VERSION ""

NS_ :

BS_:

BU_: MVS RCR_R RCR_L SNR ADAS ADAS_GW ENM THM CHR BAT BEV BEV_GW MET C_ECU C_ECU_GW

BO_ 2564481196 MVS18DAE0AC: 64 MVS
 SG_ MVS18DAE0AC_DIAG_DATA_EXT7 : 455|64@0+ (1,0) [0|1.844674407371E+19] ""  C_ECU_GW
 SG_ MVS18DAE0AC_DIAG_DATA_EXT6 : 391|64@0+ (1,0) [0|1.844674407371E+19] ""  C_ECU_GW
 SG_ MVS18DAE0AC_DIAG_DATA_EXT5 : 327|64@0+ (1,0) [0|1.844674407371E+19] ""  C_ECU_GW
 SG_ MVS18DAE0AC_DIAG_DATA_EXT4 : 263|64@0+ (1,0) [0|1.844674407371E+19] ""  C_ECU_GW
 SG_ MVS18DAE0AC_DIAG_DATA_EXT3 : 199|64@0+ (1,0) [0|1.844674407371E+19] ""  C_ECU_GW
 SG_ MVS18DAE0AC_DIAG_DATA_EXT2 : 135|64@0+ (1,0) [0|1.844674407371E+19] ""  C_ECU_GW
 SG_ MVS18DAE0AC_DIAG_DATA_EXT1 : 71|64@0+ (1,0) [0|1.844674407371E+19] ""  C_ECU_GW
 SG_ MVS18DAE0AC_DIAG_DATA : 7|64@0+ (1,0) [0|1.844674407371E+19] ""  C_ECU_GW

BO_ 2564467936 DNT18DAACE0: 64 C_ECU_GW
 SG_ DNT18DAACE0_DIAG_DATA_EXT7 : 455|64@0+ (1,0) [0|1.844674407371E+19] ""  MVS
 SG_ DNT18DAACE0_DIAG_DATA_EXT6 : 391|64@0+ (1,0) [0|1.844674407371E+19] ""  MVS
 SG_ DNT18DAACE0_DIAG_DATA_EXT5 : 327|64@0+ (1,0) [0|1.844674407371E+19] ""  MVS
 SG_ DNT18DAACE0_DIAG_DATA_EXT4 : 263|64@0+ (1,0) [0|1.844674407371E+19] ""  MVS
 SG_ DNT18DAACE0_DIAG_DATA_EXT3 : 199|64@0+ (1,0) [0|1.844674407371E+19] ""  MVS
 SG_ DNT18DAACE0_DIAG_DATA_EXT2 : 135|64@0+ (1,0) [0|1.844674407371E+19] ""  MVS
 SG_ DNT18DAACE0_DIAG_DATA_EXT1 : 71|64@0+ (1,0) [0|1.844674407371E+19] ""  MVS
 SG_ DNT18DAACE0_DIAG_DATA : 7|64@0+ (1,0) [0|1.844674407371E+19] ""  MVS

BO_ 2564481213 RCR18DAE0BD: 8 RCR_R
 SG_ RCR18DAE0BD_DIAG_DATA : 7|64@0+ (1,0) [0|1.844674407371E+19] ""  C_ECU_GW

BO_ 2564472288 DNT18DABDE0: 8 C_ECU_GW
 SG_ DNT18DABDE0_DIAG_DATA : 7|64@0+ (1,0) [0|1.844674407371E+19] ""  RCR_R

BO_ 2564481212 RCR18DAE0BC: 8 RCR_L
 SG_ RCR18DAE0BC_DIAG_DATA : 7|64@0+ (1,0) [0|1.844674407371E+19] ""  C_ECU_GW

BO_ 2564472032 DNT18DABCE0: 8 C_ECU_GW
 SG_ DNT18DABCE0_DIAG_DATA : 7|64@0+ (1,0) [0|1.844674407371E+19] ""  RCR_L

BO_ 2564481195 SNR18DAE0AB: 64 SNR
 SG_ SNR18DAE0AB_DIAG_DATA_EXT7 : 455|64@0+ (1,0) [0|1.844674407371E+19] ""  C_ECU_GW
 SG_ SNR18DAE0AB_DIAG_DATA_EXT6 : 391|64@0+ (1,0) [0|1.844674407371E+19] ""  C_ECU_GW
 SG_ SNR18DAE0AB_DIAG_DATA_EXT5 : 327|64@0+ (1,0) [0|1.844674407371E+19] ""  C_ECU_GW
 SG_ SNR18DAE0AB_DIAG_DATA_EXT4 : 263|64@0+ (1,0) [0|1.844674407371E+19] ""  C_ECU_GW
 SG_ SNR18DAE0AB_DIAG_DATA_EXT3 : 199|64@0+ (1,0) [0|1.844674407371E+19] ""  C_ECU_GW
 SG_ SNR18DAE0AB_DIAG_DATA_EXT2 : 135|64@0+ (1,0) [0|1.844674407371E+19] ""  C_ECU_GW
 SG_ SNR18DAE0AB_DIAG_DATA_EXT1 : 71|64@0+ (1,0) [0|1.844674407371E+19] ""  C_ECU_GW
 SG_ SNR18DAE0AB_DIAG_DATA : 7|64@0+ (1,0) [0|1.844674407371E+19] ""  C_ECU_GW

BO_ 2564467680 DNT18DAABE0: 64 C_ECU_GW
 SG_ DNT18DAABE0_DIAG_DATA_EXT7 : 455|64@0+ (1,0) [0|1.844674407371E+19] ""  SNR
 SG_ DNT18DAABE0_DIAG_DATA_EXT6 : 391|64@0+ (1,0) [0|1.844674407371E+19] ""  SNR
 SG_ DNT18DAABE0_DIAG_DATA_EXT5 : 327|64@0+ (1,0) [0|1.844674407371E+19] ""  SNR
 SG_ DNT18DAABE0_DIAG_DATA_EXT4 : 263|64@0+ (1,0) [0|1.844674407371E+19] ""  SNR
 SG_ DNT18DAABE0_DIAG_DATA_EXT3 : 199|64@0+ (1,0) [0|1.844674407371E+19] ""  SNR
 SG_ DNT18DAABE0_DIAG_DATA_EXT2 : 135|64@0+ (1,0) [0|1.844674407371E+19] ""  SNR
 SG_ DNT18DAABE0_DIAG_DATA_EXT1 : 71|64@0+ (1,0) [0|1.844674407371E+19] ""  SNR
 SG_ DNT18DAABE0_DIAG_DATA : 7|64@0+ (1,0) [0|1.844674407371E+19] ""  SNR

BO_ 2564481047 MET18DAE017: 64 MET
 SG_ MET18DAE017_DIAG_DATA_EXT7 : 455|64@0+ (1,0) [0|1.844674407371E+19] ""  C_ECU_GW
 SG_ MET18DAE017_DIAG_DATA_EXT6 : 391|64@0+ (1,0) [0|1.844674407371E+19] ""  C_ECU_GW
 SG_ MET18DAE017_DIAG_DATA_EXT5 : 327|64@0+ (1,0) [0|1.844674407371E+19] ""  C_ECU_GW
 SG_ MET18DAE017_DIAG_DATA_EXT4 : 263|64@0+ (1,0) [0|1.844674407371E+19] ""  C_ECU_GW
 SG_ MET18DAE017_DIAG_DATA_EXT3 : 199|64@0+ (1,0) [0|1.844674407371E+19] ""  C_ECU_GW
 SG_ MET18DAE017_DIAG_DATA_EXT2 : 135|64@0+ (1,0) [0|1.844674407371E+19] ""  C_ECU_GW
 SG_ MET18DAE017_DIAG_DATA_EXT1 : 71|64@0+ (1,0) [0|1.844674407371E+19] ""  C_ECU_GW
 SG_ MET18DAE017_DIAG_DATA : 7|64@0+ (1,0) [0|1.844674407371E+19] ""  C_ECU_GW

BO_ 2564429792 DNT18DA17E0: 64 C_ECU_GW
 SG_ DNT18DA17E0_DIAG_DATA_EXT7 : 455|64@0+ (1,0) [0|1.844674407371E+19] ""  MET
 SG_ DNT18DA17E0_DIAG_DATA_EXT6 : 391|64@0+ (1,0) [0|1.844674407371E+19] ""  MET
 SG_ DNT18DA17E0_DIAG_DATA_EXT5 : 327|64@0+ (1,0) [0|1.844674407371E+19] ""  MET
 SG_ DNT18DA17E0_DIAG_DATA_EXT4 : 263|64@0+ (1,0) [0|1.844674407371E+19] ""  MET
 SG_ DNT18DA17E0_DIAG_DATA_EXT3 : 199|64@0+ (1,0) [0|1.844674407371E+19] ""  MET
 SG_ DNT18DA17E0_DIAG_DATA_EXT2 : 135|64@0+ (1,0) [0|1.844674407371E+19] ""  MET
 SG_ DNT18DA17E0_DIAG_DATA_EXT1 : 71|64@0+ (1,0) [0|1.844674407371E+19] ""  MET
 SG_ DNT18DA17E0_DIAG_DATA : 7|64@0+ (1,0) [0|1.844674407371E+19] ""  MET

BO_ 2564550625 CECU18DBEFE1: 8 C_ECU
 SG_ CECU18DBEFE1_DIAG_DATA : 7|64@0+ (1,0) [0|1.844674407371E+19] ""  MVS,RCR_R,RCR_L,SNR,ADAS,MET

BO_ 2564550624 DNT18DBEFE0: 8 C_ECU_GW
 SG_ DNT18DBEFE0_DIAG_DATA : 7|64@0+ (1,0) [0|1.844674407371E+19] ""  MVS,RCR_R,RCR_L,SNR,MET

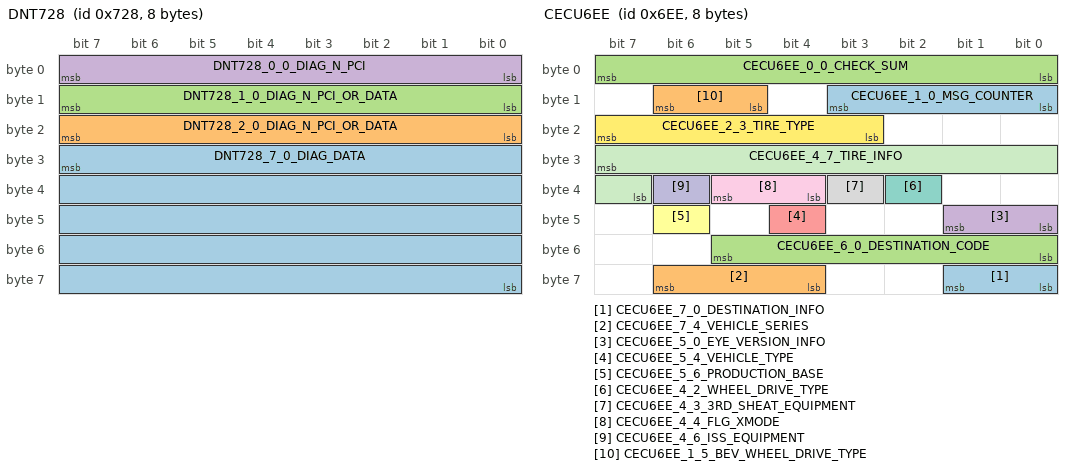
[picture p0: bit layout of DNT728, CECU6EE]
BO_ 1832 DNT728: 8 C_ECU_GW
 SG_ DNT728_7_0_DIAG_DATA : 31|40@0+ (1,0) [0|1099511627775] "" Vector__XXX
 SG_ DNT728_2_0_DIAG_N_PCI_OR_DATA : 23|8@0+ (1,0) [0|255] "" Vector__XXX
 SG_ DNT728_1_0_DIAG_N_PCI_OR_DATA : 15|8@0+ (1,0) [0|255] "" Vector__XXX
 SG_ DNT728_0_0_DIAG_N_PCI : 7|8@0+ (1,0) [0|255] "" Vector__XXX

BO_ 2564481303 MET18DAE117: 64 MET
 SG_ MET18DAE117_DIAG_DATA_EXT7 : 455|64@0+ (1,0) [0|1.844674407371E+19] ""  C_ECU
 SG_ MET18DAE117_DIAG_DATA_EXT6 : 391|64@0+ (1,0) [0|1.844674407371E+19] ""  C_ECU
 SG_ MET18DAE117_DIAG_DATA_EXT5 : 327|64@0+ (1,0) [0|1.844674407371E+19] ""  C_ECU
 SG_ MET18DAE117_DIAG_DATA_EXT4 : 263|64@0+ (1,0) [0|1.844674407371E+19] ""  C_ECU
 SG_ MET18DAE117_DIAG_DATA_EXT3 : 199|64@0+ (1,0) [0|1.844674407371E+19] ""  C_ECU
 SG_ MET18DAE117_DIAG_DATA_EXT2 : 135|64@0+ (1,0) [0|1.844674407371E+19] ""  C_ECU
 SG_ MET18DAE117_DIAG_DATA_EXT1 : 71|64@0+ (1,0) [0|1.844674407371E+19] ""  C_ECU
 SG_ MET18DAE117_DIAG_DATA : 7|64@0+ (1,0) [0|1.844674407371E+19] ""  C_ECU

BO_ 2564429793 CECU18DA17E1: 64 C_ECU
 SG_ CECU18DA17E1_DIAG_DATA_EXT7 : 455|64@0+ (1,0) [0|1.844674407371E+19] ""  MET
 SG_ CECU18DA17E1_DIAG_DATA_EXT6 : 391|64@0+ (1,0) [0|1.844674407371E+19] ""  MET
 SG_ CECU18DA17E1_DIAG_DATA_EXT5 : 327|64@0+ (1,0) [0|1.844674407371E+19] ""  MET
 SG_ CECU18DA17E1_DIAG_DATA_EXT4 : 263|64@0+ (1,0) [0|1.844674407371E+19] ""  MET
 SG_ CECU18DA17E1_DIAG_DATA_EXT3 : 199|64@0+ (1,0) [0|1.844674407371E+19] ""  MET
 SG_ CECU18DA17E1_DIAG_DATA_EXT2 : 135|64@0+ (1,0) [0|1.844674407371E+19] ""  MET
 SG_ CECU18DA17E1_DIAG_DATA_EXT1 : 71|64@0+ (1,0) [0|1.844674407371E+19] ""  MET
 SG_ CECU18DA17E1_DIAG_DATA : 7|64@0+ (1,0) [0|1.844674407371E+19] ""  MET

BO_ 2564481452 MVS18DAE1AC: 64 MVS
 SG_ MVS18DAE1AC_DIAG_DATA_EXT7 : 455|64@0+ (1,0) [0|1.844674407371E+19] ""  C_ECU
 SG_ MVS18DAE1AC_DIAG_DATA_EXT6 : 391|64@0+ (1,0) [0|1.844674407371E+19] ""  C_ECU
 SG_ MVS18DAE1AC_DIAG_DATA_EXT5 : 327|64@0+ (1,0) [0|1.844674407371E+19] ""  C_ECU
 SG_ MVS18DAE1AC_DIAG_DATA_EXT4 : 263|64@0+ (1,0) [0|1.844674407371E+19] ""  C_ECU
 SG_ MVS18DAE1AC_DIAG_DATA_EXT3 : 199|64@0+ (1,0) [0|1.844674407371E+19] ""  C_ECU
 SG_ MVS18DAE1AC_DIAG_DATA_EXT2 : 135|64@0+ (1,0) [0|1.844674407371E+19] ""  C_ECU
 SG_ MVS18DAE1AC_DIAG_DATA_EXT1 : 71|64@0+ (1,0) [0|1.844674407371E+19] ""  C_ECU
 SG_ MVS18DAE1AC_DIAG_DATA : 7|64@0+ (1,0) [0|1.844674407371E+19] ""  C_ECU

BO_ 2564467937 CECU18DAACE1: 64 C_ECU
 SG_ CECU18DAACE1_DIAG_DATA_EXT7 : 455|64@0+ (1,0) [0|1.844674407371E+19] ""  MVS
 SG_ CECU18DAACE1_DIAG_DATA_EXT6 : 391|64@0+ (1,0) [0|1.844674407371E+19] ""  MVS
 SG_ CECU18DAACE1_DIAG_DATA_EXT5 : 327|64@0+ (1,0) [0|1.844674407371E+19] ""  MVS
 SG_ CECU18DAACE1_DIAG_DATA_EXT4 : 263|64@0+ (1,0) [0|1.844674407371E+19] ""  MVS
 SG_ CECU18DAACE1_DIAG_DATA_EXT3 : 199|64@0+ (1,0) [0|1.844674407371E+19] ""  MVS
 SG_ CECU18DAACE1_DIAG_DATA_EXT2 : 135|64@0+ (1,0) [0|1.844674407371E+19] ""  MVS
 SG_ CECU18DAACE1_DIAG_DATA_EXT1 : 71|64@0+ (1,0) [0|1.844674407371E+19] ""  MVS
 SG_ CECU18DAACE1_DIAG_DATA : 7|64@0+ (1,0) [0|1.844674407371E+19] ""  MVS

BO_ 2564481451 SNR18DAE1AB: 64 SNR
 SG_ SNR18DAE1AB_DIAG_DATA_EXT7 : 455|64@0+ (1,0) [0|1.844674407371E+19] ""  C_ECU
 SG_ SNR18DAE1AB_DIAG_DATA_EXT6 : 391|64@0+ (1,0) [0|1.844674407371E+19] ""  C_ECU
 SG_ SNR18DAE1AB_DIAG_DATA_EXT5 : 327|64@0+ (1,0) [0|1.844674407371E+19] ""  C_ECU
 SG_ SNR18DAE1AB_DIAG_DATA_EXT4 : 263|64@0+ (1,0) [0|1.844674407371E+19] ""  C_ECU
 SG_ SNR18DAE1AB_DIAG_DATA_EXT3 : 199|64@0+ (1,0) [0|1.844674407371E+19] ""  C_ECU
 SG_ SNR18DAE1AB_DIAG_DATA_EXT2 : 135|64@0+ (1,0) [0|1.844674407371E+19] ""  C_ECU
 SG_ SNR18DAE1AB_DIAG_DATA_EXT1 : 71|64@0+ (1,0) [0|1.844674407371E+19] ""  C_ECU
 SG_ SNR18DAE1AB_DIAG_DATA : 7|64@0+ (1,0) [0|1.844674407371E+19] ""  C_ECU

BO_ 2564467681 CECU18DAABE1: 64 C_ECU
 SG_ CECU18DAABE1_DIAG_DATA_EXT7 : 455|64@0+ (1,0) [0|1.844674407371E+19] ""  SNR
 SG_ CECU18DAABE1_DIAG_DATA_EXT6 : 391|64@0+ (1,0) [0|1.844674407371E+19] ""  SNR
 SG_ CECU18DAABE1_DIAG_DATA_EXT5 : 327|64@0+ (1,0) [0|1.844674407371E+19] ""  SNR
 SG_ CECU18DAABE1_DIAG_DATA_EXT4 : 263|64@0+ (1,0) [0|1.844674407371E+19] ""  SNR
 SG_ CECU18DAABE1_DIAG_DATA_EXT3 : 199|64@0+ (1,0) [0|1.844674407371E+19] ""  SNR
 SG_ CECU18DAABE1_DIAG_DATA_EXT2 : 135|64@0+ (1,0) [0|1.844674407371E+19] ""  SNR
 SG_ CECU18DAABE1_DIAG_DATA_EXT1 : 71|64@0+ (1,0) [0|1.844674407371E+19] ""  SNR
 SG_ CECU18DAABE1_DIAG_DATA : 7|64@0+ (1,0) [0|1.844674407371E+19] ""  SNR

BO_ 2564481469 RCR18DAE1BD: 8 RCR_R
 SG_ RCR18DAE1BD_DIAG_DATA : 7|64@0+ (1,0) [0|1.844674407371E+19] ""  C_ECU

BO_ 2564472289 CECU18DABDE1: 8 C_ECU
 SG_ CECU18DABDE1_DIAG_DATA : 7|64@0+ (1,0) [0|1.844674407371E+19] ""  RCR_R

BO_ 2564481468 RCR18DAE1BC: 8 RCR_L
 SG_ RCR18DAE1BC_DIAG_DATA : 7|64@0+ (1,0) [0|1.844674407371E+19] ""  C_ECU

BO_ 2564472033 CECU18DABCE1: 8 C_ECU
 SG_ CECU18DABCE1_DIAG_DATA : 7|64@0+ (1,0) [0|1.844674407371E+19] ""  RCR_L

BO_ 1774 CECU6EE: 8 C_ECU
 SG_ CECU6EE_7_0_DESTINATION_INFO : 57|2@0+ (1,0) [0|3] ""  SNR
 SG_ CECU6EE_7_4_VEHICLE_SERIES : 62|3@0+ (1,0) [0|7] ""  RCR_R,RCR_L,SNR,ADAS
 SG_ CECU6EE_6_0_DESTINATION_CODE : 53|6@0+ (1,0) [0|37] ""  RCR_R,RCR_L,SNR,ADAS,CHR
 SG_ CECU6EE_5_0_EYE_VERSION_INFO : 41|2@0+ (1,0) [0|3] "" Vector__XXX
 SG_ CECU6EE_5_4_VEHICLE_TYPE : 44|1@0+ (1,0) [0|1] ""  RCR_R,RCR_L,SNR
 SG_ CECU6EE_5_6_PRODUCTION_BASE : 46|1@0+ (1,0) [0|1] "" Vector__XXX
 SG_ CECU6EE_4_2_WHEEL_DRIVE_TYPE : 34|1@0+ (1,0) [0|1] ""  SNR
 SG_ CECU6EE_4_3_3RD_SHEAT_EQUIPMENT : 35|1@0+ (1,0) [0|1] "" Vector__XXX
 SG_ CECU6EE_4_4_FLG_XMODE : 37|2@0+ (1,0) [0|3] "" Vector__XXX
 SG_ CECU6EE_4_6_ISS_EQUIPMENT : 38|1@0+ (1,0) [0|1] ""  SNR,ADAS
 SG_ CECU6EE_4_7_TIRE_INFO : 31|9@0+ (1,0) [0|381] ""  SNR
 SG_ CECU6EE_2_3_TIRE_TYPE : 23|5@0+ (1,0) [0|511] "" Vector__XXX
 SG_ CECU6EE_1_0_MSG_COUNTER : 11|4@0+ (1,0) [0|15] ""  RCR_R,RCR_L,SNR,ADAS,CHR
 SG_ CECU6EE_1_5_BEV_WHEEL_DRIVE_TYPE : 14|2@0+ (1,0) [0|3] ""  ADAS
 SG_ CECU6EE_0_0_CHECK_SUM : 7|8@0+ (1,0) [0|255] ""  RCR_R,RCR_L,SNR,ADAS,CHR

BO_ 1773 CECU6ED: 8 C_ECU
 SG_ CECU6ED_7_0_VEHICLE_TYPE_DETAIL : 59|4@0+ (1,0) [0|15] ""  MVS,RCR_R,RCR_L,SNR,ADAS
 SG_ CECU6ED_7_7_STEERHEAT_EQUIPMENT : 63|1@0+ (1,0) [0|1] "" Vector__XXX
 SG_ CECU6ED_6_0_SRH_EQUIPMENT : 48|1@0+ (1,0) [0|1] "" Vector__XXX
 SG_ CECU6ED_6_1_EMBENAVI_EQUIPMENT : 49|1@0+ (1,0) [0|1] "" Vector__XXX
 SG_ CECU6ED_6_2_RAB_EQUIPMENT_INFO : 50|1@0+ (1,0) [0|1] "" Vector__XXX
 SG_ CECU6ED_6_3_RRHEACON_EQUIPMENT : 51|1@0+ (1,0) [0|1] "" Vector__XXX
 SG_ CECU6ED_6_4_AUTOMIRROR_EQUIPMENT : 52|1@0+ (1,0) [0|1] "" Vector__XXX
 SG_ CECU6ED_6_5_SXMANTENNA_EQUIPMENT : 53|1@0+ (1,0) [0|1] "" Vector__XXX
 SG_ CECU6ED_6_7_SPORTSCONT_EQUIPMENT : 55|1@0+ (1,0) [0|1] "" Vector__XXX
 SG_ CECU6ED_5_0_TRANSMISSION_TYPE : 40|1@0+ (1,0) [0|1] ""  MVS,SNR
 SG_ CECU6ED_5_2_KICKSENSOR_EQUIPMENT : 42|1@0+ (1,0) [0|1] "" Vector__XXX
 SG_ CECU6ED_5_3_RRSEAT_OCCUPANT : 43|1@0+ (1,0) [0|1] "" Vector__XXX
 SG_ CECU6ED_5_4_HANDLE : 44|1@0+ (1,0) [0|1] ""  MVS,ADAS
 SG_ CECU6ED_5_5_RRWIPER_EQUIPMENT : 45|1@0+ (1,0) [0|1] "" Vector__XXX
 SG_ CECU6ED_5_7_SRM_EQUIPMENT : 47|1@0+ (1,0) [0|1] "" Vector__XXX
 SG_ CECU6ED_4_0_VEHICLE_HEIGHT : 34|3@0+ (1,0) [0|7] ""  MVS,RCR_R,RCR_L,SNR,ADAS
 SG_ CECU6ED_4_4_SEATHEATER_EQUIPMENT : 37|2@0+ (1,0) [0|3] "" Vector__XXX
 SG_ CECU6ED_3_0_YEAR_CHANGE : 27|4@0+ (1,0) [0|15] ""  RCR_R,RCR_L
 SG_ CECU6ED_3_4_HEV_INFO : 30|3@0+ (1,0) [0|7] ""  MVS,RCR_R,RCR_L,SNR,ADAS
 SG_ CECU6ED_2_0_RRDIFF_TEMPLAMP_INFO : 17|2@0+ (1,0) [0|3] "" Vector__XXX
 SG_ CECU6ED_2_2_AHL_EQUIPMENT : 19|2@0+ (1,0) [0|3] "" Vector__XXX
 SG_ CECU6ED_2_4_LSD_TYPE : 23|4@0+ (1,0) [0|15] "" Vector__XXX
 SG_ CECU6ED_1_0_MSG_COUNTER : 11|4@0+ (1,0) [0|15] ""  MVS,RCR_R,RCR_L,SNR,ADAS
 SG_ CECU6ED_1_5_WARNINGBOX_EQUIPMENT : 13|1@0+ (1,0) [0|1] "" Vector__XXX
 SG_ CECU6ED_0_0_CHECK_SUM : 7|8@0+ (1,0) [0|255] ""  MVS,RCR_R,RCR_L,SNR,ADAS

BO_ 1772 CECU6EC: 8 C_ECU
 SG_ CECU6EC_7_0_ACC_B_EQUIPMENT : 63|8@0+ (1,0) [0|255] "" Vector__XXX
 SG_ CECU6EC_6_0_SMT_EQUIPMENT : 48|1@0+ (1,0) [0|1] "" Vector__XXX
 SG_ CECU6EC_6_1_DCCD_EQUIPMENT : 49|1@0+ (1,0) [0|1] "" Vector__XXX
 SG_ CECU6EC_6_2_PRG_EQUIPMENT : 50|1@0+ (1,0) [0|1] "" Vector__XXX
 SG_ CECU6EC_6_3_DKY_EQUIPMENT : 51|1@0+ (1,0) [0|1] "" Vector__XXX
 SG_ CECU6EC_6_4_PSC_EQUIPMENT : 52|1@0+ (1,0) [0|1] "" Vector__XXX
 SG_ CECU6EC_6_5_ILLUM_EQUIPMENT : 53|1@0+ (1,0) [0|1] "" Vector__XXX
 SG_ CECU6EC_6_6_CAB_EQUIPMENT : 54|1@0+ (1,0) [0|1] "" Vector__XXX
 SG_ CECU6EC_6_7_ACC_A_EQUIPMENT : 55|1@0+ (1,0) [0|1] "" Vector__XXX
 SG_ CECU6EC_5_0_CCU_EQUIPMENT : 40|1@0+ (1,0) [0|1] ""  SNR
 SG_ CECU6EC_5_1_EAM_EQUIPMENT : 41|1@0+ (1,0) [0|1] "" Vector__XXX
 SG_ CECU6EC_5_2_RCR_L_EQUIPMENT : 42|1@0+ (1,0) [0|1] ""  MVS
 SG_ CECU6EC_5_3_RCR_R_EQUIPMENT : 43|1@0+ (1,0) [0|1] "" Vector__XXX
 SG_ CECU6EC_5_4_FCR_L_EQUIPMENT : 44|1@0+ (1,0) [0|1] ""  ADAS
 SG_ CECU6EC_5_5_FCR_R_EQUIPMENT : 45|1@0+ (1,0) [0|1] ""  ADAS
 SG_ CECU6EC_5_6_VSS_EQUIPMENT : 46|1@0+ (1,0) [0|1] "" Vector__XXX
 SG_ CECU6EC_5_7_RES_EQUIPMENT : 47|1@0+ (1,0) [0|1] "" Vector__XXX
 SG_ CECU6EC_4_0_LCT_EQUIPMENT : 32|1@0+ (1,0) [0|1] "" Vector__XXX
 SG_ CECU6EC_4_1_DAM_EQUIPMENT : 33|1@0+ (1,0) [0|1] "" Vector__XXX
 SG_ CECU6EC_4_2_MVS_EQUIPMENT : 34|1@0+ (1,0) [0|1] "" Vector__XXX
 SG_ CECU6EC_4_3_TCU_EQUIPMENT : 35|1@0+ (1,0) [0|1] ""  SNR
 SG_ CECU6EC_4_4_TPM_EQUIPMENT : 36|1@0+ (1,0) [0|1] "" Vector__XXX
 SG_ CECU6EC_4_5_DCM_EQUIPMENT : 37|1@0+ (1,0) [0|1] "" Vector__XXX
 SG_ CECU6EC_4_6_MED_EQUIPMENT : 38|1@0+ (1,0) [0|1] "" Vector__XXX
 SG_ CECU6EC_4_7_MEP_EQUIPMENT : 39|1@0+ (1,0) [0|1] "" Vector__XXX
 SG_ CECU6EC_3_0_DATA_STATE : 24|1@0+ (1,0) [0|1] ""  MVS,RCR_R,RCR_L,SNR,ADAS
 SG_ CECU6EC_3_1_EYE_EQUIPMENT : 25|1@0+ (1,0) [0|1] ""  MVS,RCR_R,RCR_L
 SG_ CECU6EC_3_2_HEV_EQUIPMENT : 26|1@0+ (1,0) [0|1] ""  SNR
 SG_ CECU6EC_3_3_SNR_EQUIPMENT : 27|1@0+ (1,0) [0|1] ""  ADAS
 SG_ CECU6EC_3_4_EPB_EQUIPMENT : 28|1@0+ (1,0) [0|1] ""  MVS,SNR,ADAS
 SG_ CECU6EC_3_5_DMS_EQUIPMENT : 29|1@0+ (1,0) [0|1] ""  ADAS
 SG_ CECU6EC_3_6_BST_EQUIPMENT : 30|1@0+ (1,0) [0|1] ""  ADAS
 SG_ CECU6EC_3_7_MCA_EQUIPMENT : 31|1@0+ (1,0) [0|1] ""  ADAS
 SG_ CECU6EC_1_0_MSG_COUNTER : 11|4@0+ (1,0) [0|15] ""  MVS,RCR_R,RCR_L,SNR,ADAS
 SG_ CECU6EC_0_0_CHECK_SUM : 7|8@0+ (1,0) [0|255] ""  MVS,RCR_R,RCR_L,SNR,ADAS

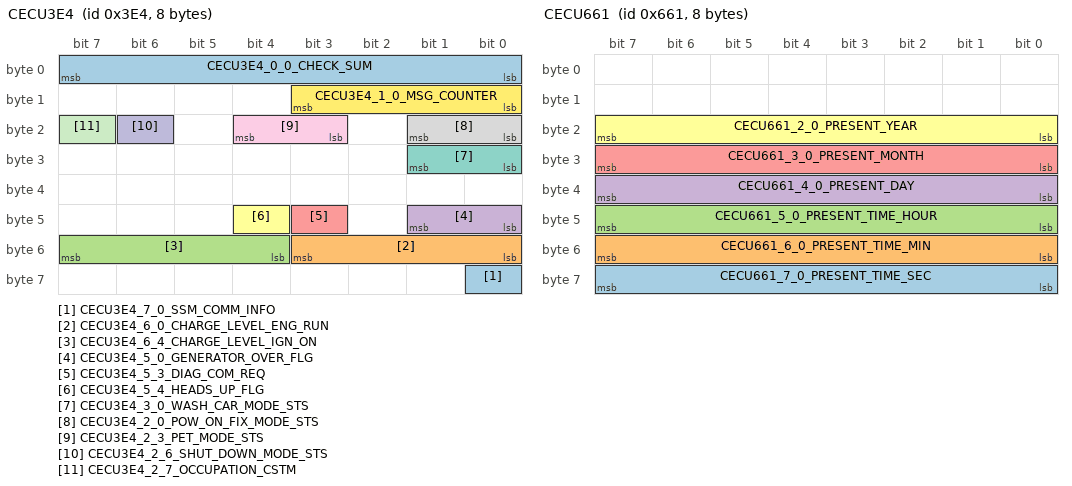
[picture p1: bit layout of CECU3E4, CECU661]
BO_ 996 CECU3E4: 8 Vector__XXX
 SG_ CECU3E4_7_0_SSM_COMM_INFO : 56|1@0+ (1,0) [0|1] "" Vector__XXX
 SG_ CECU3E4_6_0_CHARGE_LEVEL_ENG_RUN : 51|4@0+ (1,0) [0|9] "" Vector__XXX
 SG_ CECU3E4_6_4_CHARGE_LEVEL_IGN_ON : 55|4@0+ (1,0) [0|9] ""  MET
 SG_ CECU3E4_5_0_GENERATOR_OVER_FLG : 41|2@0+ (1,0) [0|3] "" Vector__XXX
 SG_ CECU3E4_5_3_DIAG_COM_REQ : 43|1@0+ (1,0) [0|1] "" Vector__XXX
 SG_ CECU3E4_5_4_HEADS_UP_FLG : 44|1@0+ (1,0) [0|1] ""  MET
 SG_ CECU3E4_3_0_WASH_CAR_MODE_STS : 25|2@0+ (1,0) [0|3] "" Vector__XXX
 SG_ CECU3E4_2_0_POW_ON_FIX_MODE_STS : 17|2@0+ (1,0) [0|3] "" Vector__XXX
 SG_ CECU3E4_2_3_PET_MODE_STS : 20|2@0+ (1,0) [0|3] "" Vector__XXX
 SG_ CECU3E4_2_6_SHUT_DOWN_MODE_STS : 22|1@0+ (1,0) [0|1] "" Vector__XXX
 SG_ CECU3E4_2_7_OCCUPATION_CSTM : 23|1@0+ (1,0) [0|1] "" Vector__XXX
 SG_ CECU3E4_1_0_MSG_COUNTER : 11|4@0+ (1,0) [0|15] ""  MET
 SG_ CECU3E4_0_0_CHECK_SUM : 7|8@0+ (1,0) [0|255] ""  MET

BO_ 1280 CGW500: 8 C_ECU
 SG_ CGW500_1_4_ActiveWakeUpBit : 12|1@1+ (1,0) [0|1] ""  MET
 SG_ CGW500_0_0_SourceNodeID : 0|8@1+ (1,0) [0|255] ""  MET

BO_ 1633 CECU661: 8 C_ECU
 SG_ CECU661_7_0_PRESENT_TIME_SEC : 63|8@0+ (1,0) [0|89] "s"  MVS,RCR_R,RCR_L,SNR,BAT,MET
 SG_ CECU661_6_0_PRESENT_TIME_MIN : 55|8@0+ (1,0) [0|89] "m"  MVS,RCR_R,RCR_L,SNR,BAT,MET
 SG_ CECU661_5_0_PRESENT_TIME_HOUR : 47|8@0+ (1,0) [0|35] "h"  MVS,RCR_R,RCR_L,SNR,BAT,MET
 SG_ CECU661_4_0_PRESENT_DAY : 39|8@0+ (1,0) [1|49] "Day"  MVS,RCR_R,RCR_L,SNR,BAT,MET
 SG_ CECU661_3_0_PRESENT_MONTH : 31|8@0+ (1,0) [1|18] "Month"  MVS,RCR_R,RCR_L,SNR,BAT,MET
 SG_ CECU661_2_0_PRESENT_YEAR : 23|8@0+ (1,0) [0|153] "Year"  MVS,RCR_R,RCR_L,SNR,BAT,MET

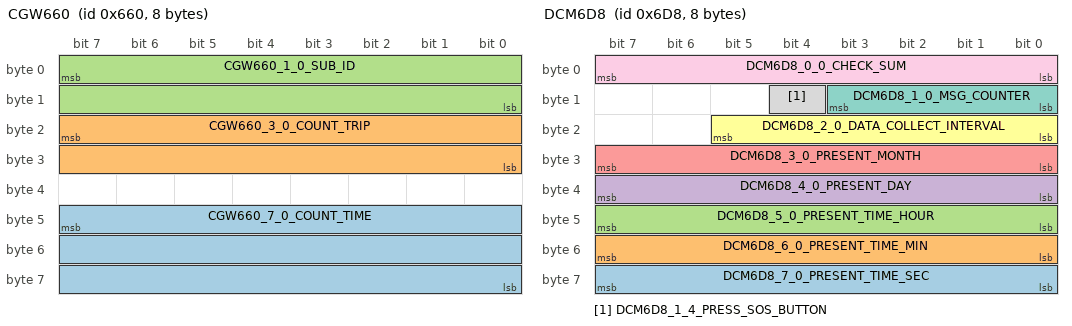
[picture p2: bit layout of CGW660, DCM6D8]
BO_ 1632 CGW660: 8 C_ECU
 SG_ CGW660_7_0_COUNT_TIME : 47|24@0+ (100,0) [0|1677721400] "ms"  MVS,RCR_R,RCR_L,SNR,MET
 SG_ CGW660_3_0_COUNT_TRIP : 23|16@0+ (1,0) [0|65534] "trip"  MVS,RCR_R,RCR_L,SNR,MET
 SG_ CGW660_1_0_SUB_ID : 7|16@0+ (1,0) [0|65535] "" Vector__XXX

BO_ 1752 DCM6D8: 8 C_ECU_GW
 SG_ DCM6D8_7_0_PRESENT_TIME_SEC : 56|8@1+ (1,0) [0|255] "s" Vector__XXX
 SG_ DCM6D8_6_0_PRESENT_TIME_MIN : 48|8@1+ (1,0) [0|255] "m" Vector__XXX
 SG_ DCM6D8_5_0_PRESENT_TIME_HOUR : 40|8@1+ (1,0) [0|255] "h" Vector__XXX
 SG_ DCM6D8_4_0_PRESENT_DAY : 32|8@1+ (1,0) [0|255] "Day" Vector__XXX
 SG_ DCM6D8_3_0_PRESENT_MONTH : 24|8@1+ (1,0) [0|255] "Month" Vector__XXX
 SG_ DCM6D8_2_0_DATA_COLLECT_INTERVAL : 16|6@1+ (1,0) [0|63] "min"  BEV
 SG_ DCM6D8_1_0_MSG_COUNTER : 8|4@1+ (1,0) [0|15] "" Vector__XXX
 SG_ DCM6D8_1_4_PRESS_SOS_BUTTON : 12|1@1+ (1,0) [0|1] "" Vector__XXX
 SG_ DCM6D8_0_0_CHECK_SUM : 0|8@1+ (1,0) [0|255] "" Vector__XXX

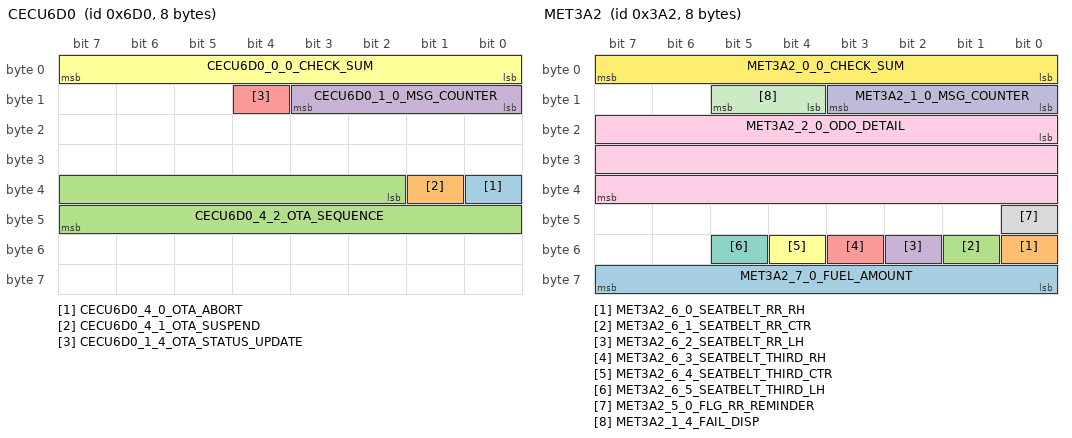
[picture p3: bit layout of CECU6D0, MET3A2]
BO_ 1744 CECU6D0: 8 C_ECU
 SG_ CECU6D0_4_0_OTA_ABORT : 32|1@1+ (1,0) [0|1] "" Vector__XXX
 SG_ CECU6D0_4_1_OTA_SUSPEND : 33|1@1+ (1,0) [0|1] "" Vector__XXX
 SG_ CECU6D0_4_2_OTA_SEQUENCE : 34|14@1+ (1,0) [0|33170] "" Vector__XXX
 SG_ CECU6D0_1_0_MSG_COUNTER : 8|4@1+ (1,0) [0|15] "" Vector__XXX
 SG_ CECU6D0_1_4_OTA_STATUS_UPDATE : 12|1@1+ (1,0) [0|0] "" Vector__XXX
 SG_ CECU6D0_0_0_CHECK_SUM : 0|8@1+ (1,0) [0|255] "" Vector__XXX

BO_ 1749 CECU6D5: 8 C_ECU
 SG_ CECU6D5_6_0_CSTM_FMHD : 48|3@1+ (1,0) [0|7] "" Vector__XXX
 SG_ CECU6D5_5_0_CSTM_WRH : 40|1@1+ (1,0) [0|1] "" Vector__XXX
 SG_ CECU6D5_5_1_CSTM_LMHD : 41|2@1+ (1,0) [0|3] "" Vector__XXX
 SG_ CECU6D5_5_3 : 43|2@1+ (1,0) [0|3] "" Vector__XXX
 SG_ CECU6D5_5_5_CSTM_HBA : 45|2@1+ (1,0) [0|3] ""  ADAS
 SG_ CECU6D5_5_7_ADB_ACTIVE : 47|1@1+ (1,0) [0|1] ""  ADAS,MET
 SG_ CECU6D5_4_0_JUDGE_ILL : 32|1@1+ (1,0) [0|1] "" Vector__XXX
 SG_ CECU6D5_4_1_HEADLAMP_AUTO_SW : 33|1@1+ (1,0) [0|1] ""  ADAS
 SG_ CECU6D5_4_2_IND_ACTIVE_HBA : 34|2@1+ (1,0) [0|3] ""  MET
 SG_ CECU6D5_4_4_FGT_LGTOFF_WARNING : 36|1@1+ (1,0) [0|1] "" Vector__XXX
 SG_ CECU6D5_3_0_CRN_R_REQ : 24|2@1+ (1,0) [0|3] "" Vector__XXX
 SG_ CECU6D5_3_2_CRN_L_REQ : 26|2@1+ (1,0) [0|3] "" Vector__XXX
 SG_ CECU6D5_3_4_FMH : 28|1@1+ (1,0) [0|1] "" Vector__XXX
 SG_ CECU6D5_3_5_LMH : 29|1@1+ (1,0) [0|1] "" Vector__XXX
 SG_ CECU6D5_2_0_LGT_1 : 16|1@1+ (1,0) [0|1] "" Vector__XXX
 SG_ CECU6D5_2_1_LGT_LO : 17|1@1+ (1,0) [0|1] "" Vector__XXX
 SG_ CECU6D5_2_2_LGT_HI : 18|2@1+ (1,0) [0|1] "" Vector__XXX
 SG_ CECU6D5_2_4_FFOG_RELAY_REQ : 20|1@1+ (1,0) [0|1] "" Vector__XXX
 SG_ CECU6D5_2_5_RFOG_RELAY_REQ : 21|1@1+ (1,0) [0|1] "" Vector__XXX
 SG_ CECU6D5_2_6_LGT_DRL : 22|1@1+ (1,0) [0|1] "" Vector__XXX
 SG_ CECU6D5_1_0_MSG_COUNTER : 8|4@1+ (1,0) [0|15] ""  ADAS
 SG_ CECU6D5_0_0_CHECK_SUM : 0|8@1+ (1,0) [0|255] ""  ADAS

BO_ 1699 CECU6A3: 8 C_ECU
 SG_ CECU6A3_7_4_ACC4ONOFF : 60|1@1+ (1,0) [0|0] "" Vector__XXX
 SG_ CECU6A3_7_5_ACC3ONOFF : 61|1@1+ (1,0) [0|0] "" Vector__XXX
 SG_ CECU6A3_7_6_ACC2ONOFF : 62|1@1+ (1,0) [0|0] "" Vector__XXX
 SG_ CECU6A3_7_7_ACC1ONOFF : 63|1@1+ (1,0) [0|0] "" Vector__XXX
 SG_ CECU6A3_6_0_CAB_SYSC_EQUIPMENT : 48|1@1+ (1,0) [0|0] "" Vector__XXX
 SG_ CECU6A3_6_1_CAB_SYSB_EQUIPMENT : 49|1@1+ (1,0) [0|0] "" Vector__XXX
 SG_ CECU6A3_6_2_CAB_SYSA_EQUIPMENT : 50|1@1+ (1,0) [0|0] "" Vector__XXX
 SG_ CECU6A3_6_3_CAB_EQUIPMENT : 51|1@1+ (1,0) [0|0] "" Vector__XXX
 SG_ CECU6A3_6_4_ACC_B_ONOFF : 52|1@1+ (1,0) [0|0] "" Vector__XXX
 SG_ CECU6A3_6_5_ACC_B_EQUIPMENT : 53|1@1+ (1,0) [0|0] "" Vector__XXX
 SG_ CECU6A3_6_6_ACC_A_ONOFF : 54|1@1+ (1,0) [0|0] "" Vector__XXX
 SG_ CECU6A3_6_7_ACC_A_EQUIPMENT : 55|1@1+ (1,0) [0|0] "" Vector__XXX
 SG_ CECU6A3_5_0_AMBI_ILLUM_SPEC : 40|1@1+ (1,0) [0|0] "" Vector__XXX
 SG_ CECU6A3_4_6_SI_DRIVE_S : 38|1@1+ (1,0) [0|0] "" Vector__XXX
 SG_ CECU6A3_4_5_SI_DRIVE_I : 37|1@1+ (1,0) [0|0] "" Vector__XXX
 SG_ CECU6A3_4_4_SI_DRIVE_ECO : 36|1@1+ (1,0) [0|0] "" Vector__XXX
 SG_ CECU6A3_4_3_TOWING_OPT : 35|1@1+ (1,0) [0|0] ""  MVS,SNR
 SG_ CECU6A3_3_4_MOTOR_GENERAT_OUTPUT : 28|1@1+ (1,0) [0|0] ""  ADAS
 SG_ CECU6A3_3_0_HIGH_VOLT_CAPACITY : 24|1@1+ (1,0) [0|0] "" Vector__XXX
 SG_ CECU6A3_2_4_REAR_WHEEL_STEER : 20|1@1+ (1,0) [0|0] "" Vector__XXX
 SG_ CECU6A3_2_0_POWER_CHARGE : 16|1@1+ (1,0) [0|0] "" Vector__XXX
 SG_ CECU6A3_1_5_ACOUTLET_EQUIPMENT : 13|1@1+ (1,0) [0|0] "" Vector__XXX
 SG_ CECU6A3_1_0_MSG_COUNTER : 8|1@1+ (1,0) [0|0] ""  MVS,SNR,ADAS
 SG_ CECU6A3_0_0_CHECK_SUM : 0|1@1+ (1,0) [0|0] ""  MVS,SNR,ADAS

BO_ 1107 DCM453: 32 C_ECU_GW
 SG_ DCM453_31_0_BYTE29 : 248|8@1+ (1,0) [0|255] ""  CHR
 SG_ DCM453_30_0_BYTE28 : 240|8@1+ (1,0) [0|255] ""  CHR
 SG_ DCM453_29_0_BYTE27 : 232|8@1+ (1,0) [0|255] ""  CHR
 SG_ DCM453_28_0_BYTE26 : 224|8@1+ (1,0) [0|255] ""  CHR
 SG_ DCM453_27_0_BYTE25 : 216|8@1+ (1,0) [0|255] ""  CHR
 SG_ DCM453_26_0_BYTE24 : 208|8@1+ (1,0) [0|255] ""  CHR
 SG_ DCM453_25_0_BYTE23 : 200|8@1+ (1,0) [0|255] ""  CHR
 SG_ DCM453_24_0_BYTE22 : 192|8@1+ (1,0) [0|255] ""  CHR
 SG_ DCM453_23_0_BYTE21 : 184|8@1+ (1,0) [0|255] ""  CHR
 SG_ DCM453_22_0_BYTE20 : 176|8@1+ (1,0) [0|255] ""  CHR
 SG_ DCM453_21_0_BYTE19 : 168|8@1+ (1,0) [0|255] ""  CHR
 SG_ DCM453_20_0_BYTE18 : 160|8@1+ (1,0) [0|255] ""  CHR
 SG_ DCM453_19_0_BYTE17 : 152|8@1+ (1,0) [0|255] ""  CHR
 SG_ DCM453_18_0_BYTE16 : 144|8@1+ (1,0) [0|255] ""  CHR
 SG_ DCM453_17_0_BYTE15 : 136|8@1+ (1,0) [0|255] ""  CHR
 SG_ DCM453_16_0_BYTE14 : 128|8@1+ (1,0) [0|255] ""  CHR
 SG_ DCM453_15_0_BYTE13 : 120|8@1+ (1,0) [0|255] ""  CHR
 SG_ DCM453_14_0_BYTE12 : 112|8@1+ (1,0) [0|255] ""  CHR
 SG_ DCM453_13_0_BYTE11 : 104|8@1+ (1,0) [0|255] ""  CHR
 SG_ DCM453_12_0_BYTE10 : 96|8@1+ (1,0) [0|255] ""  CHR
 SG_ DCM453_11_0_BYTE9 : 88|8@1+ (1,0) [0|255] ""  CHR
 SG_ DCM453_10_0_BYTE8 : 80|8@1+ (1,0) [0|255] ""  CHR
 SG_ DCM453_9_0_BYTE7 : 72|8@1+ (1,0) [0|255] ""  CHR
 SG_ DCM453_8_0_BYTE6 : 64|8@1+ (1,0) [0|255] ""  CHR
 SG_ DCM453_7_0_BYTE5 : 56|8@1+ (1,0) [0|255] ""  CHR
 SG_ DCM453_6_0_BYTE4 : 48|8@1+ (1,0) [0|255] ""  CHR
 SG_ DCM453_5_0_BYTE3 : 40|8@1+ (1,0) [0|255] ""  CHR
 SG_ DCM453_4_0_BYTE2 : 32|8@1+ (1,0) [0|255] ""  CHR
 SG_ DCM453_3_0_BYTE1 : 24|8@1+ (1,0) [0|255] ""  CHR
 SG_ DCM453_2_0_E2E_COUNTER : 16|8@1+ (1,0) [0|255] ""  CHR
 SG_ DCM453_0_0_E2E_CRC : 0|16@1+ (1,0) [0|65535] ""  CHR

BO_ 1705 MVS6A9: 8 MVS
 SG_ MVS6A9_6_0_CSTM_HITCHLINE_DSPREQ : 48|2@1+ (1,0) [0|3] ""  C_ECU_GW
 SG_ MVS6A9_6_2_CSTM_HITCHLINE : 50|1@1+ (1,0) [0|1] ""  C_ECU_GW
 SG_ MVS6A9_5_0_RR_WIDE_VIEW_SW_STATE : 40|2@1+ (1,0) [0|3] ""  C_ECU_GW
 SG_ MVS6A9_5_2_RR_NRW_VIEW_SW_STATE : 42|2@1+ (1,0) [0|3] ""  C_ECU_GW
 SG_ MVS6A9_5_4_HITCH_VIEW_SW_STATE : 44|2@1+ (1,0) [0|3] ""  C_ECU_GW
 SG_ MVS6A9_4_0_FT_NRW_VIEW_SW_STATE : 32|2@1+ (1,0) [0|3] ""  C_ECU_GW
 SG_ MVS6A9_4_2_FT_WIDE_VIEW_SW_STATE : 34|2@1+ (1,0) [0|3] ""  C_ECU_GW
 SG_ MVS6A9_4_4_SIDE_VIEW_SW_STATE : 36|2@1+ (1,0) [0|3] ""  C_ECU_GW
 SG_ MVS6A9_4_6_3D_VIEW_SW_STATE : 38|2@1+ (1,0) [0|3] ""  C_ECU_GW
 SG_ MVS6A9_3_0_CSTM_AUTO_DISPLAY_SET : 24|1@1+ (1,0) [0|1] ""  ADAS,C_ECU_GW
 SG_ MVS6A9_3_1_CSTM_AUTO_DISPLAY : 25|1@1+ (1,0) [0|1] ""  ADAS,C_ECU_GW
 SG_ MVS6A9_3_2_VIEW_MODE : 26|3@1+ (1,0) [0|3] ""  C_ECU_GW
 SG_ MVS6A9_3_5_STOP_SWITCH : 29|1@1+ (1,0) [0|1] ""  C_ECU_GW
 SG_ MVS6A9_3_6_CSTM_HITCH_VIEW : 30|1@1+ (1,0) [0|1] ""  C_ECU_GW
 SG_ MVS6A9_2_0_CURRENT_VIEW : 16|5@1+ (1,0) [0|31] ""  ADAS,C_ECU_GW
 SG_ MVS6A9_2_5_HOLD_TIME : 21|1@1+ (1,0) [0|1] ""  C_ECU_GW
 SG_ MVS6A9_1_0_MSG_COUNTER : 8|4@1+ (1,0) [0|15] ""  ADAS,C_ECU_GW
 SG_ MVS6A9_1_4_FAIL_MVS : 12|1@1+ (1,0) [0|1] ""  C_ECU_GW
 SG_ MVS6A9_1_5_FAIL_MVS_CAUSE : 13|3@1+ (1,0) [0|7] ""  ADAS,C_ECU_GW
 SG_ MVS6A9_0_0_CHECK_SUM : 0|8@1+ (1,0) [0|255] ""  ADAS,C_ECU_GW

BO_ 1364 MVS554: 8 MVS
 SG_ MVS554_7_0_NETWORK_STATUS : 7|64@0+ (1,0) [0|0] "" Vector__XXX

BO_ 930 MET3A2: 8 MET
 SG_ MET3A2_7_0_FUEL_AMOUNT : 56|8@1+ (1,0) [0|100] "%"  BEV_GW,C_ECU_GW
 SG_ MET3A2_6_0_SEATBELT_RR_RH : 48|1@1+ (1,0) [0|1] ""  BEV_GW,C_ECU_GW
 SG_ MET3A2_6_1_SEATBELT_RR_CTR : 49|1@1+ (1,0) [0|1] ""  BEV_GW,C_ECU_GW
 SG_ MET3A2_6_2_SEATBELT_RR_LH : 50|1@1+ (1,0) [0|1] ""  BEV_GW,C_ECU_GW
 SG_ MET3A2_6_3_SEATBELT_THIRD_RH : 51|1@1+ (1,0) [0|1] ""  BEV_GW,C_ECU_GW
 SG_ MET3A2_6_4_SEATBELT_THIRD_CTR : 52|1@1+ (1,0) [0|1] ""  BEV_GW,C_ECU_GW
 SG_ MET3A2_6_5_SEATBELT_THIRD_LH : 53|1@1+ (1,0) [0|1] ""  BEV_GW,C_ECU_GW
 SG_ MET3A2_5_0_FLG_RR_REMINDER : 40|1@1+ (1,0) [0|1] ""  BEV_GW,C_ECU_GW
 SG_ MET3A2_2_0_ODO_DETAIL : 16|24@1+ (0.1,0) [0|1609103.5] "km"  BAT,BEV,BEV_GW,C_ECU_GW
 SG_ MET3A2_1_0_MSG_COUNTER : 8|4@1+ (1,0) [0|15] ""  BEV_GW,C_ECU_GW
 SG_ MET3A2_1_4_FAIL_DISP : 12|2@1+ (1,0) [0|3] ""  BEV_GW,C_ECU_GW
 SG_ MET3A2_0_0_CHECK_SUM : 0|8@1+ (1,0) [0|255] ""  BEV_GW,C_ECU_GW

BO_ 1677 MET68D: 8 MET
 SG_ MET68D_7_0_STATUS_WASHER_LAMP : 56|1@1+ (1,0) [0|1] ""  C_ECU_GW
 SG_ MET68D_7_1_OILPRESSURE_SW : 57|1@1+ (1,0) [0|1] ""  C_ECU_GW
 SG_ MET68D_7_2_FLG_EAM : 58|1@1+ (1,0) [0|1] ""  C_ECU_GW
 SG_ MET68D_7_3_CSTM_IND_RED : 59|1@1+ (1,0) [0|1] ""  C_ECU_GW
 SG_ MET68D_7_4_CSTM_IND_YELLOW : 60|1@1+ (1,0) [0|1] ""  C_ECU_GW
 SG_ MET68D_7_5_CSTM_IND_GREEN : 61|1@1+ (1,0) [0|1] ""  C_ECU_GW
 SG_ MET68D_7_6_REQ_CSTM_SRH : 62|1@1+ (1,0) [0|1] ""  C_ECU_GW
 SG_ MET68D_7_7_CSTM_SRH : 63|1@1+ (1,0) [0|1] ""  C_ECU_GW
 SG_ MET68D_6_5_REQ_CHG_CSTM_RAB : 53|1@1+ (1,0) [0|1] ""  C_ECU_GW
 SG_ MET68D_6_6_CSTM_RAB : 54|1@1+ (1,0) [0|1] ""  C_ECU_GW
 SG_ MET68D_6_7_CSTM_SONNER : 55|1@1+ (1,0) [0|1] ""  C_ECU_GW
 SG_ MET68D_5_0_TEMP_FOR_PPA : 40|13@1- (0.1,-400) [-400|419.1] "℃"  C_ECU_GW
 SG_ MET68D_2_0_ODO : 16|24@1+ (0.1,0) [0|999999.9] "km"  ENM,C_ECU,C_ECU_GW
 SG_ MET68D_1_0_MSG_COUNTER : 8|4@1+ (1,0) [0|15] ""  ENM,C_ECU_GW
 SG_ MET68D_1_4_RESET_CSTM_TPMS_RAEB : 12|1@1+ (1,0) [0|1] ""  C_ECU_GW
 SG_ MET68D_1_5_REQ_CHG_CSTM_TPMS : 13|1@1+ (1,0) [0|1] ""  C_ECU_GW
 SG_ MET68D_1_6_CSTM_TIRE_UNIT : 14|2@1+ (1,0) [0|3] ""  C_ECU_GW
 SG_ MET68D_0_0_CHECK_SUM : 0|8@1+ (1,0) [0|255] ""  ENM,C_ECU_GW

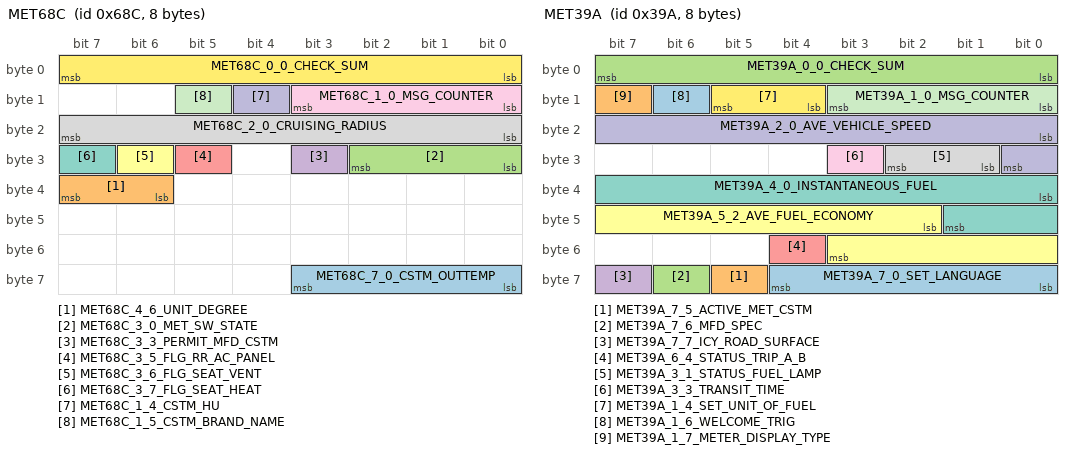
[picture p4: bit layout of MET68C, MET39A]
BO_ 1676 MET68C: 8 MET
 SG_ MET68C_7_0_CSTM_OUTTEMP : 56|4@1+ (1,0) [0|15] "℃"  C_ECU_GW
 SG_ MET68C_4_6_UNIT_DEGREE : 38|2@1+ (1,0) [0|3] ""  C_ECU_GW
 SG_ MET68C_3_0_MET_SW_STATE : 24|3@1+ (1,0) [0|3] ""  C_ECU_GW
 SG_ MET68C_3_3_PERMIT_MFD_CSTM : 27|1@1+ (1,0) [0|1] ""  C_ECU_GW
 SG_ MET68C_3_5_FLG_RR_AC_PANEL : 29|1@1+ (1,0) [0|1] ""  C_ECU_GW
 SG_ MET68C_3_6_FLG_SEAT_VENT : 30|1@1+ (1,0) [0|1] ""  C_ECU_GW
 SG_ MET68C_3_7_FLG_SEAT_HEAT : 31|1@1+ (1,0) [0|1] ""  C_ECU_GW
 SG_ MET68C_2_0_CRUISING_RADIUS : 16|8@1+ (10,0) [10|2540] "km(mile)"  C_ECU_GW
 SG_ MET68C_1_0_MSG_COUNTER : 8|4@1+ (1,0) [0|15] ""  C_ECU_GW
 SG_ MET68C_1_4_CSTM_HU : 12|1@1+ (1,0) [0|1] ""  C_ECU_GW
 SG_ MET68C_1_5_CSTM_BRAND_NAME : 13|1@1+ (1,0) [0|1] ""  C_ECU_GW
 SG_ MET68C_0_0_CHECK_SUM : 0|8@1+ (1,0) [0|255] ""  C_ECU_GW

BO_ 922 MET39A: 8 MET
 SG_ MET39A_7_0_SET_LANGUAGE : 56|5@1+ (1,0) [0|21] ""  C_ECU_GW
 SG_ MET39A_7_5_ACTIVE_MET_CSTM : 61|1@1+ (1,0) [0|1] ""  C_ECU_GW
 SG_ MET39A_7_6_MFD_SPEC : 62|1@1+ (1,0) [0|1] ""  C_ECU_GW
 SG_ MET39A_7_7_ICY_ROAD_SURFACE : 63|1@1+ (1,0) [0|2] ""  C_ECU_GW
 SG_ MET39A_6_4_STATUS_TRIP_A_B : 52|1@1+ (1,0) [0|1] ""  ENM,C_ECU_GW
 SG_ MET39A_5_2_AVE_FUEL_ECONOMY : 42|10@1+ (0.1,0) [0|99.9] "km/l,l/100km,MPG"  C_ECU_GW
 SG_ MET39A_4_0_INSTANTANEOUS_FUEL : 32|10@1+ (0.1,0) [0|99.9] "km/l,l/100km,MPG"  C_ECU_GW
 SG_ MET39A_3_1_STATUS_FUEL_LAMP : 25|2@1+ (1,0) [0|3] ""  C_ECU_GW
 SG_ MET39A_3_3_TRANSIT_TIME : 27|1@1+ (1,0) [0|1] ""  C_ECU_GW
 SG_ MET39A_2_0_AVE_VEHICLE_SPEED : 16|9@1+ (1,0) [0|300] "km/h(MPH)"  C_ECU_GW
 SG_ MET39A_1_0_MSG_COUNTER : 8|4@1+ (1,0) [0|15] ""  ENM,C_ECU_GW
 SG_ MET39A_1_4_SET_UNIT_OF_FUEL : 12|2@1+ (1,0) [0|3] ""  C_ECU_GW
 SG_ MET39A_1_6_WELCOME_TRIG : 14|1@1+ (1,0) [0|2] ""  C_ECU_GW
 SG_ MET39A_1_7_METER_DISPLAY_TYPE : 15|1@1+ (1,0) [0|2] ""  C_ECU_GW
 SG_ MET39A_0_0_CHECK_SUM : 0|8@1+ (1,0) [0|255] ""  ENM,C_ECU_GW

BO_ 915 MET393: 8 MET
 SG_ MET393_7_0_REQ_CHG_CSTM_EYE : 56|1@1+ (1,0) [0|1] ""  C_ECU_GW
 SG_ MET393_7_1_REQ_RESET_CSTM_EYE : 57|1@1+ (1,0) [0|1] ""  C_ECU_GW
 SG_ MET393_7_2_CSTM_ALK : 58|1@1+ (1,0) [0|1] ""  C_ECU_GW
 SG_ MET393_7_3_CSTM_HBA : 59|1@1+ (1,0) [0|1] ""  C_ECU_GW
 SG_ MET393_7_4_CSTM_MIS_AT_BACK : 60|2@1+ (1,0) [0|3] ""  C_ECU_GW
 SG_ MET393_7_6_CSTM_ACC_CONT : 62|2@1+ (1,0) [0|3] ""  C_ECU_GW
 SG_ MET393_6_0_R_DIFF_TEMP : 48|8@1+ (1,-50) [-50|200] "℃"  C_ECU_GW
 SG_ MET393_5_2_WARN_R_DIFF_TEMP : 42|2@1+ (1,0) [0|3] ""  C_ECU_GW
 SG_ MET393_5_4_ADAPTIVECC_NOALIVE : 44|1@1+ (1,0) [0|1] ""  C_ECU_GW
 SG_ MET393_5_5_DUAL_RANGE_LO : 45|1@1+ (1,0) [0|1] ""  C_ECU_GW
 SG_ MET393_5_6_CSTM_SPD_LIMITER : 46|1@1+ (1,0) [0|1] ""  C_ECU_GW
 SG_ MET393_5_7_CSTM_LANE_CONT : 47|1@1+ (1,0) [0|1] ""  C_ECU_GW
 SG_ MET393_4_0_FUEL_LEVEL_RESIST : 32|10@1+ (0.5,0) [0|480] "ohm"  C_ECU_GW
 SG_ MET393_3_5_SI_DRIVE_SW : 29|3@1+ (1,0) [0|7] ""  BEV,C_ECU_GW
 SG_ MET393_2_0_OUTTEMP_FOR_DIAG : 16|13@1+ (0.1,-400) [-400|419.1] "℃"  ENM,THM,BAT,C_ECU_GW
 SG_ MET393_1_0_MSG_COUNTER : 8|4@1+ (1,0) [0|15] ""  THM,BEV,C_ECU_GW
 SG_ MET393_1_4_CSTM_IND_BLUE : 12|1@1+ (1,0) [0|1] ""  C_ECU_GW
 SG_ MET393_1_5_CSTM_AES_CONT : 13|1@1+ (1,0) [0|1] ""  C_ECU_GW
 SG_ MET393_1_6_FLG_PEDESTRIAN_AIRBAG : 14|1@1+ (1,0) [0|1] ""  C_ECU_GW
 SG_ MET393_0_0_CHECK_SUM : 0|8@1+ (1,0) [0|255] ""  THM,BEV,C_ECU_GW

BO_ 912 MET390: 8 MET
 SG_ MET390_7_0_VDC_ON_OFF : 56|2@1+ (1,0) [0|3] ""  C_ECU_GW
 SG_ MET390_7_2_RR_DOOR_RECORD_L : 58|1@1+ (1,0) [0|1] ""  C_ECU_GW
 SG_ MET390_7_3_RR_DOOR_RECORD_R : 59|1@1+ (1,0) [0|1] ""  C_ECU_GW
 SG_ MET390_7_4_REQ_CHG_CSTM_PSM : 60|1@1+ (1,0) [0|1] ""  C_ECU_GW
 SG_ MET390_7_5_REQ_RESET_CSTM_PSM : 61|1@1+ (1,0) [0|1] ""  C_ECU_GW
 SG_ MET390_7_6_CSTM_MIR_AFOLD_CONT : 62|1@1+ (1,0) [0|1] ""  C_ECU_GW
 SG_ MET390_7_7_CSTM_MIR_RTILT_CONT : 63|1@1+ (1,0) [0|1] ""  C_ECU_GW
 SG_ MET390_6_0_SEATBELT_DRVR : 48|1@1+ (1,0) [0|1] ""  RCR_R,RCR_L,BEV,C_ECU,C_ECU_GW
 SG_ MET390_6_1_SEATBELT_PASS : 49|1@1+ (1,0) [0|1] ""  C_ECU,C_ECU_GW
 SG_ MET390_6_2_TURN_SIG_LEFT : 50|1@1+ (1,0) [0|1] ""  RCR_R,RCR_L,C_ECU,C_ECU_GW
 SG_ MET390_6_3_TURN_SIG_RIGHT : 51|1@1+ (1,0) [0|1] ""  RCR_R,RCR_L,C_ECU,C_ECU_GW
 SG_ MET390_6_4_BRIGHT_SW : 52|1@1+ (1,0) [0|1] ""  C_ECU_GW
 SG_ MET390_6_5_FAIL_UART_WA_BOX : 53|1@1+ (1,0) [0|1] ""  C_ECU_GW
 SG_ MET390_6_6_ISS_OFF_SW : 54|1@1+ (1,0) [0|1] ""  C_ECU_GW
 SG_ MET390_6_7_FLG_DMS : 55|1@1+ (1,0) [0|1] ""  C_ECU_GW
 SG_ MET390_5_0_ILL_BRIGHTNESS : 40|8@1+ (0.4,0) [0|100] "%"  C_ECU_GW
 SG_ MET390_4_0_OUTTEMP_FOR_IND : 32|8@1+ (0.5,-40) [-40|80] "℃"  SNR,THM,BAT,C_ECU_GW
 SG_ MET390_3_0_UNIT_SPEED_TRIP : 24|1@1+ (1,0) [0|1] ""  C_ECU_GW
 SG_ MET390_3_1_FLG_EYESIGHT : 25|1@1+ (1,0) [0|1] ""  C_ECU_GW
 SG_ MET390_3_2_FLG_ISS : 26|1@1+ (1,0) [0|1] ""  C_ECU_GW
 SG_ MET390_3_3_FLG_HEV : 27|1@1+ (1,0) [0|1] ""  C_ECU_GW
 SG_ MET390_3_4_FLG_IMB : 28|1@1+ (1,0) [0|1] ""  C_ECU_GW
 SG_ MET390_3_5_TIRE_SIZE : 29|1@1+ (1,0) [0|1] ""  C_ECU_GW
 SG_ MET390_3_6_FLG_XMODE : 30|2@1+ (1,0) [0|3] ""  C_ECU_GW
 SG_ MET390_2_0_VEHICLE_SERIES : 16|3@1+ (1,0) [0|7] ""  C_ECU_GW
 SG_ MET390_2_3_DESTINATION : 19|4@1+ (1,0) [0|12] ""  C_ECU,C_ECU_GW
 SG_ MET390_2_7_PASS_DOOR_RECORD : 23|1@1+ (1,0) [0|1] ""  C_ECU_GW
 SG_ MET390_1_0_MSG_COUNTER : 8|4@1+ (1,0) [0|15] ""  RCR_R,RCR_L,SNR,THM,BAT,BEV,C_ECU,C_ECU_GW
 SG_ MET390_1_4_WAKE_UP_FRAME : 12|1@1+ (1,0) [0|1] ""  C_ECU_GW
 SG_ MET390_1_5_REQ_COMM_CONT : 13|1@1+ (1,0) [0|1] ""  C_ECU_GW
 SG_ MET390_1_6_DMS_ID_SET : 14|1@1+ (1,0) [0|1] ""  C_ECU_GW
 SG_ MET390_1_7_FAIL_EEPROM : 15|1@1+ (1,0) [0|1] ""  C_ECU_GW
 SG_ MET390_0_0_CHECK_SUM : 0|8@1+ (1,0) [0|255] ""  RCR_R,RCR_L,SNR,THM,BAT,BEV,C_ECU,C_ECU_GW

BO_ 1291 MET50B: 8 MET
 SG_ MET50B_1_4_ActiveWakeUpBit : 12|1@0+ (1,0) [0|1] ""  C_ECU,C_ECU_GW
 SG_ MET50B_0_0_SourceNodeID : 7|8@0+ (1,0) [0|255] ""  C_ECU,C_ECU_GW

BO_ 914 MET392: 32 MET
 SG_ MET392_23_0_ADD_ACNON_DRVRANG : 184|11@1+ (1,0) [0|1999] "km"  C_ECU_GW
 SG_ MET392_21_0_ADD_ACNOFF_DRVRANG : 168|11@1+ (1,0) [0|1999] "km"  C_ECU_GW
 SG_ MET392_18_0_TRIP_LASTCHG_TOTM : 144|20@1+ (1,0) [0|599940] "min"  C_ECU_GW
 SG_ MET392_15_0_TRIPB_TOTAL_TIME : 120|20@1+ (1,0) [0|599940] "min"  C_ECU_GW
 SG_ MET392_12_0_TRIPA_TOTAL_TIME : 96|20@1+ (1,0) [0|599940] "min"  C_ECU_GW
 SG_ MET392_9_0_TRIP_LASTCHARGE_KM : 72|18@1+ (0.1,0) [0|16200] "km"  ENM,C_ECU_GW
 SG_ MET392_8_2_TRIPB_RESET : 66|1@1+ (1,0) [0|1] ""  ENM,C_ECU_GW
 SG_ MET392_6_0_TRIPB_KM : 48|18@1+ (0.1,0) [0|16200] "km"  ENM,C_ECU_GW
 SG_ MET392_5_2_TRIPA_RESET : 42|1@1+ (1,0) [0|1] ""  ENM,C_ECU_GW
 SG_ MET392_3_0_TRIPA_KM : 24|18@1+ (0.1,0) [0|16200] "km"  ENM,C_ECU_GW
 SG_ MET392_2_0_E2E_COUNTER : 16|8@1+ (1,0) [0|255] ""  ENM,C_ECU_GW
 SG_ MET392_0_0_CRC : 0|16@1+ (1,0) [0|65535] ""  ENM,C_ECU_GW

BO_ 938 MET3AA: 8 Vector__XXX

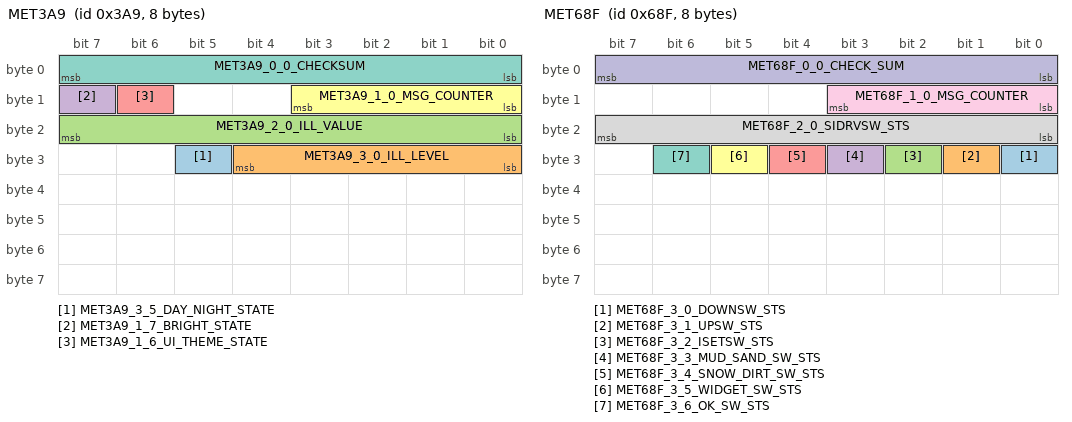
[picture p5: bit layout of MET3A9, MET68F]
BO_ 937 MET3A9: 8 MET
 SG_ MET3A9_3_5_DAY_NIGHT_STATE : 29|1@1+ (1,0) [0|1] ""  RCR_R,RCR_L,C_ECU_GW
 SG_ MET3A9_3_0_ILL_LEVEL : 24|5@1+ (1,0) [0|21] ""  C_ECU_GW
 SG_ MET3A9_2_0_ILL_VALUE : 16|8@1+ (0.4,0) [0|100] "%"  C_ECU_GW
 SG_ MET3A9_1_7_BRIGHT_STATE : 15|1@1+ (1,0) [0|1] ""  RCR_R,RCR_L,C_ECU_GW
 SG_ MET3A9_1_6_UI_THEME_STATE : 14|1@1+ (1,0) [0|1] ""  C_ECU_GW
 SG_ MET3A9_1_0_MSG_COUNTER : 8|4@1+ (1,0) [0|15] ""  RCR_R,RCR_L,C_ECU_GW
 SG_ MET3A9_0_0_CHECKSUM : 0|8@1+ (1,0) [0|255] ""  RCR_R,RCR_L,C_ECU_GW

BO_ 933 MET3A5: 8 MET
 SG_ MET3A5_7_0_INSTCNSP_VAL : 56|10@1+ (0.1,0) [0|99.9] ""  C_ECU_GW
 SG_ MET3A5_5_0_AVEN_TRIPB_VAL : 40|10@1+ (0.1,0) [0|99.9] ""  C_ECU_GW
 SG_ MET3A5_3_0_AVEN_TRIPA_VAL : 24|10@1+ (0.1,0) [0|99.9] ""  C_ECU_GW
 SG_ MET3A5_2_0_E2E_COUNTER : 16|8@1+ (1,0) [0|255] ""  C_ECU_GW
 SG_ MET3A5_0_0_CRC : 0|16@1+ (1,0) [0|65535] ""  C_ECU_GW

BO_ 1679 MET68F: 8 MET
 SG_ MET68F_3_0_DOWNSW_STS : 24|1@1+ (1,0) [0|1] ""  C_ECU_GW
 SG_ MET68F_3_1_UPSW_STS : 25|1@1+ (1,0) [0|1] ""  C_ECU_GW
 SG_ MET68F_3_2_ISETSW_STS : 26|1@1+ (1,0) [0|1] ""  C_ECU_GW
 SG_ MET68F_3_3_MUD_SAND_SW_STS : 27|1@1+ (1,0) [0|1] ""  C_ECU_GW
 SG_ MET68F_3_4_SNOW_DIRT_SW_STS : 28|1@1+ (1,0) [0|1] ""  C_ECU_GW
 SG_ MET68F_3_5_WIDGET_SW_STS : 29|1@1+ (1,0) [0|1] ""  C_ECU,C_ECU_GW
 SG_ MET68F_3_6_OK_SW_STS : 30|1@1+ (1,0) [0|1] ""  C_ECU_GW
 SG_ MET68F_2_0_SIDRVSW_STS : 16|8@1+ (1,0) [0|3] ""  C_ECU_GW
 SG_ MET68F_1_0_MSG_COUNTER : 8|4@1+ (1,0) [0|15] ""  C_ECU,C_ECU_GW
 SG_ MET68F_0_0_CHECK_SUM : 0|8@1+ (1,0) [0|255] ""  C_ECU,C_ECU_GW

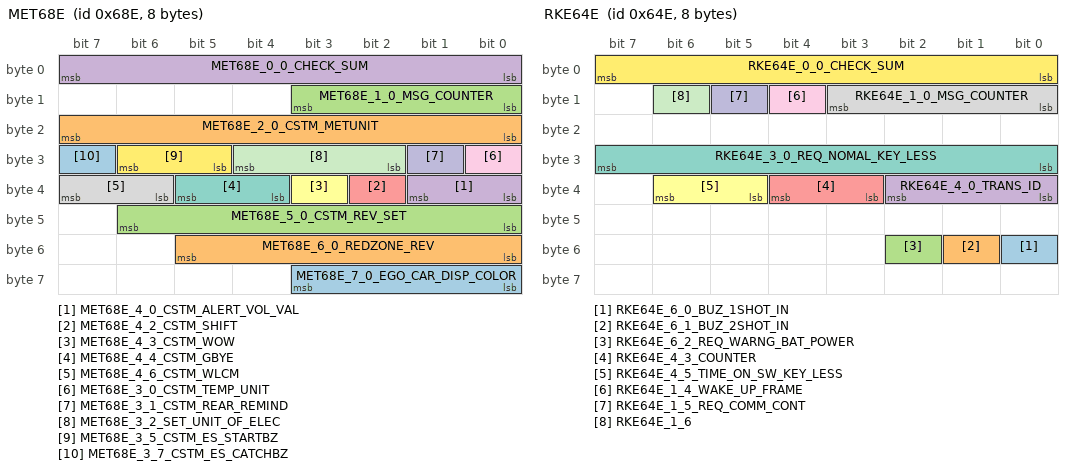
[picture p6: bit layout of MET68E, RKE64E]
BO_ 1678 MET68E: 8 MET
 SG_ MET68E_7_0_EGO_CAR_DISP_COLOR : 56|4@1+ (1,0) [0|9] ""  C_ECU_GW
 SG_ MET68E_6_0_REDZONE_REV : 48|6@1+ (100,5000) [0|40] "rpm"  C_ECU_GW
 SG_ MET68E_5_0_CSTM_REV_SET : 40|7@1+ (1,0) [0|127] ""  C_ECU_GW
 SG_ MET68E_4_0_CSTM_ALERT_VOL_VAL : 32|2@1+ (1,0) [0|3] ""  C_ECU_GW
 SG_ MET68E_4_2_CSTM_SHIFT : 34|1@1+ (1,0) [0|1] ""  C_ECU_GW
 SG_ MET68E_4_3_CSTM_WOW : 35|1@1+ (1,0) [0|1] ""  C_ECU_GW
 SG_ MET68E_4_4_CSTM_GBYE : 36|2@1+ (1,0) [0|3] ""  C_ECU_GW
 SG_ MET68E_4_6_CSTM_WLCM : 38|2@1+ (1,0) [0|3] ""  C_ECU_GW
 SG_ MET68E_3_0_CSTM_TEMP_UNIT : 24|1@1+ (1,0) [0|1] ""  C_ECU_GW
 SG_ MET68E_3_1_CSTM_REAR_REMIND : 25|1@1+ (1,0) [0|1] ""  C_ECU_GW
 SG_ MET68E_3_2_SET_UNIT_OF_ELEC : 26|3@1+ (1,0) [0|7] ""  C_ECU_GW
 SG_ MET68E_3_5_CSTM_ES_STARTBZ : 29|2@1+ (1,0) [0|2] ""  C_ECU_GW
 SG_ MET68E_3_7_CSTM_ES_CATCHBZ : 31|1@1+ (1,0) [0|1] ""  C_ECU_GW
 SG_ MET68E_2_0_CSTM_METUNIT : 16|8@1+ (1,0) [0|0] ""  C_ECU_GW
 SG_ MET68E_1_0_MSG_COUNTER : 8|4@1+ (1,0) [0|15] ""  C_ECU_GW
 SG_ MET68E_0_0_CHECK_SUM : 0|8@1+ (1,0) [0|255] ""  C_ECU_GW

BO_ 1674 MET68A: 32 MET
 SG_ MET68A_31_0_METBZ_STS_CH0 : 248|1@1+ (1,0) [0|1] ""  C_ECU_GW
 SG_ MET68A_31_1_METBZ_STS_CH1 : 249|1@1+ (1,0) [0|1] ""  C_ECU_GW
 SG_ MET68A_31_2_METBZ_WARN_CH0 : 250|1@1+ (1,0) [0|1] ""  C_ECU_GW
 SG_ MET68A_31_3_METBZ_PTN_CH0 : 251|1@1+ (1,0) [0|1] ""  C_ECU_GW
 SG_ MET68A_31_4_METBZ_WARN_CH1 : 252|1@1+ (1,0) [0|1] ""  C_ECU_GW
 SG_ MET68A_31_5_METBZ_PTN_CH1 : 253|1@1+ (1,0) [0|1] ""  C_ECU_GW
 SG_ MET68A_31_6_VOL_ATN_REQ : 254|2@1+ (1,0) [0|3] ""  C_ECU_GW
 SG_ MET68A_30_0_METBZ_KIND_CH1 : 240|8@1+ (1,0) [0|255] ""  C_ECU_GW
 SG_ MET68A_29_0_METBZ_KIND_CH0 : 232|8@1+ (1,0) [0|255] ""  C_ECU_GW
 SG_ MET68A_26_0_TRIPB_VAL : 208|24@1+ (0.1,0) [0|1677721.5] ""  C_ECU_GW
 SG_ MET68A_23_0_TRIPA_VAL : 184|24@1+ (0.1,0) [0|1677721.5] ""  C_ECU_GW
 SG_ MET68A_22_6_VOL_MUTE_REQ : 182|2@1+ (1,0) [0|3] ""  C_ECU_GW
 SG_ MET68A_21_0_IGNONDIST_VAL : 168|14@1+ (1,0) [0|16383] ""  C_ECU_GW
 SG_ MET68A_20_1_IGNONTM_MIN_VAL : 161|6@1+ (1,0) [0|59] "min"  C_ECU_GW
 SG_ MET68A_19_0_AVSP_TRIPB_VAL : 152|9@1+ (1,0) [0|300] ""  C_ECU_GW
 SG_ MET68A_18_1_IGNONTM_HOUR_VAL : 145|7@1+ (1,0) [0|99] "h"  C_ECU_GW
 SG_ MET68A_17_0_AVSP_TRIPA_VAL : 136|9@1+ (1,0) [0|300] ""  C_ECU_GW
 SG_ MET68A_16_0_TRIP_DISP_TYPE : 128|8@1+ (1,0) [0|0] ""  C_ECU_GW
 SG_ MET68A_13_0_TRIP_VAL : 104|24@1+ (0.1,0) [0|9999.9] ""  C_ECU_GW
 SG_ MET68A_12_0_TEMPBAR_PER : 96|8@1+ (1,0) [0|250] ""  C_ECU_GW
 SG_ MET68A_11_0_FUELBAR_PER : 88|8@1+ (1,0) [0|100] ""  C_ECU_GW
 SG_ MET68A_9_0_TACHOREV_VAL : 72|16@1+ (1,0) [0|8000] "rpm"  C_ECU_GW
 SG_ MET68A_7_0_SPD_COR_VAL : 56|16@1+ (1,0) [0|65535] ""  C_ECU_GW
 SG_ MET68A_6_1_CID_TONE_DOWN : 49|5@1+ (1,0) [0|31] ""  C_ECU_GW
 SG_ MET68A_6_6_SI_FAIL_FLAG : 54|1@1+ (1,0) [0|1] ""  C_ECU_GW
 SG_ MET68A_5_0_DMSPD_SUB_VAL : 40|9@1+ (1,0) [0|300] ""  C_ECU_GW
 SG_ MET68A_4_1_ILM_AIDM : 33|1@1+ (1,0) [0|1] ""  C_ECU_GW
 SG_ MET68A_4_2_TEMP_ICON : 34|3@1+ (1,0) [0|7] ""  C_ECU_GW
 SG_ MET68A_4_5_SIDRIVE_MET_DISP : 37|3@1+ (1,0) [0|7] ""  C_ECU_GW
 SG_ MET68A_3_0_DMSPD_VAL : 24|9@1+ (1,0) [0|300] ""  C_ECU_GW
 SG_ MET68A_2_0_E2E_COUNTER : 16|8@1+ (1,0) [0|255] ""  C_ECU_GW
 SG_ MET68A_0_0_CRC : 0|16@1+ (1,0) [0|65535] ""  C_ECU_GW

BO_ 1673 MET689: 32 MET
 SG_ MET689_20_0_VOICE_GUIDE_SUP : 160|1@1+ (1,0) [0|1] ""  C_ECU_GW
 SG_ MET689_19_0_SPORT_CONT : 152|8@1+ (1,0) [0|255] ""  C_ECU_GW
 SG_ MET689_18_0_STI_SUP : 144|8@1+ (1,0) [0|255] ""  C_ECU_GW
 SG_ MET689_17_0_REARVIEW : 136|1@1+ (1,0) [0|1] ""  C_ECU_GW
 SG_ MET689_16_0_GSR_ELKS_SUP : 128|1@1+ (1,0) [0|1] ""  C_ECU_GW
 SG_ MET689_16_1_GSR_AEBS_SUP : 129|1@1+ (1,0) [0|1] ""  C_ECU_GW
 SG_ MET689_16_2_GSR_DDAW_SUP : 130|1@1+ (1,0) [0|1] ""  C_ECU_GW
 SG_ MET689_16_3_GSR_ISA_SUP : 131|1@1+ (1,0) [0|1] ""  C_ECU_GW
 SG_ MET689_16_4_IACC_SUP : 132|1@1+ (1,0) [0|1] ""  C_ECU_GW
 SG_ MET689_16_5_REAR_PANEL_SUP : 133|1@1+ (1,0) [0|1] ""  C_ECU_GW
 SG_ MET689_16_6_SEAT_HEATER_SUP : 134|1@1+ (1,0) [0|1] ""  C_ECU_GW
 SG_ MET689_16_7_SEAT_VENT_SUP : 135|1@1+ (1,0) [0|1] ""  C_ECU_GW
 SG_ MET689_15_0_CAMERA : 120|8@1+ (1,0) [0|8] ""  C_ECU_GW
 SG_ MET689_14_0_SXM_VARIANT : 112|8@1+ (1,0) [0|255] ""  C_ECU_GW
 SG_ MET689_13_0_DAB : 104|1@1+ (1,0) [0|1] ""  C_ECU_GW
 SG_ MET689_13_1_SXM : 105|1@1+ (1,0) [0|1] ""  C_ECU_GW
 SG_ MET689_13_2_EMBEDDED_NAVI : 106|1@1+ (1,0) [0|1] ""  C_ECU_GW
 SG_ MET689_12_0_SPK_AMP : 96|8@1+ (1,0) [0|17] ""  C_ECU_GW
 SG_ MET689_11_0_DEST_VEHICLE : 88|8@1+ (1,0) [0|255] ""  C_ECU_GW
 SG_ MET689_10_0_RDIFF_TEMP_SUP : 80|1@1+ (1,0) [0|1] ""  C_ECU_GW
 SG_ MET689_10_1_SIDRIVE_SW_TYPE : 81|2@1+ (1,0) [0|3] ""  C_ECU_GW
 SG_ MET689_10_3_XMODE_SW_TYPE : 83|2@1+ (1,0) [0|3] ""  C_ECU_GW
 SG_ MET689_9_0_GPF_SUP : 72|1@1+ (1,0) [0|1] ""  C_ECU_GW
 SG_ MET689_9_1_SRH_SUP : 73|1@1+ (1,0) [0|1] ""  C_ECU_GW
 SG_ MET689_9_2_AUTO_DOOR_MIRROR_SUP : 74|1@1+ (1,0) [0|1] ""  C_ECU_GW
 SG_ MET689_9_3_REAR_REMIND_SUP : 75|1@1+ (1,0) [0|1] ""  C_ECU_GW
 SG_ MET689_9_4_DRIVE_TYPE : 76|1@1+ (1,0) [0|1] ""  C_ECU_GW
 SG_ MET689_9_5_TPMSDISP_SUP : 77|1@1+ (1,0) [0|1] ""  C_ECU_GW
 SG_ MET689_9_6_GSI_SUP : 78|1@1+ (1,0) [0|1] ""  C_ECU_GW
 SG_ MET689_9_7_SRVD_SUP : 79|1@1+ (1,0) [0|1] ""  C_ECU_GW
 SG_ MET689_8_0_XMODE_SUP : 64|8@1+ (1,0) [0|3] ""  C_ECU_GW
 SG_ MET689_7_0_SIDRIVE_SUP : 56|8@1+ (1,0) [0|19] ""  C_ECU_GW
 SG_ MET689_6_0_GRADE_INFO : 48|8@1+ (1,0) [0|1] ""  C_ECU_GW
 SG_ MET689_5_0_VEHICLE_TYPE : 40|8@1+ (1,0) [0|255] ""  C_ECU_GW
 SG_ MET689_4_0_DEST_GRP : 32|8@1+ (1,0) [0|255] ""  C_ECU_GW
 SG_ MET689_3_0_VEHICLE_MODEL : 24|8@1+ (1,0) [0|255] ""  C_ECU_GW
 SG_ MET689_2_0_E2E_COUNTER : 16|8@1+ (1,0) [0|255] ""  C_ECU_GW
 SG_ MET689_0_0_CRC : 0|16@1+ (1,0) [0|65535] ""  C_ECU_GW

BO_ 1672 MET688: 32 MET
 SG_ MET688_13_5_STATUS_PWRLMT_WARN : 109|3@1+ (1,0) [0|7] ""  C_ECU
 SG_ MET688_13_3_STATUS_HVB_WARN : 107|2@1+ (1,0) [0|3] ""  C_ECU
 SG_ MET688_13_0_STATUS_EV_FAIL : 104|3@1+ (1,0) [0|7] ""  C_ECU
 SG_ MET688_12_6_STATUS_ICY_ROAD : 102|1@1+ (1,0) [0|1] ""  C_ECU
 SG_ MET688_12_5_STATUS_DOOR_DRVR : 101|1@1+ (1,0) [0|1] ""  C_ECU
 SG_ MET688_12_4_STATUS_DOOR_PASS : 100|1@1+ (1,0) [0|1] ""  C_ECU
 SG_ MET688_12_3_STATUS_DOOR_RRRH : 99|1@1+ (1,0) [0|1] ""  C_ECU
 SG_ MET688_12_2_STATUS_DOOR_RRLH : 98|1@1+ (1,0) [0|1] ""  C_ECU
 SG_ MET688_12_1_STATUS_DOOR_RG : 97|1@1+ (1,0) [0|1] ""  C_ECU
 SG_ MET688_12_0_STATUS_DOOR_TR : 96|1@1+ (1,0) [0|1] ""  C_ECU
 SG_ MET688_11_5_STATUS_IPMS_IND : 93|3@1+ (1,0) [0|7] ""  C_ECU
 SG_ MET688_11_2_STATUS_SIDRIVE_MODE : 90|3@1+ (1,0) [0|7] ""  C_ECU
 SG_ MET688_11_0_STATUS_HEADLAMP_FAIL : 88|2@1+ (1,0) [0|3] ""  C_ECU
 SG_ MET688_10_7_STATUS_HBA_FAIL : 87|1@1+ (1,0) [0|1] ""  C_ECU
 SG_ MET688_10_5_STATUS_HBA_ACT : 85|2@1+ (1,0) [0|3] ""  C_ECU
 SG_ MET688_10_4_STATUS_RAB_OFF : 84|1@1+ (1,0) [0|1] ""  C_ECU
 SG_ MET688_10_2_STATUS_EPB_ACT : 82|2@1+ (1,0) [0|3] ""  C_ECU
 SG_ MET688_10_1_STATUS_PCR_OFF : 81|1@1+ (1,0) [0|1] ""  C_ECU
 SG_ MET688_10_0_STATUS_LANEOFF_WARN : 80|1@1+ (1,0) [0|1] ""  C_ECU
 SG_ MET688_9_5_STATUS_CODE_HALT : 77|3@1+ (1,0) [0|7] ""  C_ECU
 SG_ MET688_9_4_STATUS_HOOD_OPEN : 76|1@1+ (1,0) [0|1] ""  C_ECU
 SG_ MET688_9_3_STATUS_BSD_OFF : 75|1@1+ (1,0) [0|1] ""  C_ECU
 SG_ MET688_9_2_STATUS_BSD_FAIL : 74|1@1+ (1,0) [0|1] ""  C_ECU
 SG_ MET688_9_0_STATUS_SONAR_SYS_FAIL : 72|2@1+ (1,0) [0|3] ""  C_ECU
 SG_ MET688_8_5_STATUS_ABG_PASS_IND : 69|2@1+ (1,0) [0|3] ""  C_ECU
 SG_ MET688_8_4_STATUS_HEADLAMP_SMALL : 68|1@1+ (1,0) [0|1] ""  C_ECU
 SG_ MET688_8_2_STATUS_HDC : 66|2@1+ (1,0) [0|3] ""  C_ECU
 SG_ MET688_8_1_STATUS_CC_SET_IND : 65|1@1+ (1,0) [0|1] ""  C_ECU
 SG_ MET688_8_0_STATUS_CC_MAIN_IND : 64|1@1+ (1,0) [0|1] ""  C_ECU
 SG_ MET688_7_7_STATUS_FT_FOG : 63|1@1+ (1,0) [0|1] ""  C_ECU
 SG_ MET688_7_4_STATUS_SRH : 60|3@1+ (1,0) [0|7] ""  C_ECU
 SG_ MET688_7_1_STATUS_AHL : 57|3@1+ (1,0) [0|7] ""  C_ECU
 SG_ MET688_7_0_STATUS_HEADLAMP_HI : 56|1@1+ (1,0) [0|1] ""  C_ECU
 SG_ MET688_6_7_STATUS_AVH_ACT : 55|1@1+ (1,0) [0|1] ""  C_ECU
 SG_ MET688_6_6_STATUS_AVH_ON : 54|1@1+ (1,0) [0|1] ""  C_ECU
 SG_ MET688_6_4_STATUS_BREAK_IND : 52|2@1+ (1,0) [0|3] ""  C_ECU
 SG_ MET688_6_0_STATUS_WARN_SSP_SIG1 : 48|4@1+ (1,0) [0|21] ""  C_ECU
 SG_ MET688_5_4_STATUS_VDC_OFF : 44|1@1+ (1,0) [0|1] ""  C_ECU
 SG_ MET688_5_3_STATUS_CHG_WARN : 43|1@1+ (1,0) [0|1] ""  C_ECU
 SG_ MET688_5_2_STATUS_SEATBELT_PASS : 42|1@1+ (1,0) [0|1] ""  C_ECU
 SG_ MET688_5_1_STATUS_SEATBELT_DRVR : 41|1@1+ (1,0) [0|1] ""  C_ECU
 SG_ MET688_5_0_STATUS_EYESIGHT_FAIL : 40|1@1+ (1,0) [0|1] ""  C_ECU
 SG_ MET688_4_5_STATUS_EPS_WARN : 37|3@1+ (1,0) [0|7] ""  C_ECU
 SG_ MET688_4_3_STATUS_ABG_WARN : 35|2@1+ (1,0) [0|3] ""  C_ECU
 SG_ MET688_4_0_STATUS_TPMS_WARN : 32|3@1+ (1,0) [0|7] ""  C_ECU
 SG_ MET688_3_5_STATUS_EBD_WARN : 29|1@1+ (1,0) [0|1] ""  C_ECU
 SG_ MET688_3_4_STATUS_VDC_WARN : 28|1@1+ (1,0) [0|1] ""  C_ECU
 SG_ MET688_3_3_STATUS_ABS_WARN : 27|1@1+ (1,0) [0|1] ""  C_ECU
 SG_ MET688_3_1_STATUS_AWD_WARN : 25|2@1+ (1,0) [0|3] ""  C_ECU
 SG_ MET688_3_0_STATUS_WASHER_WARN : 24|1@1+ (1,0) [0|1] ""  C_ECU
 SG_ MET688_2_0_E2E_COUNTER : 16|8@1+ (1,0) [0|255] ""  C_ECU
 SG_ MET688_0_0_CRC : 0|16@1+ (1,0) [0|65535] ""  C_ECU

BO_ 1614 RKE64E: 8 C_ECU_GW
 SG_ RKE64E_6_0_BUZ_1SHOT_IN : 48|1@1+ (1,0) [0|1] ""  MET
 SG_ RKE64E_6_1_BUZ_2SHOT_IN : 49|1@1+ (1,0) [0|1] ""  MET
 SG_ RKE64E_6_2_REQ_WARNG_BAT_POWER : 50|1@1+ (1,0) [0|1] ""  MET
 SG_ RKE64E_4_0_TRANS_ID : 32|3@1+ (1,0) [0|4] "" Vector__XXX
 SG_ RKE64E_4_3_COUNTER : 35|2@1+ (1,0) [0|3] "" Vector__XXX
 SG_ RKE64E_4_5_TIME_ON_SW_KEY_LESS : 37|2@1+ (1,0) [0|3] "" Vector__XXX
 SG_ RKE64E_3_0_REQ_NOMAL_KEY_LESS : 24|8@1+ (1,0) [0|8] "" Vector__XXX
 SG_ RKE64E_1_0_MSG_COUNTER : 8|4@1+ (1,0) [0|15] "" Vector__XXX
 SG_ RKE64E_1_4_WAKE_UP_FRAME : 12|1@1+ (1,0) [0|1] "" Vector__XXX
 SG_ RKE64E_1_5_REQ_COMM_CONT : 13|1@1+ (1,0) [0|1] "" Vector__XXX
 SG_ RKE64E_1_6 : 14|1@1+ (1,0) [0|1] "" Vector__XXX
 SG_ RKE64E_0_0_CHECK_SUM : 0|8@1+ (1,0) [0|255] "" Vector__XXX

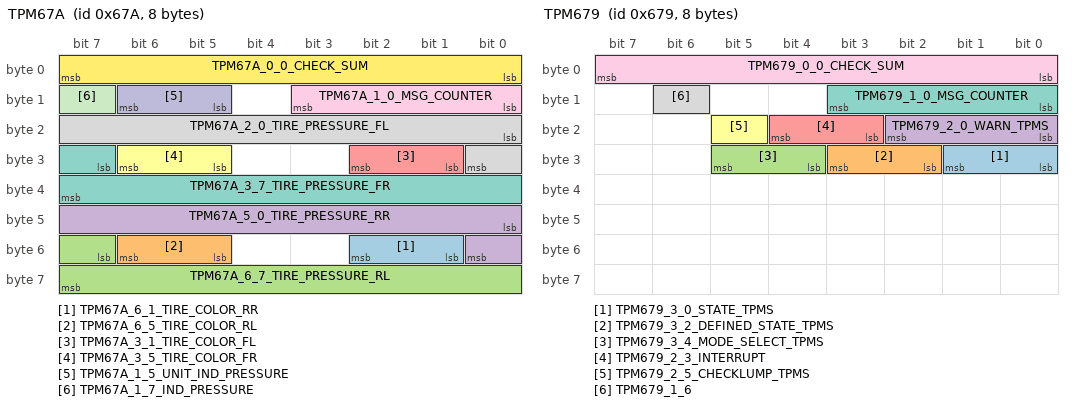
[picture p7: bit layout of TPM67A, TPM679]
BO_ 1658 TPM67A: 8 C_ECU_GW
 SG_ TPM67A_6_1_TIRE_COLOR_RR : 49|2@1+ (1,0) [0|3] ""  MET
 SG_ TPM67A_6_5_TIRE_COLOR_RL : 53|2@1+ (1,0) [0|3] ""  MET
 SG_ TPM67A_6_7_TIRE_PRESSURE_RL : 55|9@1+ (1,0) [0|511] ""  MET
 SG_ TPM67A_5_0_TIRE_PRESSURE_RR : 40|9@1+ (1,0) [0|511] ""  MET
 SG_ TPM67A_3_1_TIRE_COLOR_FL : 25|2@1+ (1,0) [0|3] ""  MET
 SG_ TPM67A_3_5_TIRE_COLOR_FR : 29|2@1+ (1,0) [0|3] ""  MET
 SG_ TPM67A_3_7_TIRE_PRESSURE_FR : 31|9@1+ (1,0) [0|511] ""  MET
 SG_ TPM67A_2_0_TIRE_PRESSURE_FL : 16|9@1+ (1,0) [0|511] ""  MET
 SG_ TPM67A_1_0_MSG_COUNTER : 8|4@1+ (1,0) [0|15] "" Vector__XXX
 SG_ TPM67A_1_5_UNIT_IND_PRESSURE : 13|2@1+ (1,0) [0|3] ""  MET
 SG_ TPM67A_1_7_IND_PRESSURE : 15|1@1+ (1,0) [0|1] ""  MET
 SG_ TPM67A_0_0_CHECK_SUM : 0|8@1+ (1,0) [0|255] "" Vector__XXX

BO_ 1657 TPM679: 8 C_ECU_GW
 SG_ TPM679_3_0_STATE_TPMS : 24|2@1+ (1,0) [0|3] ""  MET
 SG_ TPM679_3_2_DEFINED_STATE_TPMS : 26|2@1+ (1,0) [0|3] ""  MET
 SG_ TPM679_3_4_MODE_SELECT_TPMS : 28|2@1+ (1,0) [0|3] "" Vector__XXX
 SG_ TPM679_2_0_WARN_TPMS : 16|3@1+ (1,0) [0|7] ""  MET
 SG_ TPM679_2_3_INTERRUPT : 19|2@1+ (1,0) [0|2] ""  MET
 SG_ TPM679_2_5_CHECKLUMP_TPMS : 21|1@1+ (1,0) [0|1] ""  MET
 SG_ TPM679_1_0_MSG_COUNTER : 8|4@1+ (1,0) [0|15] "" Vector__XXX
 SG_ TPM679_1_6 : 14|1@1+ (1,0) [0|1] "" Vector__XXX
 SG_ TPM679_0_0_CHECK_SUM : 0|8@1+ (1,0) [0|255] "" Vector__XXX

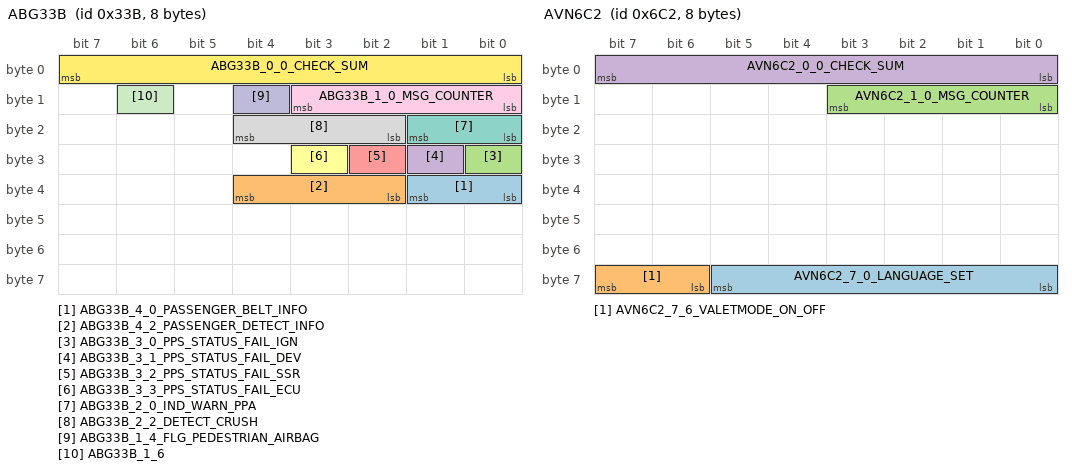
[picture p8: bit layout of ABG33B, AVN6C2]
BO_ 827 ABG33B: 8 C_ECU_GW
 SG_ ABG33B_4_0_PASSENGER_BELT_INFO : 32|2@1+ (1,0) [0|3] "" Vector__XXX
 SG_ ABG33B_4_2_PASSENGER_DETECT_INFO : 34|3@1+ (1,0) [0|7] "" Vector__XXX
 SG_ ABG33B_3_0_PPS_STATUS_FAIL_IGN : 24|1@1+ (1,0) [0|1] "" Vector__XXX
 SG_ ABG33B_3_1_PPS_STATUS_FAIL_DEV : 25|1@1+ (1,0) [0|1] "" Vector__XXX
 SG_ ABG33B_3_2_PPS_STATUS_FAIL_SSR : 26|1@1+ (1,0) [0|1] "" Vector__XXX
 SG_ ABG33B_3_3_PPS_STATUS_FAIL_ECU : 27|1@1+ (1,0) [0|1] "" Vector__XXX
 SG_ ABG33B_2_0_IND_WARN_PPA : 16|2@1+ (1,0) [0|3] ""  MET
 SG_ ABG33B_2_2_DETECT_CRUSH : 18|3@1+ (1,0) [0|7] "" Vector__XXX
 SG_ ABG33B_1_0_MSG_COUNTER : 8|4@1+ (1,0) [0|15] "" Vector__XXX
 SG_ ABG33B_1_4_FLG_PEDESTRIAN_AIRBAG : 12|1@1+ (1,0) [0|1] ""  MET
 SG_ ABG33B_1_6 : 14|1@1+ (1,0) [0|1] "" Vector__XXX
 SG_ ABG33B_0_0_CHECK_SUM : 0|8@1+ (1,0) [0|255] "" Vector__XXX

BO_ 826 ABG33A: 8 C_ECU_GW
 SG_ ABG33A_7_0_VELOCITYCHANGE_VX_MAX : 56|8@1+ (1,0) [-101|101] "km/h" Vector__XXX
 SG_ ABG33A_6_0_VELOCITYCHANGE_VX_MAX : 48|8@1+ (1,0) [-101|101] "km/h" Vector__XXX
 SG_ ABG33A_5_0_P_SIDE_ABG_DEPLOY : 40|1@1+ (1,0) [0|1] "" Vector__XXX
 SG_ ABG33A_5_1_D_SIDE_ABG_DEPLOY : 41|1@1+ (1,0) [0|1] "" Vector__XXX
 SG_ ABG33A_5_2_FRONT_FAR_ABG_DEPLOY : 42|1@1+ (1,0) [0|1] "" Vector__XXX
 SG_ ABG33A_5_3_REAR_FAR_ABG_DEPLOY : 43|1@1+ (1,0) [0|1] "" Vector__XXX
 SG_ ABG33A_5_4_REAR_RH_ABG_DEPLOY : 44|1@1+ (1,0) [0|1] "" Vector__XXX
 SG_ ABG33A_5_5_REAR_LH_ABG_DEPLOY : 45|1@1+ (1,0) [0|1] "" Vector__XXX
 SG_ ABG33A_5_6_P_CURTAIN_ABG_DEPLOY : 46|1@1+ (1,0) [0|1] "" Vector__XXX
 SG_ ABG33A_5_7_D_CURTAIN_ABG_DEPLOY : 47|1@1+ (1,0) [0|1] "" Vector__XXX
 SG_ ABG33A_4_0_D_FRONT_ABG_DEPLOY : 32|1@1+ (1,0) [0|1] "" Vector__XXX
 SG_ ABG33A_4_1_P_FRONT_ABG_DEPLOY : 33|1@1+ (1,0) [0|1] "" Vector__XXX
 SG_ ABG33A_4_2_P_ABG_DEPLOY : 34|1@1+ (1,0) [0|1] "" Vector__XXX
 SG_ ABG33A_4_3_D_ABG_DEPLOY : 35|1@1+ (1,0) [0|1] "" Vector__XXX
 SG_ ABG33A_4_4_P_BELT_PRETENTION : 36|1@1+ (1,0) [0|1] "" Vector__XXX
 SG_ ABG33A_4_5_D_BELT_PRETENTION : 37|1@1+ (1,0) [0|1] "" Vector__XXX
 SG_ ABG33A_4_6_D_KNEE_ABG_DEPLOY : 38|1@1+ (1,0) [0|1] "" Vector__XXX
 SG_ ABG33A_4_7_P_KNEE_ABG_DEPLOY : 39|1@1+ (1,0) [0|1] "" Vector__XXX
 SG_ ABG33A_3_0_BELT_WRNING_PASS : 24|2@1+ (1,0) [0|3] ""  MET
 SG_ ABG33A_3_2_BUCKLESW_DRVR : 26|2@1+ (1,0) [0|3] "" Vector__XXX
 SG_ ABG33A_3_4_OCCUPATION_PASS : 28|2@1+ (1,0) [0|3] "" Vector__XXX
 SG_ ABG33A_3_6_IND_ACT_ABG_PASS : 30|2@1+ (1,0) [0|3] ""  MET
 SG_ ABG33A_2_0_IND_WARN_ABG : 16|2@1+ (1,0) [0|3] ""  MET
 SG_ ABG33A_2_2_DETECT_CRUSH : 18|3@1+ (1,0) [0|7] "" Vector__XXX
 SG_ ABG33A_2_5_STATUS_CRUSH_ECALL : 21|3@1+ (1,0) [0|7] "" Vector__XXX
 SG_ ABG33A_1_0_MSG_COUNTER : 8|4@1+ (1,0) [0|15] "" Vector__XXX
 SG_ ABG33A_1_4_FLG_ABGIND_CTRL : 12|1@1+ (1,0) [0|1] ""  MET
 SG_ ABG33A_1_5_REQ_COMM_CONT : 13|1@1+ (1,0) [0|1] "" Vector__XXX
 SG_ ABG33A_1_6_COLLISION_COUNTER : 14|2@1+ (1,0) [0|3] "" Vector__XXX
 SG_ ABG33A_0_0_CHECK_SUM : 0|8@1+ (1,0) [0|255] "" Vector__XXX

BO_ 961 DMS3C1: 8 C_ECU_GW
 SG_ DMS3C1_7_4_SHORT_DIST_DETECT : 60|1@1+ (1,0) [0|1] ""  MET
 SG_ DMS3C1_7_5_PRESENCE_DETECT : 61|1@1+ (1,0) [0|1] "" Vector__XXX
 SG_ DMS3C1_7_6_RADER_EQUIP : 62|1@1+ (1,0) [0|1] "" Vector__XXX
 SG_ DMS3C1_7_7_LOSING_POSTURE_DETECT : 63|1@1+ (1,0) [0|1] ""  MET
 SG_ DMS3C1_6_0_ID_RECOG_CANCEL : 48|1@1+ (1,0) [0|1] "" Vector__XXX
 SG_ DMS3C1_6_1_ID_ENABLE_FLAG : 49|1@1+ (1,0) [0|1] "" Vector__XXX
 SG_ DMS3C1_6_2_PERMIT_AVN_FLAG : 50|1@1+ (1,0) [0|1] "" Vector__XXX
 SG_ DMS3C1_6_4_DISTRACTION_STATUS : 52|1@1+ (1,0) [0|1] "" Vector__XXX
 SG_ DMS3C1_6_5_DROWSINESS_STATUS : 53|1@1+ (1,0) [0|1] "" Vector__XXX
 SG_ DMS3C1_6_6_DROWSINESS_LV2_STATUS : 54|1@1+ (1,0) [0|1] "" Vector__XXX
 SG_ DMS3C1_6_7_NOT_DETECTED_STATUS : 55|1@1+ (1,0) [0|1] "" Vector__XXX
 SG_ DMS3C1_5_0_ID_LIST : 40|5@1+ (1,0) [0|31] "" Vector__XXX
 SG_ DMS3C1_5_5_ID_EDIT_FLAG : 45|3@1+ (1,0) [0|6] ""  MET
 SG_ DMS3C1_4_0_DMS_IND_REQ_FLAG : 32|3@1+ (1,0) [0|7] ""  MET
 SG_ DMS3C1_4_3_DMS_RECOG_STATUS : 35|1@1+ (1,0) [0|1] ""  MET
 SG_ DMS3C1_4_4_DRIVER_STATUS : 36|4@1+ (1,0) [0|3] "" Vector__XXX
 SG_ DMS3C1_3_0_DRIVER_REGIST_ID : 24|4@1+ (1,0) [0|15] ""  MET
 SG_ DMS3C1_3_4_CUST_EDIT_FLAG : 28|2@1+ (1,0) [0|3] "" Vector__XXX
 SG_ DMS3C1_3_6_ID_RECOG_FLAG : 30|1@1+ (1,0) [0|1] ""  MET
 SG_ DMS3C1_2_0_LEVEL_DROWS : 16|3@1+ (1,0) [0|2] ""  MET
 SG_ DMS3C1_2_3_DROWS_DETECT_FLAG : 19|1@1+ (1,0) [0|1] ""  MET
 SG_ DMS3C1_2_7_DIST_DETECT_FLAG : 23|1@1+ (1,0) [0|1] ""  MET
 SG_ DMS3C1_1_0_MSG_COUNTER : 8|4@1+ (1,0) [0|15] ""  MET
 SG_ DMS3C1_1_4_WAKE_UP_FRAME : 12|1@1+ (1,0) [0|1] "" Vector__XXX
 SG_ DMS3C1_1_5_REQ_COMM_CONT : 13|1@1+ (1,0) [0|1] "" Vector__XXX
 SG_ DMS3C1_1_7_EYE_DIST_FLAG : 15|1@1+ (1,0) [0|1] "" Vector__XXX
 SG_ DMS3C1_0_0_CHKSUM : 0|8@1+ (1,0) [0|255] ""  MET

BO_ 1290 DMS50A: 8 C_ECU_GW
 SG_ DMS50A_1_4_ActiveWakeUpBit : 12|1@1+ (1,0) [0|1] ""  MET
 SG_ DMS50A_0_0_SourceNodeID : 0|8@1+ (1,0) [0|255] ""  MET

BO_ 1730 AVN6C2: 8 C_ECU_GW
 SG_ AVN6C2_7_0_LANGUAGE_SET : 61|6@0+ (1,0) [0|33] ""  MET
 SG_ AVN6C2_7_6_VALETMODE_ON_OFF : 63|2@0+ (1,0) [0|3] "" Vector__XXX
 SG_ AVN6C2_1_0_MSG_COUNTER : 11|4@0+ (1,0) [0|15] "" Vector__XXX
 SG_ AVN6C2_0_0_CHECK_SUM : 7|8@0+ (1,0) [0|255] "" Vector__XXX

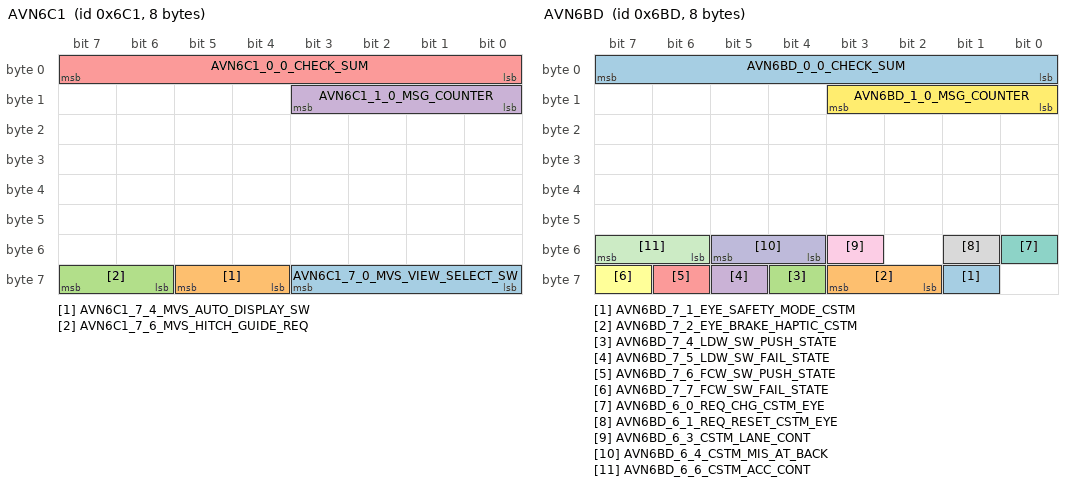
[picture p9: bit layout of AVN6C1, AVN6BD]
BO_ 1729 AVN6C1: 8 C_ECU_GW
 SG_ AVN6C1_7_0_MVS_VIEW_SELECT_SW : 59|4@0+ (1,0) [0|6] ""  MVS
 SG_ AVN6C1_7_4_MVS_AUTO_DISPLAY_SW : 61|2@0+ (1,0) [0|3] ""  MVS
 SG_ AVN6C1_7_6_MVS_HITCH_GUIDE_REQ : 63|2@0+ (1,0) [0|3] ""  MVS
 SG_ AVN6C1_1_0_MSG_COUNTER : 11|4@0+ (1,0) [0|15] ""  MVS
 SG_ AVN6C1_0_0_CHECK_SUM : 7|8@0+ (1,0) [0|255] ""  MVS

BO_ 1725 AVN6BD: 8 C_ECU_GW
 SG_ AVN6BD_7_1_EYE_SAFETY_MODE_CSTM : 57|1@0+ (1,0) [0|1] "" Vector__XXX
 SG_ AVN6BD_7_2_EYE_BRAKE_HAPTIC_CSTM : 59|2@0+ (1,0) [0|3] "" Vector__XXX
 SG_ AVN6BD_7_4_LDW_SW_PUSH_STATE : 60|1@0+ (1,0) [0|1] "" Vector__XXX
 SG_ AVN6BD_7_5_LDW_SW_FAIL_STATE : 61|1@0+ (1,0) [0|1] "" Vector__XXX
 SG_ AVN6BD_7_6_FCW_SW_PUSH_STATE : 62|1@0+ (1,0) [0|1] "" Vector__XXX
 SG_ AVN6BD_7_7_FCW_SW_FAIL_STATE : 63|1@0+ (1,0) [0|1] "" Vector__XXX
 SG_ AVN6BD_6_0_REQ_CHG_CSTM_EYE : 48|1@0+ (1,0) [0|1] "" Vector__XXX
 SG_ AVN6BD_6_1_REQ_RESET_CSTM_EYE : 49|1@0+ (1,0) [0|1] ""  MVS
 SG_ AVN6BD_6_3_CSTM_LANE_CONT : 51|1@0+ (1,0) [0|1] "" Vector__XXX
 SG_ AVN6BD_6_4_CSTM_MIS_AT_BACK : 53|2@0+ (1,0) [0|3] "" Vector__XXX
 SG_ AVN6BD_6_6_CSTM_ACC_CONT : 55|2@0+ (1,0) [0|3] "" Vector__XXX
 SG_ AVN6BD_1_0_MSG_COUNTER : 11|4@0+ (1,0) [0|15] ""  MVS
 SG_ AVN6BD_0_0_CHECK_SUM : 7|8@0+ (1,0) [0|255] ""  MVS

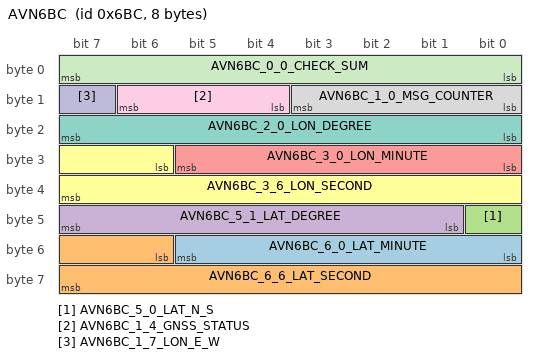
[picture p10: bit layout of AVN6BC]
BO_ 1724 AVN6BC: 8 C_ECU_GW
 SG_ AVN6BC_6_0_LAT_MINUTE : 48|6@1+ (1,0) [0|59] "" Vector__XXX
 SG_ AVN6BC_6_6_LAT_SECOND : 54|10@1+ (0.1,0) [0|59.9] "" Vector__XXX
 SG_ AVN6BC_5_0_LAT_N_S : 40|1@1+ (1,0) [0|1] "" Vector__XXX
 SG_ AVN6BC_5_1_LAT_DEGREE : 41|7@1+ (1,0) [0|90] "" Vector__XXX
 SG_ AVN6BC_3_0_LON_MINUTE : 24|6@1+ (1,0) [0|59] "" Vector__XXX
 SG_ AVN6BC_3_6_LON_SECOND : 30|10@1+ (0.1,0) [0|59.9] "" Vector__XXX
 SG_ AVN6BC_2_0_LON_DEGREE : 16|8@1+ (1,0) [0|180] "" Vector__XXX
 SG_ AVN6BC_1_0_MSG_COUNTER : 8|4@1+ (1,0) [0|15] "" Vector__XXX
 SG_ AVN6BC_1_4_GNSS_STATUS : 12|3@1+ (1,0) [0|7] "" Vector__XXX
 SG_ AVN6BC_1_7_LON_E_W : 15|1@1+ (1,0) [0|1] "" Vector__XXX
 SG_ AVN6BC_0_0_CHECK_SUM : 0|8@1+ (1,0) [0|255] "" Vector__XXX

BO_ 1723 AVN6BB: 8 C_ECU_GW
 SG_ AVN6BB_7_0_ISA_IACC_OFFSET_CSTM : 56|5@1+ (1,0) [0|20] "" Vector__XXX
 SG_ AVN6BB_7_5_EYE_TOLLBOOTH_DECEL : 61|1@1+ (1,0) [0|1] "" Vector__XXX
 SG_ AVN6BB_7_6_EYE_CURVE_DECEL_CSTM : 62|1@1+ (1,0) [0|1] "" Vector__XXX
 SG_ AVN6BB_7_7_EYE_GREEN_LIGHT_CSTM : 63|1@1+ (1,0) [0|1] "" Vector__XXX
 SG_ AVN6BB_6_0_CCU_FAIL : 48|1@1+ (1,0) [0|1] "" Vector__XXX
 SG_ AVN6BB_6_1_EYE_P_CR_CSTM : 49|1@1+ (1,0) [0|1] "" Vector__XXX
 SG_ AVN6BB_6_2_EYE_ALK_B_LDW_CSTM : 50|2@1+ (1,0) [0|3] "" Vector__XXX
 SG_ AVN6BB_6_4_EYE_CSTM_REQ : 52|1@1+ (1,0) [0|1] "" Vector__XXX
 SG_ AVN6BB_6_5_EYE_ELK_CSTM : 53|1@1+ (1,0) [0|1] "" Vector__XXX
 SG_ AVN6BB_6_6_EYE_ALKB_EDGE_CSTM : 54|1@1+ (1,0) [0|1] "" Vector__XXX
 SG_ AVN6BB_6_7_FCW_ON_OFF : 55|1@1+ (1,0) [0|1] "" Vector__XXX
 SG_ AVN6BB_5_0_DMS_SELECT_ID : 40|4@1+ (1,0) [0|5] "" Vector__XXX
 SG_ AVN6BB_5_4_TPMS_TH_MODE_CSTM : 44|2@1+ (1,0) [0|3] "" Vector__XXX
 SG_ AVN6BB_5_6_DMS_SET_REQ : 46|1@1+ (1,0) [0|1] "" Vector__XXX
 SG_ AVN6BB_5_7_DMS_RECOG_SET : 47|1@1+ (1,0) [0|1] "" Vector__XXX
 SG_ AVN6BB_4_0_DMS_EDIT_REQ : 32|4@1+ (1,0) [0|15] "" Vector__XXX
 SG_ AVN6BB_4_4_VEHICLE_DEMO : 36|1@1+ (1,0) [0|1] "" Vector__XXX
 SG_ AVN6BB_4_5_SRVD_CSTM_REQ : 37|1@1+ (1,0) [0|1] "" Vector__XXX
 SG_ AVN6BB_4_6_SEAT_RESET_REQ : 38|1@1+ (1,0) [0|1] "" Vector__XXX
 SG_ AVN6BB_4_7_SEATAWAY_SET_CSTM : 39|1@1+ (1,0) [0|1] "" Vector__XXX
 SG_ AVN6BB_3_0_SRVD_ON_OFF : 24|1@1+ (1,0) [0|1] "" Vector__XXX
 SG_ AVN6BB_3_1_PRG_RESET_REQ : 25|1@1+ (1,0) [0|1] "" Vector__XXX
 SG_ AVN6BB_3_2_PRG_MEM_CSTM : 26|1@1+ (1,0) [0|1] "" Vector__XXX
 SG_ AVN6BB_3_3_DMS_ON_OFF : 27|1@1+ (1,0) [0|1] "" Vector__XXX
 SG_ AVN6BB_3_4_MIR_RESET_REQ : 28|1@1+ (1,0) [0|1] "" Vector__XXX
 SG_ AVN6BB_3_5_MIR_AFOLD_CSTM : 29|1@1+ (1,0) [0|1] "" Vector__XXX
 SG_ AVN6BB_3_6_MIR_RTILT_CSTM : 30|1@1+ (1,0) [0|1] "" Vector__XXX
 SG_ AVN6BB_3_7_EYE_TSA_CSTM : 31|1@1+ (1,0) [0|1] "" Vector__XXX
 SG_ AVN6BB_2_0_AVH_ON_OFF : 16|2@1+ (1,0) [0|3] "" Vector__XXX
 SG_ AVN6BB_2_2_VDC_ON_OFF : 18|2@1+ (1,0) [0|3] ""  MET
 SG_ AVN6BB_2_4_CCU_HALT_RESET : 20|1@1+ (1,0) [0|1] "" Vector__XXX
 SG_ AVN6BB_2_5_EYE_LDW_TIMING_CSTM : 21|1@1+ (1,0) [0|1] "" Vector__XXX
 SG_ AVN6BB_2_6_FCW_CSTM : 22|2@1+ (1,0) [0|3] "" Vector__XXX
 SG_ AVN6BB_1_0_MSG_COUNTER : 8|4@1+ (1,0) [0|15] ""  RCR_R,RCR_L
 SG_ AVN6BB_1_4_EYE_WARN_CSTM : 12|1@1+ (1,0) [0|1] "" Vector__XXX
 SG_ AVN6BB_1_5_EYE_FCTI_CSTM : 13|2@1+ (1,0) [0|3] "" Vector__XXX
 SG_ AVN6BB_1_7_LDW_WARNING_ON_OFF : 15|1@1+ (1,0) [0|1] "" Vector__XXX
 SG_ AVN6BB_0_0_CHECK_SUM : 0|8@1+ (1,0) [0|255] ""  RCR_R,RCR_L

BO_ 1722 AVN6BA: 8 C_ECU_GW
 SG_ AVN6BA_7_0_GUIDE_LINE_REAR : 56|1@1+ (1,0) [0|1] "" Vector__XXX
 SG_ AVN6BA_7_1_GUIDE_LINE_SIDE : 57|1@1+ (1,0) [0|1] "" Vector__XXX
 SG_ AVN6BA_7_2_GUIDE_LINE_FRONT : 58|1@1+ (1,0) [0|1] "" Vector__XXX
 SG_ AVN6BA_7_3_STEER_ANGLE_INTERLOCK : 59|1@1+ (1,0) [0|1] "" Vector__XXX
 SG_ AVN6BA_7_4_BACK_CAMERA_DELAY : 60|1@1+ (1,0) [0|1] "" Vector__XXX
 SG_ AVN6BA_7_5_REQ_STOP_CAMERA_OUT : 61|1@1+ (1,0) [0|1] "" Vector__XXX
 SG_ AVN6BA_7_6_VIEW_CHANGE_SW : 62|2@1+ (1,0) [0|3] "" Vector__XXX
 SG_ AVN6BA_6_0_CLIMAITE_PA_TEMP : 48|6@1- (0.5,13) [1|44] "℃/?" Vector__XXX
 SG_ AVN6BA_6_6_CLIMATE_SYNC : 54|1@1+ (1,0) [0|1] "" Vector__XXX
 SG_ AVN6BA_6_7_CLIMATE_F_DEF : 55|1@1+ (1,0) [0|1] "" Vector__XXX
 SG_ AVN6BA_5_0_CLIMAITE_DR_TEMP : 40|6@1- (0.5,13) [1|44] "℃/?" Vector__XXX
 SG_ AVN6BA_5_6_CLIMAITE_AUTO : 46|1@1+ (1,0) [0|1] "" Vector__XXX
 SG_ AVN6BA_5_7_CLIMAITE_MAX_AC : 47|1@1+ (1,0) [0|1] "" Vector__XXX
 SG_ AVN6BA_4_0_CLIMAITE_VR : 32|3@1+ (1,0) [0|4] "" Vector__XXX
 SG_ AVN6BA_4_3_CLIMATE_AC : 35|1@1+ (1,0) [0|1] "" Vector__XXX
 SG_ AVN6BA_4_4_CLIMAITE_FAN : 36|4@1+ (1,0) [0|15] "" Vector__XXX
 SG_ AVN6BA_3_0_PERSONAL_IC_SH : 24|3@1+ (1,0) [0|7] "" Vector__XXX
 SG_ AVN6BA_3_4_CSTM_SONNER : 28|1@1+ (1,0) [0|1] "" Vector__XXX
 SG_ AVN6BA_3_5_CSTM_RAB : 29|1@1+ (1,0) [0|1] "" Vector__XXX
 SG_ AVN6BA_3_6_REQ_CHG_CSTM_RAB : 30|1@1+ (1,0) [0|1] "" Vector__XXX
 SG_ AVN6BA_3_7_CLIMATE_R_DEF : 31|1@1+ (1,0) [0|1] "" Vector__XXX
 SG_ AVN6BA_2_0_CLIMATE_PTC : 16|1@1+ (1,0) [0|1] "" Vector__XXX
 SG_ AVN6BA_2_1_CLIMATE_MODE : 17|1@1+ (1,0) [0|1] "" Vector__XXX
 SG_ AVN6BA_2_2_CLIMATE_SEAT_C_L : 18|1@1+ (1,0) [0|1] "" Vector__XXX
 SG_ AVN6BA_2_3_CLIMATE_SEAT_C_R : 19|1@1+ (1,0) [0|1] "" Vector__XXX
 SG_ AVN6BA_2_4_CLIMATE_SEAT_H_L : 20|1@1+ (1,0) [0|1] "" Vector__XXX
 SG_ AVN6BA_2_5_CLIMATE_SEAT_H_R : 21|1@1+ (1,0) [0|1] "" Vector__XXX
 SG_ AVN6BA_2_6_CLIMATE_INNER_AIR : 22|1@1+ (1,0) [0|1] "" Vector__XXX
 SG_ AVN6BA_2_7_CLIMATE_ON_OFF : 23|1@1+ (1,0) [0|1] "" Vector__XXX
 SG_ AVN6BA_1_0_MSG_COUNTER : 8|4@1+ (1,0) [0|15] "" Vector__XXX
 SG_ AVN6BA_1_4_CLIMAITE_STATUS : 12|3@1+ (1,0) [0|7] "" Vector__XXX
 SG_ AVN6BA_1_7_CLIMAITE_ON_OFF : 15|1@1+ (1,0) [0|1] "" Vector__XXX
 SG_ AVN6BA_0_0_CHECK_SUM : 0|8@1+ (1,0) [0|255] "" Vector__XXX

BO_ 1713 AVN6B1: 8 C_ECU_GW
 SG_ AVN6B1_7_1_PRESENT_YEAR : 57|7@1+ (1,0) [0|126] "Year" Vector__XXX
 SG_ AVN6B1_6_0_PRESENT_DAY : 48|5@1+ (1,0) [1|31] "Day" Vector__XXX
 SG_ AVN6B1_6_5_PRESENT_MONTH : 53|4@1+ (1,0) [1|12] "Month" Vector__XXX
 SG_ AVN6B1_5_0_FAIL_AVN : 40|1@1+ (1,0) [0|1] "" Vector__XXX
 SG_ AVN6B1_5_1_IN_OPERATION : 41|1@1+ (1,0) [0|1] "" Vector__XXX
 SG_ AVN6B1_5_2_TYPE_NAVI : 42|2@1+ (1,0) [0|3] "" Vector__XXX
 SG_ AVN6B1_5_4_XM_ENABLE : 44|2@1+ (1,0) [0|3] "" Vector__XXX
 SG_ AVN6B1_5_6_FLG_ABLE_WELCOME_SCL : 46|1@1+ (1,0) [0|1] "" Vector__XXX
 SG_ AVN6B1_5_7_STEER_ANGLE_INTERLOCK : 47|1@1+ (1,0) [0|1] ""  MVS
 SG_ AVN6B1_4_0_PRESENT_TIME_SEC : 32|6@1+ (1,0) [0|59] "s" Vector__XXX
 SG_ AVN6B1_4_7_BACK_CAMERA_DELAY : 39|1@1+ (1,0) [0|1] ""  MVS
 SG_ AVN6B1_3_0_PRESENT_TIME_MIN : 24|6@1+ (1,0) [0|59] "m"  MET
 SG_ AVN6B1_3_7_MVS_FTSNR_INTERRUPT : 31|1@1+ (1,0) [0|1] "" Vector__XXX
 SG_ AVN6B1_2_0_GPS_CLOCK_FLG : 16|1@1+ (1,0) [0|1] ""  MET
 SG_ AVN6B1_2_1_PRESENT_TIME_HOUR : 17|5@1+ (1,0) [0|23] "h"  MET
 SG_ AVN6B1_2_6_TIME_FORMAT : 22|2@1+ (1,0) [0|3] ""  MET
 SG_ AVN6B1_1_0_MSG_COUNTER : 8|4@1+ (1,0) [0|15] ""  MVS
 SG_ AVN6B1_1_4_WAKE_UP_FRAME : 12|1@1+ (1,0) [0|1] "" Vector__XXX
 SG_ AVN6B1_1_5_REQ_COMM_CONT : 13|1@1+ (1,0) [0|1] "" Vector__XXX
 SG_ AVN6B1_1_6_ACTIVE_AVN_CSTM : 14|1@1+ (1,0) [0|1] "" Vector__XXX
 SG_ AVN6B1_1_7_REQ_STOP_CAMERA_OUT : 15|1@1+ (1,0) [0|1] ""  MVS
 SG_ AVN6B1_0_0_CHECK_SUM : 0|8@1+ (1,0) [0|255] ""  MVS

CM_ SG_ 2564481196 MVS18DAE0AC_DIAG_DATA_EXT7 "ﾃﾞｰﾀ
";
CM_ SG_ 2564481196 MVS18DAE0AC_DIAG_DATA_EXT6 "ﾃﾞｰﾀ
";
CM_ SG_ 2564481196 MVS18DAE0AC_DIAG_DATA_EXT5 "ﾃﾞｰﾀ
";
CM_ SG_ 2564481196 MVS18DAE0AC_DIAG_DATA_EXT4 "ﾃﾞｰﾀ
";
CM_ SG_ 2564481196 MVS18DAE0AC_DIAG_DATA_EXT3 "ﾃﾞｰﾀ
";
CM_ SG_ 2564481196 MVS18DAE0AC_DIAG_DATA_EXT2 "ﾃﾞｰﾀ
";
CM_ SG_ 2564481196 MVS18DAE0AC_DIAG_DATA_EXT1 "ﾃﾞｰﾀ
";
CM_ SG_ 2564481196 MVS18DAE0AC_DIAG_DATA "ﾃﾞｰﾀ
";
CM_ SG_ 2564467936 DNT18DAACE0_DIAG_DATA_EXT7 "ﾃﾞｰﾀ
";
CM_ SG_ 2564467936 DNT18DAACE0_DIAG_DATA_EXT6 "ﾃﾞｰﾀ
";
CM_ SG_ 2564467936 DNT18DAACE0_DIAG_DATA_EXT5 "ﾃﾞｰﾀ
";
CM_ SG_ 2564467936 DNT18DAACE0_DIAG_DATA_EXT4 "ﾃﾞｰﾀ
";
CM_ SG_ 2564467936 DNT18DAACE0_DIAG_DATA_EXT3 "ﾃﾞｰﾀ
";
CM_ SG_ 2564467936 DNT18DAACE0_DIAG_DATA_EXT2 "ﾃﾞｰﾀ
";
CM_ SG_ 2564467936 DNT18DAACE0_DIAG_DATA_EXT1 "ﾃﾞｰﾀ
";
CM_ SG_ 2564467936 DNT18DAACE0_DIAG_DATA "ﾃﾞｰﾀ
";
CM_ SG_ 2564481213 RCR18DAE0BD_DIAG_DATA "ﾃﾞｰﾀ
";
CM_ SG_ 2564472288 DNT18DABDE0_DIAG_DATA "ﾃﾞｰﾀ
";
CM_ SG_ 2564481212 RCR18DAE0BC_DIAG_DATA "ﾃﾞｰﾀ
";
CM_ SG_ 2564472032 DNT18DABCE0_DIAG_DATA "ﾃﾞｰﾀ
";
CM_ SG_ 2564481195 SNR18DAE0AB_DIAG_DATA_EXT7 "ﾃﾞｰﾀ
";
CM_ SG_ 2564481195 SNR18DAE0AB_DIAG_DATA_EXT6 "ﾃﾞｰﾀ
";
CM_ SG_ 2564481195 SNR18DAE0AB_DIAG_DATA_EXT5 "ﾃﾞｰﾀ
";
CM_ SG_ 2564481195 SNR18DAE0AB_DIAG_DATA_EXT4 "ﾃﾞｰﾀ
";
CM_ SG_ 2564481195 SNR18DAE0AB_DIAG_DATA_EXT3 "ﾃﾞｰﾀ
";
CM_ SG_ 2564481195 SNR18DAE0AB_DIAG_DATA_EXT2 "ﾃﾞｰﾀ
";
CM_ SG_ 2564481195 SNR18DAE0AB_DIAG_DATA_EXT1 "ﾃﾞｰﾀ
";
CM_ SG_ 2564481195 SNR18DAE0AB_DIAG_DATA "ﾃﾞｰﾀ
";
CM_ SG_ 2564467680 DNT18DAABE0_DIAG_DATA_EXT7 "ﾃﾞｰﾀ
";
CM_ SG_ 2564467680 DNT18DAABE0_DIAG_DATA_EXT6 "ﾃﾞｰﾀ
";
CM_ SG_ 2564467680 DNT18DAABE0_DIAG_DATA_EXT5 "ﾃﾞｰﾀ
";
CM_ SG_ 2564467680 DNT18DAABE0_DIAG_DATA_EXT4 "ﾃﾞｰﾀ
";
CM_ SG_ 2564467680 DNT18DAABE0_DIAG_DATA_EXT3 "ﾃﾞｰﾀ
";
CM_ SG_ 2564467680 DNT18DAABE0_DIAG_DATA_EXT2 "ﾃﾞｰﾀ
";
CM_ SG_ 2564467680 DNT18DAABE0_DIAG_DATA_EXT1 "ﾃﾞｰﾀ
";
CM_ SG_ 2564467680 DNT18DAABE0_DIAG_DATA "ﾃﾞｰﾀ
";
CM_ SG_ 2564481047 MET18DAE017_DIAG_DATA_EXT7 "ﾃﾞｰﾀ
";
CM_ SG_ 2564481047 MET18DAE017_DIAG_DATA_EXT6 "ﾃﾞｰﾀ
";
CM_ SG_ 2564481047 MET18DAE017_DIAG_DATA_EXT5 "ﾃﾞｰﾀ
";
CM_ SG_ 2564481047 MET18DAE017_DIAG_DATA_EXT4 "ﾃﾞｰﾀ
";
CM_ SG_ 2564481047 MET18DAE017_DIAG_DATA_EXT3 "ﾃﾞｰﾀ
";
CM_ SG_ 2564481047 MET18DAE017_DIAG_DATA_EXT2 "ﾃﾞｰﾀ
";
CM_ SG_ 2564481047 MET18DAE017_DIAG_DATA_EXT1 "ﾃﾞｰﾀ
";
CM_ SG_ 2564481047 MET18DAE017_DIAG_DATA "ﾃﾞｰﾀ
";
CM_ SG_ 2564429792 DNT18DA17E0_DIAG_DATA_EXT7 "ﾃﾞｰﾀ
";
CM_ SG_ 2564429792 DNT18DA17E0_DIAG_DATA_EXT6 "ﾃﾞｰﾀ
";
CM_ SG_ 2564429792 DNT18DA17E0_DIAG_DATA_EXT5 "ﾃﾞｰﾀ
";
CM_ SG_ 2564429792 DNT18DA17E0_DIAG_DATA_EXT4 "ﾃﾞｰﾀ
";
CM_ SG_ 2564429792 DNT18DA17E0_DIAG_DATA_EXT3 "ﾃﾞｰﾀ
";
CM_ SG_ 2564429792 DNT18DA17E0_DIAG_DATA_EXT2 "ﾃﾞｰﾀ
";
CM_ SG_ 2564429792 DNT18DA17E0_DIAG_DATA_EXT1 "ﾃﾞｰﾀ
";
CM_ SG_ 2564429792 DNT18DA17E0_DIAG_DATA "ﾃﾞｰﾀ
";
CM_ SG_ 2564550625 CECU18DBEFE1_DIAG_DATA "ﾃﾞｰﾀ
";
CM_ SG_ 2564550624 DNT18DBEFE0_DIAG_DATA "ﾃﾞｰﾀ
";
CM_ SG_ 1832 DNT728_7_0_DIAG_DATA "ﾃﾞｰﾀ
";
CM_ SG_ 1832 DNT728_2_0_DIAG_N_PCI_OR_DATA "N_PCI　 or 　ﾃﾞｰﾀ
";
CM_ SG_ 1832 DNT728_1_0_DIAG_N_PCI_OR_DATA "N_PCI　 or 　ﾃﾞｰﾀ
";
CM_ SG_ 1832 DNT728_0_0_DIAG_N_PCI "N_PCI
";
CM_ SG_ 2564481303 MET18DAE117_DIAG_DATA_EXT7 "ﾃﾞｰﾀ
";
CM_ SG_ 2564481303 MET18DAE117_DIAG_DATA_EXT6 "ﾃﾞｰﾀ
";
CM_ SG_ 2564481303 MET18DAE117_DIAG_DATA_EXT5 "ﾃﾞｰﾀ
";
CM_ SG_ 2564481303 MET18DAE117_DIAG_DATA_EXT4 "ﾃﾞｰﾀ
";
CM_ SG_ 2564481303 MET18DAE117_DIAG_DATA_EXT3 "ﾃﾞｰﾀ
";
CM_ SG_ 2564481303 MET18DAE117_DIAG_DATA_EXT2 "ﾃﾞｰﾀ
";
CM_ SG_ 2564481303 MET18DAE117_DIAG_DATA_EXT1 "ﾃﾞｰﾀ
";
CM_ SG_ 2564481303 MET18DAE117_DIAG_DATA "ﾃﾞｰﾀ
";
CM_ SG_ 2564429793 CECU18DA17E1_DIAG_DATA_EXT7 "ﾃﾞｰﾀ
";
CM_ SG_ 2564429793 CECU18DA17E1_DIAG_DATA_EXT6 "ﾃﾞｰﾀ
";
CM_ SG_ 2564429793 CECU18DA17E1_DIAG_DATA_EXT5 "ﾃﾞｰﾀ
";
CM_ SG_ 2564429793 CECU18DA17E1_DIAG_DATA_EXT4 "ﾃﾞｰﾀ
";
CM_ SG_ 2564429793 CECU18DA17E1_DIAG_DATA_EXT3 "ﾃﾞｰﾀ
";
CM_ SG_ 2564429793 CECU18DA17E1_DIAG_DATA_EXT2 "ﾃﾞｰﾀ
";
CM_ SG_ 2564429793 CECU18DA17E1_DIAG_DATA_EXT1 "ﾃﾞｰﾀ
";
CM_ SG_ 2564429793 CECU18DA17E1_DIAG_DATA "ﾃﾞｰﾀ
";
CM_ SG_ 2564481452 MVS18DAE1AC_DIAG_DATA_EXT7 "ﾃﾞｰﾀ
";
CM_ SG_ 2564481452 MVS18DAE1AC_DIAG_DATA_EXT6 "ﾃﾞｰﾀ
";
CM_ SG_ 2564481452 MVS18DAE1AC_DIAG_DATA_EXT5 "ﾃﾞｰﾀ
";
CM_ SG_ 2564481452 MVS18DAE1AC_DIAG_DATA_EXT4 "ﾃﾞｰﾀ
";
CM_ SG_ 2564481452 MVS18DAE1AC_DIAG_DATA_EXT3 "ﾃﾞｰﾀ
";
CM_ SG_ 2564481452 MVS18DAE1AC_DIAG_DATA_EXT2 "ﾃﾞｰﾀ
";
CM_ SG_ 2564481452 MVS18DAE1AC_DIAG_DATA_EXT1 "ﾃﾞｰﾀ
";
CM_ SG_ 2564481452 MVS18DAE1AC_DIAG_DATA "ﾃﾞｰﾀ
";
CM_ SG_ 2564467937 CECU18DAACE1_DIAG_DATA_EXT7 "ﾃﾞｰﾀ
";
CM_ SG_ 2564467937 CECU18DAACE1_DIAG_DATA_EXT6 "ﾃﾞｰﾀ
";
CM_ SG_ 2564467937 CECU18DAACE1_DIAG_DATA_EXT5 "ﾃﾞｰﾀ
";
CM_ SG_ 2564467937 CECU18DAACE1_DIAG_DATA_EXT4 "ﾃﾞｰﾀ
";
CM_ SG_ 2564467937 CECU18DAACE1_DIAG_DATA_EXT3 "ﾃﾞｰﾀ
";
CM_ SG_ 2564467937 CECU18DAACE1_DIAG_DATA_EXT2 "ﾃﾞｰﾀ
";
CM_ SG_ 2564467937 CECU18DAACE1_DIAG_DATA_EXT1 "ﾃﾞｰﾀ
";
CM_ SG_ 2564467937 CECU18DAACE1_DIAG_DATA "ﾃﾞｰﾀ
";
CM_ SG_ 2564481451 SNR18DAE1AB_DIAG_DATA_EXT7 "ﾃﾞｰﾀ
";
CM_ SG_ 2564481451 SNR18DAE1AB_DIAG_DATA_EXT6 "ﾃﾞｰﾀ
";
CM_ SG_ 2564481451 SNR18DAE1AB_DIAG_DATA_EXT5 "ﾃﾞｰﾀ
";
CM_ SG_ 2564481451 SNR18DAE1AB_DIAG_DATA_EXT4 "ﾃﾞｰﾀ
";
CM_ SG_ 2564481451 SNR18DAE1AB_DIAG_DATA_EXT3 "ﾃﾞｰﾀ
";
CM_ SG_ 2564481451 SNR18DAE1AB_DIAG_DATA_EXT2 "ﾃﾞｰﾀ
";
CM_ SG_ 2564481451 SNR18DAE1AB_DIAG_DATA_EXT1 "ﾃﾞｰﾀ
";
CM_ SG_ 2564481451 SNR18DAE1AB_DIAG_DATA "ﾃﾞｰﾀ
";
CM_ SG_ 2564467681 CECU18DAABE1_DIAG_DATA_EXT7 "ﾃﾞｰﾀ
";
CM_ SG_ 2564467681 CECU18DAABE1_DIAG_DATA_EXT6 "ﾃﾞｰﾀ
";
CM_ SG_ 2564467681 CECU18DAABE1_DIAG_DATA_EXT5 "ﾃﾞｰﾀ
";
CM_ SG_ 2564467681 CECU18DAABE1_DIAG_DATA_EXT4 "ﾃﾞｰﾀ
";
CM_ SG_ 2564467681 CECU18DAABE1_DIAG_DATA_EXT3 "ﾃﾞｰﾀ
";
CM_ SG_ 2564467681 CECU18DAABE1_DIAG_DATA_EXT2 "ﾃﾞｰﾀ
";
CM_ SG_ 2564467681 CECU18DAABE1_DIAG_DATA_EXT1 "ﾃﾞｰﾀ
";
CM_ SG_ 2564467681 CECU18DAABE1_DIAG_DATA "ﾃﾞｰﾀ
";
CM_ SG_ 2564481469 RCR18DAE1BD_DIAG_DATA "ﾃﾞｰﾀ
";
CM_ SG_ 2564472289 CECU18DABDE1_DIAG_DATA "ﾃﾞｰﾀ
";
CM_ SG_ 2564481468 RCR18DAE1BC_DIAG_DATA "ﾃﾞｰﾀ
";
CM_ SG_ 2564472033 CECU18DABCE1_DIAG_DATA "ﾃﾞｰﾀ
";
CM_ SG_ 1774 CECU6EE_7_0_DESTINATION_INFO "仕向地情報
";
CM_ SG_ 1774 CECU6EE_7_4_VEHICLE_SERIES "車系情報
";
CM_ SG_ 1774 CECU6EE_6_0_DESTINATION_CODE "仕向地ｺｰﾄﾞ
";
CM_ SG_ 1774 CECU6EE_5_0_EYE_VERSION_INFO "ｱｲｻｲﾄVer情報
";
CM_ SG_ 1774 CECU6EE_5_4_VEHICLE_TYPE "車型情報
";
CM_ SG_ 1774 CECU6EE_5_6_PRODUCTION_BASE "生産拠点
";
CM_ SG_ 1774 CECU6EE_4_2_WHEEL_DRIVE_TYPE "駆動方式
";
CM_ SG_ 1774 CECU6EE_4_3_3RD_SHEAT_EQUIPMENT "3rdｼｰﾄ有無
";
CM_ SG_ 1774 CECU6EE_4_4_FLG_XMODE "Xﾓｰﾄﾞ有無
";
CM_ SG_ 1774 CECU6EE_4_6_ISS_EQUIPMENT "ISS有無
";
CM_ SG_ 1774 CECU6EE_4_7_TIRE_INFO "ﾀｲﾔ情報
";
CM_ SG_ 1774 CECU6EE_1_0_MSG_COUNTER "ﾒｯｾｰｼﾞｶｳﾝﾀ
";
CM_ SG_ 1774 CECU6EE_1_5_BEV_WHEEL_DRIVE_TYPE "駆動方式(BEV)
";
CM_ SG_ 1774 CECU6EE_0_0_CHECK_SUM "ﾁｪｯｸｻﾑ
";
CM_ SG_ 1773 CECU6ED_7_0_VEHICLE_TYPE_DETAIL "車型情報(詳細)
";
CM_ SG_ 1773 CECU6ED_5_0_TRANSMISSION_TYPE "ﾄﾗﾝｽﾐｯｼｮﾝ情報
";
CM_ SG_ 1773 CECU6ED_5_4_HANDLE "ﾊﾝﾄﾞﾙ情報
";
CM_ SG_ 1773 CECU6ED_4_0_VEHICLE_HEIGHT "車高情報
";
CM_ SG_ 1773 CECU6ED_4_4_SEATHEATER_EQUIPMENT "ｼｰﾄﾋｰﾀｰ有無
";
CM_ SG_ 1773 CECU6ED_3_0_YEAR_CHANGE "年改情報
";
CM_ SG_ 1773 CECU6ED_3_4_HEV_INFO "HEV情報
";
CM_ SG_ 1773 CECU6ED_1_0_MSG_COUNTER "ﾒｯｾｰｼﾞｶｳﾝﾀ
";
CM_ SG_ 1773 CECU6ED_0_0_CHECK_SUM "ﾁｪｯｸｻﾑ
";
CM_ SG_ 1772 CECU6EC_6_0_SMT_EQUIPMENT "SMT有無
";
CM_ SG_ 1772 CECU6EC_6_1_DCCD_EQUIPMENT "DCCD有無
";
CM_ SG_ 1772 CECU6EC_6_2_PRG_EQUIPMENT "PRG有無
";
CM_ SG_ 1772 CECU6EC_6_3_DKY_EQUIPMENT "DKY有無
";
CM_ SG_ 1772 CECU6EC_6_4_PSC_EQUIPMENT "PSC有無
";
CM_ SG_ 1772 CECU6EC_5_0_CCU_EQUIPMENT "CCU有無
";
CM_ SG_ 1772 CECU6EC_5_1_EAM_EQUIPMENT "EAM有無
";
CM_ SG_ 1772 CECU6EC_5_2_RCR_L_EQUIPMENT "RCR-L有無
";
CM_ SG_ 1772 CECU6EC_5_3_RCR_R_EQUIPMENT "RCR-R有無
";
CM_ SG_ 1772 CECU6EC_5_4_FCR_L_EQUIPMENT "FCR-L有無
";
CM_ SG_ 1772 CECU6EC_5_5_FCR_R_EQUIPMENT "FCR-R有無
";
CM_ SG_ 1772 CECU6EC_5_6_VSS_EQUIPMENT "VSS有無
";
CM_ SG_ 1772 CECU6EC_5_7_RES_EQUIPMENT "RES有無
";
CM_ SG_ 1772 CECU6EC_4_0_LCT_EQUIPMENT "LCT有無
";
CM_ SG_ 1772 CECU6EC_4_1_DAM_EQUIPMENT "DAM有無
";
CM_ SG_ 1772 CECU6EC_4_2_MVS_EQUIPMENT "MVS有無
";
CM_ SG_ 1772 CECU6EC_4_3_TCU_EQUIPMENT "TCU有無
";
CM_ SG_ 1772 CECU6EC_4_4_TPM_EQUIPMENT "TPM有無
";
CM_ SG_ 1772 CECU6EC_4_5_DCM_EQUIPMENT "DCM有無
";
CM_ SG_ 1772 CECU6EC_4_6_MED_EQUIPMENT "MED有無
";
CM_ SG_ 1772 CECU6EC_4_7_MEP_EQUIPMENT "MEP有無
";
CM_ SG_ 1772 CECU6EC_3_0_DATA_STATE "ﾃﾞｰﾀ状態
";
CM_ SG_ 1772 CECU6EC_3_1_EYE_EQUIPMENT "EYE有無
";
CM_ SG_ 1772 CECU6EC_3_2_HEV_EQUIPMENT "HEV有無
";
CM_ SG_ 1772 CECU6EC_3_3_SNR_EQUIPMENT "SNR有無
";
CM_ SG_ 1772 CECU6EC_3_4_EPB_EQUIPMENT "EPB有無
";
CM_ SG_ 1772 CECU6EC_3_5_DMS_EQUIPMENT "DMS有無
";
CM_ SG_ 1772 CECU6EC_3_6_BST_EQUIPMENT "BST有無
";
CM_ SG_ 1772 CECU6EC_3_7_MCA_EQUIPMENT "MCA有無
";
CM_ SG_ 1772 CECU6EC_1_0_MSG_COUNTER "ﾒｯｾｰｼﾞｶｳﾝﾀ
";
CM_ SG_ 1772 CECU6EC_0_0_CHECK_SUM "ﾁｪｯｸｻﾑ
";
CM_ SG_ 996 CECU3E4_7_0_SSM_COMM_INFO "SSM通信情報
";
CM_ SG_ 996 CECU3E4_6_0_CHARGE_LEVEL_ENG_RUN "エンジンRUN中充電レベル
";
CM_ SG_ 996 CECU3E4_6_4_CHARGE_LEVEL_IGN_ON "IG-ONエンスト中充電レベル
";
CM_ SG_ 996 CECU3E4_5_0_GENERATOR_OVER_FLG "発電機過大ﾌﾗｸﾞ
";
CM_ SG_ 996 CECU3E4_5_3_DIAG_COM_REQ "ﾃﾚﾏ診断通信要求
";
CM_ SG_ 996 CECU3E4_5_4_HEADS_UP_FLG "注意喚起ﾌﾗｸﾞ
";
CM_ SG_ 996 CECU3E4_3_0_WASH_CAR_MODE_STS "洗車モード状態
";
CM_ SG_ 996 CECU3E4_2_0_POW_ON_FIX_MODE_STS "電源ON固定モード状態
";
CM_ SG_ 996 CECU3E4_2_3_PET_MODE_STS "ペットモード状態
";
CM_ SG_ 996 CECU3E4_2_6_SHUT_DOWN_MODE_STS "シャットダウンモード遷移可否状態
";
CM_ SG_ 996 CECU3E4_2_7_OCCUPATION_CSTM "乗員検知設定値
";
CM_ SG_ 996 CECU3E4_1_0_MSG_COUNTER "ﾒｯｾｰｼﾞｶｳﾝﾀ
";
CM_ SG_ 996 CECU3E4_0_0_CHECK_SUM "ﾁｪｯｸｻﾑ
";
CM_ SG_ 1280 CGW500_1_4_ActiveWakeUpBit "Active Wakeup ﾌﾗｸﾞ
";
CM_ SG_ 1280 CGW500_0_0_SourceNodeID "送信元ID
";
CM_ SG_ 1633 CECU661_7_0_PRESENT_TIME_SEC "現在時刻(秒)
";
CM_ SG_ 1633 CECU661_6_0_PRESENT_TIME_MIN "現在時刻(分)
";
CM_ SG_ 1633 CECU661_5_0_PRESENT_TIME_HOUR "現在時刻(時)
";
CM_ SG_ 1633 CECU661_4_0_PRESENT_DAY "現在年月日(日)
";
CM_ SG_ 1633 CECU661_3_0_PRESENT_MONTH "現在年月日(月)
";
CM_ SG_ 1633 CECU661_2_0_PRESENT_YEAR "現在年月日(年)
";
CM_ SG_ 1632 CGW660_7_0_COUNT_TIME "時間ｶｳﾝﾀ
";
CM_ SG_ 1632 CGW660_3_0_COUNT_TRIP "Tripｶｳﾝﾀ
";
CM_ SG_ 1632 CGW660_1_0_SUB_ID "ｻﾌﾞID
";
CM_ SG_ 1752 DCM6D8_7_0_PRESENT_TIME_SEC "現在時刻情報(秒)
";
CM_ SG_ 1752 DCM6D8_6_0_PRESENT_TIME_MIN "現在時刻情報(分)
";
CM_ SG_ 1752 DCM6D8_5_0_PRESENT_TIME_HOUR "現在時刻情報(時)
";
CM_ SG_ 1752 DCM6D8_4_0_PRESENT_DAY "現在時刻情報(日)
";
CM_ SG_ 1752 DCM6D8_3_0_PRESENT_MONTH "現在時刻情報(月)
";
CM_ SG_ 1752 DCM6D8_2_0_DATA_COLLECT_INTERVAL "データ収集間隔設定
";
CM_ SG_ 1752 DCM6D8_1_0_MSG_COUNTER "ﾒｯｾｰｼﾞｶｳﾝﾀ
";
CM_ SG_ 1752 DCM6D8_1_4_PRESS_SOS_BUTTON "SOSﾎﾞﾀﾝ押下
";
CM_ SG_ 1752 DCM6D8_0_0_CHECK_SUM "ﾁｪｯｸｻﾑ
";
CM_ SG_ 1744 CECU6D0_4_0_OTA_ABORT "OTA中止
";
CM_ SG_ 1744 CECU6D0_4_1_OTA_SUSPEND "OTA中断
";
CM_ SG_ 1744 CECU6D0_4_2_OTA_SEQUENCE "OTA実行シーケンス
";
CM_ SG_ 1744 CECU6D0_1_0_MSG_COUNTER "ﾒｯｾｰｼﾞｶｳﾝﾀ
";
CM_ SG_ 1744 CECU6D0_1_4_OTA_STATUS_UPDATE "OTAステータス アップデート実行中
";
CM_ SG_ 1744 CECU6D0_0_0_CHECK_SUM "ﾁｪｯｸｻﾑ
";
CM_ SG_ 1749 CECU6D5_6_0_CSTM_FMHD "ウェルカムランプ(降車)
";
CM_ SG_ 1749 CECU6D5_5_0_CSTM_WRH "ワイパ連動オートライト機能ON/OFF設定
";
CM_ SG_ 1749 CECU6D5_5_1_CSTM_LMHD "ウェルカムランプ(乗車)
";
CM_ SG_ 1749 CECU6D5_5_3 "北米ウェルカムランプ(リービング)（カスタマイズ）
";
CM_ SG_ 1749 CECU6D5_5_5_CSTM_HBA "HBA 有無設定
";
CM_ SG_ 1749 CECU6D5_5_7_ADB_ACTIVE "ADB有無設定
";
CM_ SG_ 1749 CECU6D5_4_0_JUDGE_ILL "照度判定
";
CM_ SG_ 1749 CECU6D5_4_1_HEADLAMP_AUTO_SW "ライティングAUTO SW 出力信号
";
CM_ SG_ 1749 CECU6D5_4_2_IND_ACTIVE_HBA "HBA 作動灯
";
CM_ SG_ 1749 CECU6D5_4_4_FGT_LGTOFF_WARNING "ライト消し忘れ警報
";
CM_ SG_ 1749 CECU6D5_3_0_CRN_R_REQ "コーナリングランプR 出力要求
";
CM_ SG_ 1749 CECU6D5_3_2_CRN_L_REQ "コーナリングランプL 出力要求
";
CM_ SG_ 1749 CECU6D5_3_4_FMH "フォローミーホーム出力情報
";
CM_ SG_ 1749 CECU6D5_3_5_LMH "リードミーホーム出力情報
";
CM_ SG_ 1749 CECU6D5_2_0_LGT_1 "ライティング1 リレー出力要求
";
CM_ SG_ 1749 CECU6D5_2_1_LGT_LO "ライティングLo リレー出力要求
";
CM_ SG_ 1749 CECU6D5_2_2_LGT_HI "ライティングHi リレー出力要求
";
CM_ SG_ 1749 CECU6D5_2_4_FFOG_RELAY_REQ "Fフォグランプリレー出力要求
";
CM_ SG_ 1749 CECU6D5_2_5_RFOG_RELAY_REQ "Rフォグランプリレー出力要求
";
CM_ SG_ 1749 CECU6D5_2_6_LGT_DRL "DRL リレー出力要求
";
CM_ SG_ 1749 CECU6D5_1_0_MSG_COUNTER "ﾒｯｾｰｼﾞｶｳﾝﾀ
";
CM_ SG_ 1749 CECU6D5_0_0_CHECK_SUM "ﾁｪｯｸｻﾑ
";
CM_ SG_ 1107 DCM453_31_0_BYTE29 "開発用変数29
";
CM_ SG_ 1107 DCM453_30_0_BYTE28 "開発用変数28
";
CM_ SG_ 1107 DCM453_29_0_BYTE27 "開発用変数27
";
CM_ SG_ 1107 DCM453_28_0_BYTE26 "開発用変数26
";
CM_ SG_ 1107 DCM453_27_0_BYTE25 "開発用変数25
";
CM_ SG_ 1107 DCM453_26_0_BYTE24 "開発用変数24
";
CM_ SG_ 1107 DCM453_25_0_BYTE23 "開発用変数23
";
CM_ SG_ 1107 DCM453_24_0_BYTE22 "開発用変数22
";
CM_ SG_ 1107 DCM453_23_0_BYTE21 "開発用変数21
";
CM_ SG_ 1107 DCM453_22_0_BYTE20 "開発用変数20
";
CM_ SG_ 1107 DCM453_21_0_BYTE19 "開発用変数19
";
CM_ SG_ 1107 DCM453_20_0_BYTE18 "開発用変数18
";
CM_ SG_ 1107 DCM453_19_0_BYTE17 "開発用変数17
";
CM_ SG_ 1107 DCM453_18_0_BYTE16 "開発用変数16
";
CM_ SG_ 1107 DCM453_17_0_BYTE15 "開発用変数15
";
CM_ SG_ 1107 DCM453_16_0_BYTE14 "開発用変数14
";
CM_ SG_ 1107 DCM453_15_0_BYTE13 "開発用変数13
";
CM_ SG_ 1107 DCM453_14_0_BYTE12 "開発用変数12
";
CM_ SG_ 1107 DCM453_13_0_BYTE11 "開発用変数11
";
CM_ SG_ 1107 DCM453_12_0_BYTE10 "開発用変数10
";
CM_ SG_ 1107 DCM453_11_0_BYTE9 "開発用変数9
";
CM_ SG_ 1107 DCM453_10_0_BYTE8 "開発用変数8
";
CM_ SG_ 1107 DCM453_9_0_BYTE7 "開発用変数7
";
CM_ SG_ 1107 DCM453_8_0_BYTE6 "開発用変数6
";
CM_ SG_ 1107 DCM453_7_0_BYTE5 "開発用変数5
";
CM_ SG_ 1107 DCM453_6_0_BYTE4 "開発用変数4
";
CM_ SG_ 1107 DCM453_5_0_BYTE3 "開発用変数3
";
CM_ SG_ 1107 DCM453_4_0_BYTE2 "開発用変数2
";
CM_ SG_ 1107 DCM453_3_0_BYTE1 "開発用変数1
";
CM_ SG_ 1107 DCM453_2_0_E2E_COUNTER "E2Eカウンタ
";
CM_ SG_ 1107 DCM453_0_0_E2E_CRC "CRC
";
CM_ SG_ 1705 MVS6A9_6_0_CSTM_HITCHLINE_DSPREQ "ヒッチボールガイド線カスタマイズ表示要求
";
CM_ SG_ 1705 MVS6A9_6_2_CSTM_HITCHLINE "ヒッチボールガイド線ON/OFF情報
";
CM_ SG_ 1705 MVS6A9_5_0_RR_WIDE_VIEW_SW_STATE "リアワイドビューSW表示状態
";
CM_ SG_ 1705 MVS6A9_5_2_RR_NRW_VIEW_SW_STATE "リアナロービューSW表示状態
";
CM_ SG_ 1705 MVS6A9_5_4_HITCH_VIEW_SW_STATE "ヒッチボールビューSW表示状態
";
CM_ SG_ 1705 MVS6A9_4_0_FT_NRW_VIEW_SW_STATE "フロントナロービューSW表示状態
";
CM_ SG_ 1705 MVS6A9_4_2_FT_WIDE_VIEW_SW_STATE "フロントワイドビューSW表示状態
";
CM_ SG_ 1705 MVS6A9_4_4_SIDE_VIEW_SW_STATE "サイドビューSW表示状態
";
CM_ SG_ 1705 MVS6A9_4_6_3D_VIEW_SW_STATE "３DビューSW表示状態
";
CM_ SG_ 1705 MVS6A9_3_0_CSTM_AUTO_DISPLAY_SET "自動表示カスタマイズ機能有無
";
CM_ SG_ 1705 MVS6A9_3_1_CSTM_AUTO_DISPLAY "自動表示カスタマイズ設定
";
CM_ SG_ 1705 MVS6A9_3_2_VIEW_MODE "カメラ画面表示モード
";
CM_ SG_ 1705 MVS6A9_3_5_STOP_SWITCH "カメラ表示停止スイッチ操作可否
";
CM_ SG_ 1705 MVS6A9_3_6_CSTM_HITCH_VIEW "ヒッチボールビュー有無
";
CM_ SG_ 1705 MVS6A9_2_0_CURRENT_VIEW "映像出力情報
";
CM_ SG_ 1705 MVS6A9_2_5_HOLD_TIME "カメラ表示待ち時間(4カメラ用)
";
CM_ SG_ 1705 MVS6A9_1_0_MSG_COUNTER "ﾒｯｾｰｼﾞｶｳﾝﾀ
";
CM_ SG_ 1705 MVS6A9_1_4_FAIL_MVS "MVSﾌｪｰﾙﾌﾗｸﾞ
";
CM_ SG_ 1705 MVS6A9_1_5_FAIL_MVS_CAUSE "MVSﾌｪｰﾙ通知(FCTI向け)
";
CM_ SG_ 1705 MVS6A9_0_0_CHECK_SUM "ﾁｪｯｸｻﾑ
";
CM_ SG_ 1364 MVS554_7_0_NETWORK_STATUS "ﾈｯﾄﾜｰｸｽﾃｰﾀｽ
";
CM_ SG_ 930 MET3A2_7_0_FUEL_AMOUNT "残燃料表示
";
CM_ SG_ 930 MET3A2_6_0_SEATBELT_RR_RH "ｼｰﾄﾍﾞﾙﾄﾊﾞｯｸﾙSW　後席右
";
CM_ SG_ 930 MET3A2_6_1_SEATBELT_RR_CTR "ｼｰﾄﾍﾞﾙﾄﾊﾞｯｸﾙSW　後席中央
";
CM_ SG_ 930 MET3A2_6_2_SEATBELT_RR_LH "ｼｰﾄﾍﾞﾙﾄﾊﾞｯｸﾙSW　後席左
";
CM_ SG_ 930 MET3A2_6_3_SEATBELT_THIRD_RH "ｼｰﾄﾍﾞﾙﾄﾊﾞｯｸﾙSW　3rd後席右
";
CM_ SG_ 930 MET3A2_6_4_SEATBELT_THIRD_CTR "ｼｰﾄﾍﾞﾙﾄﾊﾞｯｸﾙSW　3rd後席中央
";
CM_ SG_ 930 MET3A2_6_5_SEATBELT_THIRD_LH "ｼｰﾄﾍﾞﾙﾄﾊﾞｯｸﾙSW　3rd後席左
";
CM_ SG_ 930 MET3A2_5_0_FLG_RR_REMINDER "幼児置き去り警報実施フラグ
";
CM_ SG_ 930 MET3A2_2_0_ODO_DETAIL "オドﾒｰﾀ値
";
CM_ SG_ 930 MET3A2_1_0_MSG_COUNTER "ﾒｯｾｰｼﾞｶｳﾝﾀ
";
CM_ SG_ 930 MET3A2_1_4_FAIL_DISP "MET表示フェールフラグ
";
CM_ SG_ 930 MET3A2_0_0_CHECK_SUM "ﾁｪｯｸｻﾑ
";
CM_ SG_ 1677 MET68D_7_0_STATUS_WASHER_LAMP "ｳｫｯｼｬ残量警告灯状態
";
CM_ SG_ 1677 MET68D_7_1_OILPRESSURE_SW "ｵｲﾙﾌﾟﾚｯｼｬSW状態
";
CM_ SG_ 1677 MET68D_7_2_FLG_EAM "EAM車両装備情報
";
CM_ SG_ 1677 MET68D_7_3_CSTM_IND_RED "ｱｲｻｲﾄﾓﾆﾀｰ変更設定赤色ｲﾝｼﾞｹｰﾀ
";
CM_ SG_ 1677 MET68D_7_4_CSTM_IND_YELLOW "ｱｲｻｲﾄﾓﾆﾀｰ変更設定黄色ｲﾝｼﾞｹｰﾀ
";
CM_ SG_ 1677 MET68D_7_5_CSTM_IND_GREEN "ｱｲｻｲﾄﾓﾆﾀｰ変更設定緑色ｲﾝｼﾞｹｰﾀ
";
CM_ SG_ 1677 MET68D_7_6_REQ_CSTM_SRH "SRHｶｽﾀﾏｲｽﾞ変更要求
";
CM_ SG_ 1677 MET68D_7_7_CSTM_SRH "SRHｶｽﾀﾏｲｽﾞ変更設定
";
CM_ SG_ 1677 MET68D_6_5_REQ_CHG_CSTM_RAB "RABｶｽﾀﾏｲｽﾞ要求変更
";
CM_ SG_ 1677 MET68D_6_6_CSTM_RAB "ｿﾅｰｶｽﾀﾏｲｽﾞ変更設定(RABON/OFF)
";
CM_ SG_ 1677 MET68D_6_7_CSTM_SONNER "ｿﾅｰｶｽﾀﾏｲｽﾞ変更設定(ｿﾅｰON/OFF)
";
CM_ SG_ 1677 MET68D_5_0_TEMP_FOR_PPA "歩行者保護A/B用温度
";
CM_ SG_ 1677 MET68D_2_0_ODO "ｵﾄﾞﾒｰﾀ値
";
CM_ SG_ 1677 MET68D_1_0_MSG_COUNTER "ﾒｯｾｰｼﾞｶｳﾝﾀ
";
CM_ SG_ 1677 MET68D_1_4_RESET_CSTM_TPMS_RAEB "ｶｽﾀﾏｲｽﾞﾘｾｯﾄ要求(TPMS/RAEB)
";
CM_ SG_ 1677 MET68D_1_5_REQ_CHG_CSTM_TPMS "TPMSｶｽﾀﾏｲｽﾞ要求変更
";
CM_ SG_ 1677 MET68D_1_6_CSTM_TIRE_UNIT "ﾀｲﾔ空気圧表示単位設定
";
CM_ SG_ 1677 MET68D_0_0_CHECK_SUM "ﾁｪｯｸｻﾑ
";
CM_ SG_ 1676 MET68C_7_0_CSTM_OUTTEMP "外気温ｶｽﾀﾏｲｽﾞ設定値
";
CM_ SG_ 1676 MET68C_4_6_UNIT_DEGREE "外気温単位設定値
";
CM_ SG_ 1676 MET68C_3_0_MET_SW_STATE "ﾒｰﾀSW操作状態ﾌﾗｸﾞ
";
CM_ SG_ 1676 MET68C_3_3_PERMIT_MFD_CSTM "MFDｶｽﾀﾏｲｽﾞ許可ﾌﾗｸﾞ
";
CM_ SG_ 1676 MET68C_3_5_FLG_RR_AC_PANEL "リアﾋｰｺﾝﾊﾟﾈﾙ装備
";
CM_ SG_ 1676 MET68C_3_6_FLG_SEAT_VENT "シート空調装備情報
";
CM_ SG_ 1676 MET68C_3_7_FLG_SEAT_HEAT "ｼｰﾄﾋｰﾀ装備情報
";
CM_ SG_ 1676 MET68C_2_0_CRUISING_RADIUS "航続可能距離表示値
";
CM_ SG_ 1676 MET68C_1_0_MSG_COUNTER "ﾒｯｾｰｼﾞｶｳﾝﾀ
";
CM_ SG_ 1676 MET68C_1_4_CSTM_HU "HU有無ﾌﾗｸﾞ
";
CM_ SG_ 1676 MET68C_1_5_CSTM_BRAND_NAME "ブランドフラグ
";
CM_ SG_ 1676 MET68C_0_0_CHECK_SUM "ﾁｪｯｸｻﾑ
";
CM_ SG_ 922 MET39A_7_0_SET_LANGUAGE "各国言語設定
";
CM_ SG_ 922 MET39A_7_5_ACTIVE_MET_CSTM "車両ｶｽﾀﾏｲｽﾞ実施状態ﾌﾗｸﾞ（ﾒｰﾀ）
";
CM_ SG_ 922 MET39A_7_6_MFD_SPEC "MFD判別ﾌﾗｸﾞ
";
CM_ SG_ 922 MET39A_7_7_ICY_ROAD_SURFACE "路面凍結警報状態
";
CM_ SG_ 922 MET39A_6_4_STATUS_TRIP_A_B "TRIP表示状態(A or B)
";
CM_ SG_ 922 MET39A_5_2_AVE_FUEL_ECONOMY "平均燃費
";
CM_ SG_ 922 MET39A_4_0_INSTANTANEOUS_FUEL "瞬間燃費
";
CM_ SG_ 922 MET39A_3_1_STATUS_FUEL_LAMP "燃料残量警告灯状態
";
CM_ SG_ 922 MET39A_3_3_TRANSIT_TIME "運転経過時間
";
CM_ SG_ 922 MET39A_2_0_AVE_VEHICLE_SPEED "平均車速表示
";
CM_ SG_ 922 MET39A_1_0_MSG_COUNTER "ﾒｯｾｰｼﾞｶｳﾝﾀ
";
CM_ SG_ 922 MET39A_1_4_SET_UNIT_OF_FUEL "燃費単位設定
";
CM_ SG_ 922 MET39A_1_6_WELCOME_TRIG "ｳｪﾙｶﾑ演出開始ﾄﾘｶﾞ
";
CM_ SG_ 922 MET39A_1_7_METER_DISPLAY_TYPE "ﾒｰﾀ液晶ﾀｲﾌﾟ
";
CM_ SG_ 922 MET39A_0_0_CHECK_SUM "ﾁｪｯｸｻﾑ
";
CM_ SG_ 915 MET393_7_0_REQ_CHG_CSTM_EYE "ｱｲｻｲﾄｶｽﾀﾏｲｽﾞ要求変更
";
CM_ SG_ 915 MET393_7_1_REQ_RESET_CSTM_EYE "ｱｲｻｲﾄｶｽﾀﾏｲｽﾞﾘｾｯﾄ要求
";
CM_ SG_ 915 MET393_7_2_CSTM_ALK "ｱｲｻｲﾄｶｽﾀﾏｲｽﾞ変更設定(車線中央維持)
";
CM_ SG_ 915 MET393_7_3_CSTM_HBA "ｱｲｻｲﾄｶｽﾀﾏｲｽﾞ変更設定値(HBA)
";
CM_ SG_ 915 MET393_7_4_CSTM_MIS_AT_BACK "ｱｲｻｲﾄｶｽﾀﾏｲｽﾞ変更設定(AT誤後進抑制制御)
";
CM_ SG_ 915 MET393_7_6_CSTM_ACC_CONT "ｱｲｻｲﾄｶｽﾀﾏｲｽﾞ変更設定(ACC加速特性)
";
CM_ SG_ 915 MET393_6_0_R_DIFF_TEMP "R.DIFF油温ｾﾝｻ
";
CM_ SG_ 915 MET393_5_2_WARN_R_DIFF_TEMP "R.DIFF油温警告灯
";
CM_ SG_ 915 MET393_5_4_ADAPTIVECC_NOALIVE "追従ｸﾙｺﾝ未着判定ﾌﾗｸﾞ
";
CM_ SG_ 915 MET393_5_5_DUAL_RANGE_LO "ﾃﾞｭｱﾙﾚﾝｼﾞLo
";
CM_ SG_ 915 MET393_5_6_CSTM_SPD_LIMITER "ｱｲｻｲﾄｶｽﾀﾏｲｽﾞ変更設定(SAS)
";
CM_ SG_ 915 MET393_5_7_CSTM_LANE_CONT "ｱｲｻｲﾄｶｽﾀﾏｲｽﾞ変更設定(通行車線)
";
CM_ SG_ 915 MET393_4_0_FUEL_LEVEL_RESIST "燃料ﾚﾍﾞﾙｾﾝｻ抵抗値
";
CM_ SG_ 915 MET393_3_5_SI_DRIVE_SW "SI-DRIVE SW情報
";
CM_ SG_ 915 MET393_2_0_OUTTEMP_FOR_DIAG "診断用外気温
";
CM_ SG_ 915 MET393_1_0_MSG_COUNTER "ﾒｯｾｰｼﾞｶｳﾝﾀ
";
CM_ SG_ 915 MET393_1_4_CSTM_IND_BLUE "ｱｲｻｲﾄﾓﾆﾀｰ変更設定青色ｲﾝｼﾞｹｰﾀ
";
CM_ SG_ 915 MET393_1_5_CSTM_AES_CONT "ｱｲｻｲﾄｶｽﾀﾏｲｽﾞ変更設定(AES)
";
CM_ SG_ 915 MET393_1_6_FLG_PEDESTRIAN_AIRBAG "歩行者保護A/B有無ﾌﾗｸﾞ
";
CM_ SG_ 915 MET393_0_0_CHECK_SUM "ﾁｪｯｸｻﾑ
";
CM_ SG_ 912 MET390_7_0_VDC_ON_OFF "VDC SW情報
";
CM_ SG_ 912 MET390_7_2_RR_DOOR_RECORD_L "後席ﾄﾞｱ開履歴送信（左）
";
CM_ SG_ 912 MET390_7_3_RR_DOOR_RECORD_R "後席ﾄﾞｱ開履歴送信（右）
";
CM_ SG_ 912 MET390_7_4_REQ_CHG_CSTM_PSM "PSMｶｽﾀﾏｲｽﾞ要求変更
";
CM_ SG_ 912 MET390_7_5_REQ_RESET_CSTM_PSM "PSM　ｶｽﾀﾏｲｽﾞﾘｾｯﾄ要求
";
CM_ SG_ 912 MET390_7_6_CSTM_MIR_AFOLD_CONT "ﾄﾞｱﾐﾗｰｶｽﾀﾏｲｽﾞ変更設定(ｵｰﾄ電動格納ﾐﾗｰ)
";
CM_ SG_ 912 MET390_7_7_CSTM_MIR_RTILT_CONT "ﾄﾞｱﾐﾗｰｶｽﾀﾏｲｽﾞ変更設定(ﾘﾊﾞｰｽ連動ﾐﾗｰ)
";
CM_ SG_ 912 MET390_6_0_SEATBELT_DRVR "ｼｰﾄﾍﾞﾙﾄﾊﾞｯｸﾙSW　D席
";
CM_ SG_ 912 MET390_6_1_SEATBELT_PASS "ｼｰﾄﾍﾞﾙﾄﾊﾞｯｸﾙSW　P席
";
CM_ SG_ 912 MET390_6_2_TURN_SIG_LEFT "ﾀｰﾝ左出力信号
";
CM_ SG_ 912 MET390_6_3_TURN_SIG_RIGHT "ﾀｰﾝ右出力信号
";
CM_ SG_ 912 MET390_6_4_BRIGHT_SW "ﾌﾞﾗｲﾄ信号
";
CM_ SG_ 912 MET390_6_5_FAIL_UART_WA_BOX "WA-BOX UART通信異常
";
CM_ SG_ 912 MET390_6_6_ISS_OFF_SW "ISS OFFｽｲｯﾁ状態
";
CM_ SG_ 912 MET390_6_7_FLG_DMS "DMS車両装備情報
";
CM_ SG_ 912 MET390_5_0_ILL_BRIGHTNESS "ｲﾙﾐ輝度値
";
CM_ SG_ 912 MET390_4_0_OUTTEMP_FOR_IND "表示用外気温
";
CM_ SG_ 912 MET390_3_0_UNIT_SPEED_TRIP "速度計/距離計表示単位
";
CM_ SG_ 912 MET390_3_1_FLG_EYESIGHT "EyeSightﾌﾗｸﾞ
";
CM_ SG_ 912 MET390_3_2_FLG_ISS "ISSﾌﾗｸﾞ
";
CM_ SG_ 912 MET390_3_3_FLG_HEV "HEVﾌﾗｸﾞ
";
CM_ SG_ 912 MET390_3_4_FLG_IMB "IMﾌﾗｸﾞ
";
CM_ SG_ 912 MET390_3_5_TIRE_SIZE "ﾀｲﾔ径情報
";
CM_ SG_ 912 MET390_3_6_FLG_XMODE "Xモード車両装備情報
";
CM_ SG_ 912 MET390_2_0_VEHICLE_SERIES "車型情報
";
CM_ SG_ 912 MET390_2_3_DESTINATION "仕向地情報
";
CM_ SG_ 912 MET390_2_7_PASS_DOOR_RECORD "助手席ﾄﾞｱ開履歴送信
";
CM_ SG_ 912 MET390_1_0_MSG_COUNTER "ﾒｯｾｰｼﾞｶｳﾝﾀ
";
CM_ SG_ 912 MET390_1_4_WAKE_UP_FRAME "ｳｪｲｸｱｯﾌﾟﾌﾚｰﾑ識別ﾌﾗｸﾞ
";
CM_ SG_ 912 MET390_1_5_REQ_COMM_CONT "通信継続要求ﾌﾗｸﾞ
";
CM_ SG_ 912 MET390_1_6_DMS_ID_SET "DMS ID設定完了ﾌﾗｸﾞ
";
CM_ SG_ 912 MET390_1_7_FAIL_EEPROM "EEPROMﾌｪｰﾙ
";
CM_ SG_ 912 MET390_0_0_CHECK_SUM "ﾁｪｯｸｻﾑ
";
CM_ SG_ 1291 MET50B_1_4_ActiveWakeUpBit "Active Wakeup ﾌﾗｸﾞ
";
CM_ SG_ 1291 MET50B_0_0_SourceNodeID "送信元ID
";
CM_ SG_ 914 MET392_23_0_ADD_ACNON_DRVRANG "充電後追加航続可能距離(ACN-ON)
";
CM_ SG_ 914 MET392_21_0_ADD_ACNOFF_DRVRANG "充電後追加航続可能距離(ACN-OFF)
";
CM_ SG_ 914 MET392_18_0_TRIP_LASTCHG_TOTM "TRIP LastCharge積算時間(min)
";
CM_ SG_ 914 MET392_15_0_TRIPB_TOTAL_TIME "TRIP B積算時間(min)
";
CM_ SG_ 914 MET392_12_0_TRIPA_TOTAL_TIME "TRIP A積算時間(min)
";
CM_ SG_ 914 MET392_9_0_TRIP_LASTCHARGE_KM "TRIP LastCharge(km固定)
";
CM_ SG_ 914 MET392_8_2_TRIPB_RESET "TRIP Bﾘｾｯﾄ完了通知
";
CM_ SG_ 914 MET392_6_0_TRIPB_KM "TRIP B(km固定)
";
CM_ SG_ 914 MET392_5_2_TRIPA_RESET "TRIP Aﾘｾｯﾄ完了通知
";
CM_ SG_ 914 MET392_3_0_TRIPA_KM "TRIP A(km固定)
";
CM_ SG_ 914 MET392_2_0_E2E_COUNTER "E2Eｶｳﾝﾀ
";
CM_ SG_ 914 MET392_0_0_CRC "CRC
";
CM_ SG_ 937 MET3A9_3_5_DAY_NIGHT_STATE "昼夜状態
";
CM_ SG_ 937 MET3A9_3_0_ILL_LEVEL "ｲﾙﾐ段数
";
CM_ SG_ 937 MET3A9_2_0_ILL_VALUE "ｲﾙﾐ輝度値
";
CM_ SG_ 937 MET3A9_1_7_BRIGHT_STATE "ﾌﾞﾗｲﾄ状態
";
CM_ SG_ 937 MET3A9_1_6_UI_THEME_STATE "UI Theme状態
";
CM_ SG_ 937 MET3A9_1_0_MSG_COUNTER "ﾒｯｾｰｼﾞｶｳﾝﾀ
";
CM_ SG_ 937 MET3A9_0_0_CHECKSUM "ﾁｪｯｸｻﾑ
";
CM_ SG_ 933 MET3A5_7_0_INSTCNSP_VAL "瞬間燃費
";
CM_ SG_ 933 MET3A5_5_0_AVEN_TRIPB_VAL "平均燃費(TRIP B)
";
CM_ SG_ 933 MET3A5_3_0_AVEN_TRIPA_VAL "平均燃費(TRIP A)
";
CM_ SG_ 933 MET3A5_2_0_E2E_COUNTER "E2Eｶｳﾝﾀ
";
CM_ SG_ 933 MET3A5_0_0_CRC "CRC
";
CM_ SG_ 1679 MET68F_3_0_DOWNSW_STS "DOWN SW
";
CM_ SG_ 1679 MET68F_3_1_UPSW_STS "UP SW
";
CM_ SG_ 1679 MET68F_3_2_ISETSW_STS "i/SET SW
";
CM_ SG_ 1679 MET68F_3_3_MUD_SAND_SW_STS "MUD SAND SW_STS
";
CM_ SG_ 1679 MET68F_3_4_SNOW_DIRT_SW_STS "SNOW DIRT SW
";
CM_ SG_ 1679 MET68F_3_5_WIDGET_SW_STS "WIDGET SW
";
CM_ SG_ 1679 MET68F_3_6_OK_SW_STS "OK SW
";
CM_ SG_ 1679 MET68F_2_0_SIDRVSW_STS "SI-Drive/SI-DS SW
";
CM_ SG_ 1679 MET68F_1_0_MSG_COUNTER "ﾒｯｾｰｼﾞｶｳﾝﾀ
";
CM_ SG_ 1679 MET68F_0_0_CHECK_SUM "ﾁｪｯｸｻﾑ
";
CM_ SG_ 1678 MET68E_7_0_EGO_CAR_DISP_COLOR "自車表示色
";
CM_ SG_ 1678 MET68E_6_0_REDZONE_REV "REDZONE回転数
";
CM_ SG_ 1678 MET68E_5_0_CSTM_REV_SET "ﾕｰｻﾞ設定回転数
";
CM_ SG_ 1678 MET68E_4_0_CSTM_ALERT_VOL_VAL "警報音量状態値
";
CM_ SG_ 1678 MET68E_4_2_CSTM_SHIFT "ｼﾌﾄ表示設定状態値
";
CM_ SG_ 1678 MET68E_4_3_CSTM_WOW "初期演出設定状態値
";
CM_ SG_ 1678 MET68E_4_4_CSTM_GBYE "GoodBye設定状態値
";
CM_ SG_ 1678 MET68E_4_6_CSTM_WLCM "Welcome設定状態値
";
CM_ SG_ 1678 MET68E_3_0_CSTM_TEMP_UNIT "外気温単位設定値
";
CM_ SG_ 1678 MET68E_3_1_CSTM_REAR_REMIND "後席ﾘﾏｲﾝﾀﾞ 設定値
";
CM_ SG_ 1678 MET68E_3_2_SET_UNIT_OF_ELEC "MET単位 設定値(BEV)
";
CM_ SG_ 1678 MET68E_3_5_CSTM_ES_STARTBZ "先行車発進お知らせ 現在設定値
";
CM_ SG_ 1678 MET68E_3_7_CSTM_ES_CATCHBZ "先行車捕捉音 現在設定値
";
CM_ SG_ 1678 MET68E_2_0_CSTM_METUNIT "MET単位 設定値
";
CM_ SG_ 1678 MET68E_1_0_MSG_COUNTER "ﾒｯｾｰｼﾞｶｳﾝﾀ
";
CM_ SG_ 1678 MET68E_0_0_CHECK_SUM "ﾁｪｯｸｻﾑ
";
CM_ SG_ 1674 MET68A_31_0_METBZ_STS_CH0 "METブザーCH0吹鳴情報
";
CM_ SG_ 1674 MET68A_31_1_METBZ_STS_CH1 "METブザーCH1吹鳴情報
";
CM_ SG_ 1674 MET68A_31_2_METBZ_WARN_CH0 "METブザーCH0警告パターン情報
";
CM_ SG_ 1674 MET68A_31_3_METBZ_PTN_CH0 "METブザーCH0吹鳴パターン情報
";
CM_ SG_ 1674 MET68A_31_4_METBZ_WARN_CH1 "METブザーCH1警告パターン情報
";
CM_ SG_ 1674 MET68A_31_5_METBZ_PTN_CH1 "METブザーCH1吹鳴パターン情報
";
CM_ SG_ 1674 MET68A_31_6_VOL_ATN_REQ "音量ｱｯﾃﾈｰﾄ要求
";
CM_ SG_ 1674 MET68A_30_0_METBZ_KIND_CH1 "ﾌﾞｻﾞｰ種別(CH1)
";
CM_ SG_ 1674 MET68A_29_0_METBZ_KIND_CH0 "ﾌﾞｻﾞｰ種別(CH0)
";
CM_ SG_ 1674 MET68A_26_0_TRIPB_VAL "TRIP B(km or miles)
";
CM_ SG_ 1674 MET68A_23_0_TRIPA_VAL "TRIP A(km or miles)
";
CM_ SG_ 1674 MET68A_22_6_VOL_MUTE_REQ "音量ﾐｭｰﾄ要求
";
CM_ SG_ 1674 MET68A_21_0_IGNONDIST_VAL "区間距離
";
CM_ SG_ 1674 MET68A_20_1_IGNONTM_MIN_VAL "区間時間(分)
";
CM_ SG_ 1674 MET68A_19_0_AVSP_TRIPB_VAL "平均車速(Trip B)
";
CM_ SG_ 1674 MET68A_18_1_IGNONTM_HOUR_VAL "区間時間(時)
";
CM_ SG_ 1674 MET68A_17_0_AVSP_TRIPA_VAL "平均車速(Trip A)
";
CM_ SG_ 1674 MET68A_16_0_TRIP_DISP_TYPE "TRIPｴﾘｱ表示ｺﾝﾃﾝﾂ
";
CM_ SG_ 1674 MET68A_13_0_TRIP_VAL "TRIP(km or mile)
";
CM_ SG_ 1674 MET68A_12_0_TEMPBAR_PER "水温計表示割合
";
CM_ SG_ 1674 MET68A_11_0_FUELBAR_PER "FUEL計表示割合
";
CM_ SG_ 1674 MET68A_9_0_TACHOREV_VAL "ﾀｺ回転数
";
CM_ SG_ 1674 MET68A_7_0_SPD_COR_VAL "車速補正値（指示規格）
";
CM_ SG_ 1674 MET68A_6_1_CID_TONE_DOWN "CIDﾄｰﾝﾀﾞｳﾝ
";
CM_ SG_ 1674 MET68A_6_6_SI_FAIL_FLAG "SIﾌｪｰﾙﾌﾗｸﾞ
";
CM_ SG_ 1674 MET68A_5_0_DMSPD_SUB_VAL "現在車速ｻﾌﾞ(ﾃﾞｼﾞﾀﾙ車速)予備領域
";
CM_ SG_ 1674 MET68A_4_1_ILM_AIDM "昼夜情報
";
CM_ SG_ 1674 MET68A_4_2_TEMP_ICON "水温ｱｲｺﾝ状態
";
CM_ SG_ 1674 MET68A_4_5_SIDRIVE_MET_DISP "SI-DRIVE MET表示情報
";
CM_ SG_ 1674 MET68A_3_0_DMSPD_VAL "現在車速(ﾃﾞｼﾞﾀﾙ車速)
";
CM_ SG_ 1674 MET68A_2_0_E2E_COUNTER "E2Eｶｳﾝﾀ
";
CM_ SG_ 1674 MET68A_0_0_CRC "CRC
";
CM_ SG_ 1673 MET689_20_0_VOICE_GUIDE_SUP "音声ｶﾞｲﾀﾞﾝｽ有無
";
CM_ SG_ 1673 MET689_19_0_SPORT_CONT "ｽﾎﾟｰﾂｺﾝﾃﾝﾂ有無
";
CM_ SG_ 1673 MET689_18_0_STI_SUP "STI有無STI表示方式
";
CM_ SG_ 1673 MET689_17_0_REARVIEW "ｽﾏｰﾄﾘｱﾋﾞｭｰﾐﾗｰ有無
";
CM_ SG_ 1673 MET689_16_0_GSR_ELKS_SUP "GSR-ELKS機能有無
";
CM_ SG_ 1673 MET689_16_1_GSR_AEBS_SUP "GSR-AEBS機能有無
";
CM_ SG_ 1673 MET689_16_2_GSR_DDAW_SUP "GSR-DDAW機能有無
";
CM_ SG_ 1673 MET689_16_3_GSR_ISA_SUP "GSR-ISA機能有無
";
CM_ SG_ 1673 MET689_16_4_IACC_SUP "iACC機能有無
";
CM_ SG_ 1673 MET689_16_5_REAR_PANEL_SUP "ﾘｱﾋｰｺﾝﾊﾟﾈﾙ 有無
";
CM_ SG_ 1673 MET689_16_6_SEAT_HEATER_SUP "ｼｰﾄﾋｰﾀ 有無
";
CM_ SG_ 1673 MET689_16_7_SEAT_VENT_SUP "ｼｰﾄ空調 有無
";
CM_ SG_ 1673 MET689_15_0_CAMERA "ｶﾒﾗｼｽﾃﾑ情報
";
CM_ SG_ 1673 MET689_14_0_SXM_VARIANT "SXMバリアント
";
CM_ SG_ 1673 MET689_13_0_DAB "DABｱﾝﾃﾅ有無
";
CM_ SG_ 1673 MET689_13_1_SXM "SXMｱﾝﾃﾅ有無
";
CM_ SG_ 1673 MET689_13_2_EMBEDDED_NAVI "ｴﾝﾍﾞﾃﾞｯﾄﾅﾋﾞ有無
";
CM_ SG_ 1673 MET689_12_0_SPK_AMP "ｽﾋﾟｰｶｰ+AMP
";
CM_ SG_ 1673 MET689_11_0_DEST_VEHICLE "仕向地情報(車両別)
";
CM_ SG_ 1673 MET689_10_0_RDIFF_TEMP_SUP "REAR DIFF TEMP機能有無
";
CM_ SG_ 1673 MET689_10_1_SIDRIVE_SW_TYPE "SIﾄﾞﾗｲﾌﾞSW種別
";
CM_ SG_ 1673 MET689_10_3_XMODE_SW_TYPE "XﾓｰﾄﾞSW種別
";
CM_ SG_ 1673 MET689_9_0_GPF_SUP "GPF機能有無
";
CM_ SG_ 1673 MET689_9_1_SRH_SUP "SRH有無
";
CM_ SG_ 1673 MET689_9_2_AUTO_DOOR_MIRROR_SUP "ｵｰﾄ電動格納ﾄﾞｱﾐﾗｰ有無
";
CM_ SG_ 1673 MET689_9_3_REAR_REMIND_SUP "後席ﾘﾏｲﾝﾄﾞ機能有無
";
CM_ SG_ 1673 MET689_9_4_DRIVE_TYPE "FF/AWD判定結果
";
CM_ SG_ 1673 MET689_9_5_TPMSDISP_SUP "TPMS表示判定結果
";
CM_ SG_ 1673 MET689_9_6_GSI_SUP "GSI表示有無
";
CM_ SG_ 1673 MET689_9_7_SRVD_SUP "SRVD有無
";
CM_ SG_ 1673 MET689_8_0_XMODE_SUP "Xモード有無
";
CM_ SG_ 1673 MET689_7_0_SIDRIVE_SUP "SIﾄﾞﾗｲﾌﾞ有無
";
CM_ SG_ 1673 MET689_6_0_GRADE_INFO "ｸﾞﾚｰﾄﾞ情報
";
CM_ SG_ 1673 MET689_5_0_VEHICLE_TYPE "車型情報
";
CM_ SG_ 1673 MET689_4_0_DEST_GRP "仕向地(ｸﾞﾙｰﾌﾟ)
";
CM_ SG_ 1673 MET689_3_0_VEHICLE_MODEL "車両ﾓﾃﾞﾙ
";
CM_ SG_ 1673 MET689_2_0_E2E_COUNTER "E2Eｶｳﾝﾀ
";
CM_ SG_ 1673 MET689_0_0_CRC "CRC
";
CM_ SG_ 1672 MET688_13_5_STATUS_PWRLMT_WARN "出力制限警告灯状態
";
CM_ SG_ 1672 MET688_13_3_STATUS_HVB_WARN "高電圧ﾊﾞｯﾃﾘ温度警告灯状態
";
CM_ SG_ 1672 MET688_13_0_STATUS_EV_FAIL "EVﾌｪｰﾙ状態
";
CM_ SG_ 1672 MET688_12_6_STATUS_ICY_ROAD "路面凍結警報状態
";
CM_ SG_ 1672 MET688_12_5_STATUS_DOOR_DRVR "ﾄﾞｱ警告灯(D席)状態
";
CM_ SG_ 1672 MET688_12_4_STATUS_DOOR_PASS "ﾄﾞｱ警告灯(P席)状態
";
CM_ SG_ 1672 MET688_12_3_STATUS_DOOR_RRRH "ﾄﾞｱ警告灯(後席右)状態
";
CM_ SG_ 1672 MET688_12_2_STATUS_DOOR_RRLH "ﾄﾞｱ警告灯(後席左)状態
";
CM_ SG_ 1672 MET688_12_1_STATUS_DOOR_RG "ﾄﾞｱ警告灯(Rｹﾞｰﾄ)状態
";
CM_ SG_ 1672 MET688_12_0_STATUS_DOOR_TR "ﾄﾞｱ警告灯(ﾄﾗﾝｸ)状態
";
CM_ SG_ 1672 MET688_11_5_STATUS_IPMS_IND "IPMSｲﾝｼﾞｹｰﾀ状態
";
CM_ SG_ 1672 MET688_11_2_STATUS_SIDRIVE_MODE "SIﾄﾞﾗｲﾌﾞﾓｰﾄﾞ状態
";
CM_ SG_ 1672 MET688_11_0_STATUS_HEADLAMP_FAIL "LEDﾛｰﾋﾞｰﾑﾌｪｰﾙ灯状態
";
CM_ SG_ 1672 MET688_10_7_STATUS_HBA_FAIL "HBAﾌｪｰﾙ灯状態
";
CM_ SG_ 1672 MET688_10_5_STATUS_HBA_ACT "HBA作動灯状態
";
CM_ SG_ 1672 MET688_10_4_STATUS_RAB_OFF "RAB機能OFF状態
";
CM_ SG_ 1672 MET688_10_2_STATUS_EPB_ACT "EPB作動灯状態
";
CM_ SG_ 1672 MET688_10_1_STATUS_PCR_OFF "P-CR OFF灯状態
";
CM_ SG_ 1672 MET688_10_0_STATUS_LANEOFF_WARN "LANE OFF警告灯状態
";
CM_ SG_ 1672 MET688_9_5_STATUS_CODE_HALT "HALTｺｰﾄﾞ状態
";
CM_ SG_ 1672 MET688_9_4_STATUS_HOOD_OPEN "ﾌｰﾄﾞ開警告灯状態
";
CM_ SG_ 1672 MET688_9_3_STATUS_BSD_OFF "BSD OFF灯状態
";
CM_ SG_ 1672 MET688_9_2_STATUS_BSD_FAIL "BSDﾌｪｰﾙ灯状態
";
CM_ SG_ 1672 MET688_9_0_STATUS_SONAR_SYS_FAIL "ｿﾅｰｼｽﾃﾑ故障状態
";
CM_ SG_ 1672 MET688_8_5_STATUS_ABG_PASS_IND "P席 A/B作動ﾓｰﾄﾞｲﾝｼﾞｹｰﾀ状態
";
CM_ SG_ 1672 MET688_8_4_STATUS_HEADLAMP_SMALL "ﾗｲﾄﾎﾟｼﾞｼｮﾝ灯状態
";
CM_ SG_ 1672 MET688_8_2_STATUS_HDC "ﾋﾙﾃﾞｨｾﾝﾄｺﾝﾄﾛｰﾙ灯状態
";
CM_ SG_ 1672 MET688_8_1_STATUS_CC_SET_IND "ｸﾙｺﾝｾｯﾄｲﾝｼﾞｹｰﾀ状態
";
CM_ SG_ 1672 MET688_8_0_STATUS_CC_MAIN_IND "ｸﾙｺﾝﾒｲﾝｲﾝｼﾞｹｰﾀ状態
";
CM_ SG_ 1672 MET688_7_7_STATUS_FT_FOG "ﾌﾛﾝﾄﾌｫｸﾞ灯状態
";
CM_ SG_ 1672 MET688_7_4_STATUS_SRH "SRH OFF/FAIL灯状態
";
CM_ SG_ 1672 MET688_7_1_STATUS_AHL "AHL灯状態
";
CM_ SG_ 1672 MET688_7_0_STATUS_HEADLAMP_HI "ﾍｯﾄﾞﾗﾝﾌﾟ Hi灯状態
";
CM_ SG_ 1672 MET688_6_7_STATUS_AVH_ACT "AVH作動灯状態
";
CM_ SG_ 1672 MET688_6_6_STATUS_AVH_ON "AVH_ON灯状態
";
CM_ SG_ 1672 MET688_6_4_STATUS_BREAK_IND "ﾌﾞﾚｰｷ踏み指示状態
";
CM_ SG_ 1672 MET688_6_0_STATUS_WARN_SSP_SIG1 "ｽﾏｰﾄｼｽﾃﾑ警報信号1状態
";
CM_ SG_ 1672 MET688_5_4_STATUS_VDC_OFF "VDC_OFF灯状態
";
CM_ SG_ 1672 MET688_5_3_STATUS_CHG_WARN "ﾁｬｰｼﾞ警告灯状態
";
CM_ SG_ 1672 MET688_5_2_STATUS_SEATBELT_PASS "ｼｰﾄﾍﾞﾙﾄﾊﾞｯｸﾙSW状態(P席)
";
CM_ SG_ 1672 MET688_5_1_STATUS_SEATBELT_DRVR "ｼｰﾄﾍﾞﾙﾄﾊﾞｯｸﾙSW状態(D席)
";
CM_ SG_ 1672 MET688_5_0_STATUS_EYESIGHT_FAIL "ｱｲｻｲﾄﾌｪｰﾙ状態
";
CM_ SG_ 1672 MET688_4_5_STATUS_EPS_WARN "EPS警告灯状態
";
CM_ SG_ 1672 MET688_4_3_STATUS_ABG_WARN "ｴｱﾊﾞｯｸﾞ警告灯状態
";
CM_ SG_ 1672 MET688_4_0_STATUS_TPMS_WARN "TPMS警告灯状態
";
CM_ SG_ 1672 MET688_3_5_STATUS_EBD_WARN "EBD警告状態
";
CM_ SG_ 1672 MET688_3_4_STATUS_VDC_WARN "VDC警告状態
";
CM_ SG_ 1672 MET688_3_3_STATUS_ABS_WARN "ABS警告灯状態
";
CM_ SG_ 1672 MET688_3_1_STATUS_AWD_WARN "AWD警告灯状態
";
CM_ SG_ 1672 MET688_3_0_STATUS_WASHER_WARN "ｳｫｯｼｬ残量警告灯状態
";
CM_ SG_ 1672 MET688_2_0_E2E_COUNTER "E2Eｶｳﾝﾀ
";
CM_ SG_ 1672 MET688_0_0_CRC "CRC
";
CM_ SG_ 1614 RKE64E_6_0_BUZ_1SHOT_IN "室内ﾌﾞｻﾞｰ　単発1回吹鳴要求
";
CM_ SG_ 1614 RKE64E_6_1_BUZ_2SHOT_IN "室内ﾌﾞｻﾞｰ　単発2回吹鳴要求
";
CM_ SG_ 1614 RKE64E_6_2_REQ_WARNG_BAT_POWER "電池残量警告表示要求
";
CM_ SG_ 1614 RKE64E_4_0_TRANS_ID "送信機ID
";
CM_ SG_ 1614 RKE64E_4_3_COUNTER "ｶｳﾝﾀ値
";
CM_ SG_ 1614 RKE64E_4_5_TIME_ON_SW_KEY_LESS "SW ON時間
";
CM_ SG_ 1614 RKE64E_3_0_REQ_NOMAL_KEY_LESS "ﾉｰﾏﾙｷｰﾚｽ要求
";
CM_ SG_ 1614 RKE64E_1_0_MSG_COUNTER "ﾒｯｾｰｼﾞｶｳﾝﾀ
";
CM_ SG_ 1614 RKE64E_1_4_WAKE_UP_FRAME "ｳｪｲｸｱｯﾌﾟﾌﾚｰﾑ識別ﾌﾗｸﾞ
";
CM_ SG_ 1614 RKE64E_1_5_REQ_COMM_CONT "通信継続要求ﾌﾗｸﾞ
";
CM_ SG_ 1614 RKE64E_1_6 "予約:通信継続要求ﾌﾗｸﾞ(拡張)
";
CM_ SG_ 1614 RKE64E_0_0_CHECK_SUM "ﾁｪｯｸｻﾑ
";
CM_ SG_ 1658 TPM67A_6_1_TIRE_COLOR_RR "ﾀｲﾔRR表示　色
";
CM_ SG_ 1658 TPM67A_6_5_TIRE_COLOR_RL "ﾀｲﾔRL表示 色
";
CM_ SG_ 1658 TPM67A_6_7_TIRE_PRESSURE_RL "ﾀｲﾔRL 空気圧表示
";
CM_ SG_ 1658 TPM67A_5_0_TIRE_PRESSURE_RR "ﾀｲﾔRR 空気圧表示
";
CM_ SG_ 1658 TPM67A_3_1_TIRE_COLOR_FL "ﾀｲﾔFL表示 色
";
CM_ SG_ 1658 TPM67A_3_5_TIRE_COLOR_FR "ﾀｲﾔFR表示 色
";
CM_ SG_ 1658 TPM67A_3_7_TIRE_PRESSURE_FR "ﾀｲﾔFR 空気圧表示
";
CM_ SG_ 1658 TPM67A_2_0_TIRE_PRESSURE_FL "ﾀｲﾔFL 空気圧表示
";
CM_ SG_ 1658 TPM67A_1_0_MSG_COUNTER "ﾒｯｾｰｼﾞｶｳﾝﾀ
";
CM_ SG_ 1658 TPM67A_1_5_UNIT_IND_PRESSURE "空気圧表示単位
";
CM_ SG_ 1658 TPM67A_1_7_IND_PRESSURE "空気圧表示有無ﾌﾗｸﾞ
";
CM_ SG_ 1658 TPM67A_0_0_CHECK_SUM "ﾁｪｯｸｻﾑ
";
CM_ SG_ 1657 TPM679_3_0_STATE_TPMS "TPMS状態ﾌﾗｸﾞ
";
CM_ SG_ 1657 TPM679_3_2_DEFINED_STATE_TPMS "TPMS状態確定
";
CM_ SG_ 1657 TPM679_3_4_MODE_SELECT_TPMS "TPMSカスタマイズMode種別
";
CM_ SG_ 1657 TPM679_2_0_WARN_TPMS "TPMSｳｫｰﾆﾝｸﾞ
";
CM_ SG_ 1657 TPM679_2_3_INTERRUPT "割り込み表示
";
CM_ SG_ 1657 TPM679_2_5_CHECKLUMP_TPMS "TPMSチェックランプ点灯信号
";
CM_ SG_ 1657 TPM679_1_0_MSG_COUNTER "ﾒｯｾｰｼﾞｶｳﾝﾀ
";
CM_ SG_ 1657 TPM679_1_6 "予約:通信継続要求ﾌﾗｸﾞ(拡張)
";
CM_ SG_ 1657 TPM679_0_0_CHECK_SUM "ﾁｪｯｸｻﾑ
";
CM_ SG_ 827 ABG33B_4_0_PASSENGER_BELT_INFO "助手席シートベルト情報
";
CM_ SG_ 827 ABG33B_4_2_PASSENGER_DETECT_INFO "助手席乗員判定情報
";
CM_ SG_ 827 ABG33B_3_0_PPS_STATUS_FAIL_IGN "歩行者保護A/B故障有無状態（点火）
";
CM_ SG_ 827 ABG33B_3_1_PPS_STATUS_FAIL_DEV "歩行者保護A/B故障有無状態（ﾃﾞﾊﾞｲｽ）
";
CM_ SG_ 827 ABG33B_3_2_PPS_STATUS_FAIL_SSR "歩行者保護A/B故障有無状態（ｾﾝｻ）
";
CM_ SG_ 827 ABG33B_3_3_PPS_STATUS_FAIL_ECU "歩行者保護A/B故障有無状態（ECU）
";
CM_ SG_ 827 ABG33B_2_0_IND_WARN_PPA "歩行者ｴｱﾊﾞｯｸﾞｳｫｰﾆﾝｸﾞﾗﾝﾌﾟ点灯・点滅要求
";
CM_ SG_ 827 ABG33B_2_2_DETECT_CRUSH "衝突検知信号(歩行者)
";
CM_ SG_ 827 ABG33B_1_0_MSG_COUNTER "ﾒｯｾｰｼﾞｶｳﾝﾀ
";
CM_ SG_ 827 ABG33B_1_4_FLG_PEDESTRIAN_AIRBAG "歩行者保護A/B有無ﾌﾗｸﾞ
";
CM_ SG_ 827 ABG33B_1_6 "予約:通信継続要求ﾌﾗｸﾞ(拡張)
";
CM_ SG_ 827 ABG33B_0_0_CHECK_SUM "ﾁｪｯｸｻﾑ
";
CM_ SG_ 826 ABG33A_7_0_VELOCITYCHANGE_VX_MAX "衝突時ΔVx MAX
";
CM_ SG_ 826 ABG33A_6_0_VELOCITYCHANGE_VX_MAX "衝突時ΔVx MAX
";
CM_ SG_ 826 ABG33A_5_0_P_SIDE_ABG_DEPLOY "P席ｻｲﾄﾞｴｱﾊﾞｯｸﾞ展開判定
";
CM_ SG_ 826 ABG33A_5_1_D_SIDE_ABG_DEPLOY "D席ｻｲﾄﾞｴｱﾊﾞｯｸﾞ展開判定
";
CM_ SG_ 826 ABG33A_5_2_FRONT_FAR_ABG_DEPLOY "前席ﾌｧｰｻｲﾄﾞｴｱﾊﾞｯｸﾞ展開判定
";
CM_ SG_ 826 ABG33A_5_3_REAR_FAR_ABG_DEPLOY "後席ﾌｧｰｻｲﾄﾞｴｱﾊﾞｯｸﾞ展開判定
";
CM_ SG_ 826 ABG33A_5_4_REAR_RH_ABG_DEPLOY "後席ｻｲﾄﾞｴｱﾊﾞｯｸﾞRH展開判定
";
CM_ SG_ 826 ABG33A_5_5_REAR_LH_ABG_DEPLOY "後席ｻｲﾄﾞｴｱﾊﾞｯｸﾞLH展開判定
";
CM_ SG_ 826 ABG33A_5_6_P_CURTAIN_ABG_DEPLOY "P席ｶｰﾃﾝｴｱﾊﾞｯｸﾞ展開判定
";
CM_ SG_ 826 ABG33A_5_7_D_CURTAIN_ABG_DEPLOY "D席ｶｰﾃﾝｴｱﾊﾞｯｸﾞ展開判定
";
CM_ SG_ 826 ABG33A_4_0_D_FRONT_ABG_DEPLOY "D席ﾌﾛﾝﾄｴｱﾊﾞｯｸﾞ展開判定
";
CM_ SG_ 826 ABG33A_4_1_P_FRONT_ABG_DEPLOY "P席ﾌﾛﾝﾄｴｱﾊﾞｯｸﾞ展開判定
";
CM_ SG_ 826 ABG33A_4_2_P_ABG_DEPLOY "P席ｼｰﾄｸｯｼｮﾝｴｱﾊﾞｯｸﾞ展開判定
";
CM_ SG_ 826 ABG33A_4_3_D_ABG_DEPLOY "D席ｼｰﾄｸｯｼｮﾝｴｱﾊﾞｯｸﾞ展開判定
";
CM_ SG_ 826 ABG33A_4_4_P_BELT_PRETENTION "P席ｼｰﾄﾍﾞﾙﾄﾌﾟﾘﾃﾝｼｮﾅ展開判定
";
CM_ SG_ 826 ABG33A_4_5_D_BELT_PRETENTION "D席ｼｰﾄﾍﾞﾙﾄﾌﾟﾘﾃﾝｼｮﾅ展開判定
";
CM_ SG_ 826 ABG33A_4_6_D_KNEE_ABG_DEPLOY "D席ﾆｰｴｱﾊﾞｯｸﾞ展開判定
";
CM_ SG_ 826 ABG33A_4_7_P_KNEE_ABG_DEPLOY "P席ﾆｰｴｱﾊﾞｯｸﾞ展開判定
";
CM_ SG_ 826 ABG33A_3_0_BELT_WRNING_PASS "P席ﾍﾞﾙﾄ状態(ｳｫｰﾆﾝｸﾞ出力用)
";
CM_ SG_ 826 ABG33A_3_2_BUCKLESW_DRVR "D席ﾊﾞｯｸﾙｽｲｯﾁ
";
CM_ SG_ 826 ABG33A_3_4_OCCUPATION_PASS "P席乗員有無信号
";
CM_ SG_ 826 ABG33A_3_6_IND_ACT_ABG_PASS "P席A/B作動ﾓｰﾄﾞｲﾝｼﾞｹｰﾀ
";
CM_ SG_ 826 ABG33A_2_0_IND_WARN_ABG "ｴｱﾊﾞｯｸﾞｳｫｰﾆﾝｸﾞﾗﾝﾌﾟ点灯・点滅要求
";
CM_ SG_ 826 ABG33A_2_2_DETECT_CRUSH "衝突検知信号
";
CM_ SG_ 826 ABG33A_2_5_STATUS_CRUSH_ECALL "衝突形態
";
CM_ SG_ 826 ABG33A_1_0_MSG_COUNTER "ﾒｯｾｰｼﾞｶｳﾝﾀ
";
CM_ SG_ 826 ABG33A_1_4_FLG_ABGIND_CTRL "P席 A/B ON/OFFｲﾝｼﾞｹｰﾀ点灯要求有無ﾌﾗｸﾞ
";
CM_ SG_ 826 ABG33A_1_5_REQ_COMM_CONT "通信継続要求
";
CM_ SG_ 826 ABG33A_1_6_COLLISION_COUNTER "衝突判定回数
";
CM_ SG_ 826 ABG33A_0_0_CHECK_SUM "ﾁｪｯｸｻﾑ
";
CM_ SG_ 961 DMS3C1_7_4_SHORT_DIST_DETECT "ショートディストラクション判定フラグ
";
CM_ SG_ 961 DMS3C1_7_5_PRESENCE_DETECT "後席乗員検知情報
";
CM_ SG_ 961 DMS3C1_7_6_RADER_EQUIP "ミリ波搭載情報
";
CM_ SG_ 961 DMS3C1_7_7_LOSING_POSTURE_DETECT "異常姿勢検知フラグ
";
CM_ SG_ 961 DMS3C1_6_0_ID_RECOG_CANCEL "ID認識中断フラグ
";
CM_ SG_ 961 DMS3C1_6_1_ID_ENABLE_FLAG "ID有効フラグ
";
CM_ SG_ 961 DMS3C1_6_2_PERMIT_AVN_FLAG "AVN操作許可フラグ
";
CM_ SG_ 961 DMS3C1_6_4_DISTRACTION_STATUS "脇見状態フラグ
";
CM_ SG_ 961 DMS3C1_6_5_DROWSINESS_STATUS "閉眼状態フラグ
";
CM_ SG_ 961 DMS3C1_6_6_DROWSINESS_LV2_STATUS "強い眠気状態フラグ
";
CM_ SG_ 961 DMS3C1_6_7_NOT_DETECTED_STATUS "顔未検出状態フラグ
";
CM_ SG_ 961 DMS3C1_5_0_ID_LIST "ID登録リスト
";
CM_ SG_ 961 DMS3C1_5_5_ID_EDIT_FLAG "ID設定フラグ
";
CM_ SG_ 961 DMS3C1_4_0_DMS_IND_REQ_FLAG "インジゲータ点灯フラグ
";
CM_ SG_ 961 DMS3C1_4_3_DMS_RECOG_STATUS "個人認識ON/OFF状態
";
CM_ SG_ 961 DMS3C1_4_4_DRIVER_STATUS "D席乗員状態
";
CM_ SG_ 961 DMS3C1_3_0_DRIVER_REGIST_ID "個人ID
";
CM_ SG_ 961 DMS3C1_3_4_CUST_EDIT_FLAG "カスタマイズ操作フラグ
";
CM_ SG_ 961 DMS3C1_3_6_ID_RECOG_FLAG "ID識別フラグ
";
CM_ SG_ 961 DMS3C1_2_0_LEVEL_DROWS "居眠り深度
";
CM_ SG_ 961 DMS3C1_2_3_DROWS_DETECT_FLAG "居眠り判定フラグ
";
CM_ SG_ 961 DMS3C1_2_7_DIST_DETECT_FLAG "脇見判定フラグ
";
CM_ SG_ 961 DMS3C1_1_0_MSG_COUNTER "メッセージカウンタ
";
CM_ SG_ 961 DMS3C1_1_4_WAKE_UP_FRAME "ｳｪｲｸｱｯﾌﾟﾌﾚｰﾑ識別ﾌﾗｸﾞ
";
CM_ SG_ 961 DMS3C1_1_5_REQ_COMM_CONT "通信継続要求ﾌﾗｸﾞ
";
CM_ SG_ 961 DMS3C1_1_7_EYE_DIST_FLAG "早鳴りフラグ
";
CM_ SG_ 961 DMS3C1_0_0_CHKSUM "ﾁｪｯｸｻﾑ
";
CM_ SG_ 1290 DMS50A_1_4_ActiveWakeUpBit "Active Wakeup ﾌﾗｸﾞ
";
CM_ SG_ 1290 DMS50A_0_0_SourceNodeID "送信元ID
";
CM_ SG_ 1730 AVN6C2_7_0_LANGUAGE_SET "言語設定情報
";
CM_ SG_ 1730 AVN6C2_7_6_VALETMODE_ON_OFF "ValetMode状態
";
CM_ SG_ 1730 AVN6C2_1_0_MSG_COUNTER "ﾒｯｾｰｼﾞｶｳﾝﾀ
";
CM_ SG_ 1730 AVN6C2_0_0_CHECK_SUM "ﾁｪｯｸｻﾑ
";
CM_ SG_ 1729 AVN6C1_7_0_MVS_VIEW_SELECT_SW "MVS映像切替画面内ｽｲｯﾁ情報
";
CM_ SG_ 1729 AVN6C1_7_4_MVS_AUTO_DISPLAY_SW "MVSカメラ自動表示スイッチ情報
";
CM_ SG_ 1729 AVN6C1_7_6_MVS_HITCH_GUIDE_REQ "ヒッチボールガイド線ON/OFF変更要求
";
CM_ SG_ 1729 AVN6C1_1_0_MSG_COUNTER "ﾒｯｾｰｼﾞｶｳﾝﾀ
";
CM_ SG_ 1729 AVN6C1_0_0_CHECK_SUM "ﾁｪｯｸｻﾑ
";
CM_ SG_ 1725 AVN6BD_7_1_EYE_SAFETY_MODE_CSTM "障害物なし加速抑制カスタマイズ
";
CM_ SG_ 1725 AVN6BD_7_2_EYE_BRAKE_HAPTIC_CSTM "ブレーキハプティックカスタマイズ
";
CM_ SG_ 1725 AVN6BD_7_4_LDW_SW_PUSH_STATE "LDW音OFFハードSW押下状態
";
CM_ SG_ 1725 AVN6BD_7_5_LDW_SW_FAIL_STATE "LDW音OFFハードSW異常状態
";
CM_ SG_ 1725 AVN6BD_7_6_FCW_SW_PUSH_STATE "FCW音OFFハードSW押下状態
";
CM_ SG_ 1725 AVN6BD_7_7_FCW_SW_FAIL_STATE "FCW音OFFハードSW異常状態
";
CM_ SG_ 1725 AVN6BD_6_0_REQ_CHG_CSTM_EYE "アイサイトカスタマイズ要求変更
";
CM_ SG_ 1725 AVN6BD_6_1_REQ_RESET_CSTM_EYE "アイサイトカスタマイズリセット要求
";
CM_ SG_ 1725 AVN6BD_6_3_CSTM_LANE_CONT "アイサイトカスタマイズ変更設定(通行車線)
";
CM_ SG_ 1725 AVN6BD_6_4_CSTM_MIS_AT_BACK "アイサイトカスタマイズ変更設定(AT誤後進抑制制御)
";
CM_ SG_ 1725 AVN6BD_6_6_CSTM_ACC_CONT "アイサイトカスタマイズ変更設定(ACC加速特性)
";
CM_ SG_ 1725 AVN6BD_1_0_MSG_COUNTER "ﾒｯｾｰｼﾞｶｳﾝﾀ
";
CM_ SG_ 1725 AVN6BD_0_0_CHECK_SUM "ﾁｪｯｸｻﾑ
";
CM_ SG_ 1724 AVN6BC_6_0_LAT_MINUTE "緯度_分
";
CM_ SG_ 1724 AVN6BC_6_6_LAT_SECOND "緯度_秒
";
CM_ SG_ 1724 AVN6BC_5_0_LAT_N_S "緯度_南北
";
CM_ SG_ 1724 AVN6BC_5_1_LAT_DEGREE "緯度_度
";
CM_ SG_ 1724 AVN6BC_3_0_LON_MINUTE "経度_分
";
CM_ SG_ 1724 AVN6BC_3_6_LON_SECOND "経度_秒
";
CM_ SG_ 1724 AVN6BC_2_0_LON_DEGREE "経度_度
";
CM_ SG_ 1724 AVN6BC_1_0_MSG_COUNTER "ﾒｯｾｰｼﾞｶｳﾝﾀ
";
CM_ SG_ 1724 AVN6BC_1_4_GNSS_STATUS "GNSS測位状態
";
CM_ SG_ 1724 AVN6BC_1_7_LON_E_W "経度_東西
";
CM_ SG_ 1724 AVN6BC_0_0_CHECK_SUM "ﾁｪｯｸｻﾑ
";
CM_ SG_ 1723 AVN6BB_7_0_ISA_IACC_OFFSET_CSTM "ISA制限車速・iACCセット車速オフセット値
";
CM_ SG_ 1723 AVN6BB_7_5_EYE_TOLLBOOTH_DECEL "料金所減速ｶｽﾀﾏｲｽﾞ(高度運転支援)
";
CM_ SG_ 1723 AVN6BB_7_6_EYE_CURVE_DECEL_CSTM "カーブ減速ｶｽﾀﾏｲｽﾞ（高度運転支援）
";
CM_ SG_ 1723 AVN6BB_7_7_EYE_GREEN_LIGHT_CSTM "青信号切り替わりお知らせ設定
";
CM_ SG_ 1723 AVN6BB_6_0_CCU_FAIL "CCU/CIDﾌｪｰﾙﾌﾗｸﾞ
";
CM_ SG_ 1723 AVN6BB_6_1_EYE_P_CR_CSTM "P-CR ON/OFF設定
";
CM_ SG_ 1723 AVN6BB_6_2_EYE_ALK_B_LDW_CSTM "車線逸脱防止+車線逸脱警報 ON/OFF設定
";
CM_ SG_ 1723 AVN6BB_6_4_EYE_CSTM_REQ "EyeSightｶｽﾀﾏｲｽﾞ変更要求
";
CM_ SG_ 1723 AVN6BB_6_5_EYE_ELK_CSTM "ELK ON/OFF設定
";
CM_ SG_ 1723 AVN6BB_6_6_EYE_ALKB_EDGE_CSTM "ﾛｰﾄﾞｴｯｼﾞALKBｶｽﾀﾏｲｽﾞ（ALKの制御種別）
";
CM_ SG_ 1723 AVN6BB_6_7_FCW_ON_OFF "FCW機能 ON/OFF設定
";
CM_ SG_ 1723 AVN6BB_5_0_DMS_SELECT_ID "DMS選択ID
";
CM_ SG_ 1723 AVN6BB_5_4_TPMS_TH_MODE_CSTM "TPMS閾値ﾓｰﾄﾞｶｽﾀﾏｲｽﾞ
";
CM_ SG_ 1723 AVN6BB_5_6_DMS_SET_REQ "DMS設定変更要求ﾌﾗｸﾞ
";
CM_ SG_ 1723 AVN6BB_5_7_DMS_RECOG_SET "DMS個人認識ON/OFF設定
";
CM_ SG_ 1723 AVN6BB_4_0_DMS_EDIT_REQ "DMS操作中ﾌﾗｸﾞ
";
CM_ SG_ 1723 AVN6BB_4_4_VEHICLE_DEMO "車両連携デモモード（DMSなど）
";
CM_ SG_ 1723 AVN6BB_4_5_SRVD_CSTM_REQ "SRVDｶｽﾀﾏｲｽﾞ変更要求
";
CM_ SG_ 1723 AVN6BB_4_6_SEAT_RESET_REQ "ｼｰﾄｶｽﾀﾏｲｽﾞﾘｾｯﾄ要求
";
CM_ SG_ 1723 AVN6BB_4_7_SEATAWAY_SET_CSTM "ｼｰﾄ後退設定変更要求
";
CM_ SG_ 1723 AVN6BB_3_0_SRVD_ON_OFF "SRVD ON/OFF SW情報
";
CM_ SG_ 1723 AVN6BB_3_1_PRG_RESET_REQ "PRGｶｽﾀﾏｲｽﾞﾘｾｯﾄ要求
";
CM_ SG_ 1723 AVN6BB_3_2_PRG_MEM_CSTM "PRGﾒﾓﾘ設定変更要求
";
CM_ SG_ 1723 AVN6BB_3_3_DMS_ON_OFF "DMS ON/OFF SW情報
";
CM_ SG_ 1723 AVN6BB_3_4_MIR_RESET_REQ "ﾄﾞｱﾐﾗｰｶｽﾀﾏｲｽﾞﾘｾｯﾄ要求
";
CM_ SG_ 1723 AVN6BB_3_5_MIR_AFOLD_CSTM "ｵｰﾄ電動格納ﾄﾞｱﾐﾗｰ設定変更要求
";
CM_ SG_ 1723 AVN6BB_3_6_MIR_RTILT_CSTM "ﾘﾊﾞｰｽ連動ﾄﾞｱﾐﾗｰ設定変更要求
";
CM_ SG_ 1723 AVN6BB_3_7_EYE_TSA_CSTM "標識認識連動TSA（ISA/iACC） ON/OFF設定
";
CM_ SG_ 1723 AVN6BB_2_0_AVH_ON_OFF "AVH ON/OFF SW情報
";
CM_ SG_ 1723 AVN6BB_2_2_VDC_ON_OFF "VDC ON/OFF 情報
";
CM_ SG_ 1723 AVN6BB_2_4_CCU_HALT_RESET "CCUリセット・一時停止フラグ
";
CM_ SG_ 1723 AVN6BB_2_5_EYE_LDW_TIMING_CSTM "LDWタイミングユーザ設定値
";
CM_ SG_ 1723 AVN6BB_2_6_FCW_CSTM "FCWカスタマイズ設定
";
CM_ SG_ 1723 AVN6BB_1_0_MSG_COUNTER "ﾒｯｾｰｼﾞｶｳﾝﾀ
";
CM_ SG_ 1723 AVN6BB_1_4_EYE_WARN_CSTM "ｽﾃｱ振動ｶｽﾀﾏｲｽﾞ
";
CM_ SG_ 1723 AVN6BB_1_5_EYE_FCTI_CSTM "FCTI(交差車両接近通知)
";
CM_ SG_ 1723 AVN6BB_1_7_LDW_WARNING_ON_OFF "LDW音 ON/OFF設定
";
CM_ SG_ 1723 AVN6BB_0_0_CHECK_SUM "ﾁｪｯｸｻﾑ
";
CM_ SG_ 1722 AVN6BA_7_0_GUIDE_LINE_REAR "Rカメラガイド線表示設定(ON/OFF)
";
CM_ SG_ 1722 AVN6BA_7_1_GUIDE_LINE_SIDE "Sカメラガイド線表示設定(ON/OFF)
";
CM_ SG_ 1722 AVN6BA_7_2_GUIDE_LINE_FRONT "Fカメラガイド線表示設定(ON/OFF)
";
CM_ SG_ 1722 AVN6BA_7_3_STEER_ANGLE_INTERLOCK "Rカメラガイド線舵角連動設定(連動/固定)
";
CM_ SG_ 1722 AVN6BA_7_4_BACK_CAMERA_DELAY "Rカメラ9秒Delay表示設定(ON/OFF)
";
CM_ SG_ 1722 AVN6BA_7_5_REQ_STOP_CAMERA_OUT "カメラ映像出力停止要求フラグ
";
CM_ SG_ 1722 AVN6BA_7_6_VIEW_CHANGE_SW "カメラ切替SW信号
";
CM_ SG_ 1722 AVN6BA_6_0_CLIMAITE_PA_TEMP "音声認識ｴｱｺﾝ Pa_TEMP
";
CM_ SG_ 1722 AVN6BA_6_6_CLIMATE_SYNC "ｴｱｺﾝﾊﾟﾈﾙ SYNC SW
";
CM_ SG_ 1722 AVN6BA_6_7_CLIMATE_F_DEF "Front DEF SW
";
CM_ SG_ 1722 AVN6BA_5_0_CLIMAITE_DR_TEMP "音声認識ｴｱｺﾝ Dr_TEMP
";
CM_ SG_ 1722 AVN6BA_5_6_CLIMAITE_AUTO "音声認識ｴｱｺﾝ AUTO SW
";
CM_ SG_ 1722 AVN6BA_5_7_CLIMAITE_MAX_AC "音声認識ｴｱｺﾝ MAX A/C SW
";
CM_ SG_ 1722 AVN6BA_4_0_CLIMAITE_VR "音声認識ｴｱｺﾝ操作ﾌﾗｸﾞ
";
CM_ SG_ 1722 AVN6BA_4_3_CLIMATE_AC "ｴｱｺﾝﾊﾟﾈﾙ A/C SW
";
CM_ SG_ 1722 AVN6BA_4_4_CLIMAITE_FAN "音声認識ｴｱｺﾝ FAN
";
CM_ SG_ 1722 AVN6BA_3_0_PERSONAL_IC_SH "ﾊﾟｰｿﾅﾗｲｽﾞ：H/Unit（ｽﾏｰﾄﾌｫﾝ無し時）による個人識別ｺｰﾄﾞ
";
CM_ SG_ 1722 AVN6BA_3_4_CSTM_SONNER "ｿﾅｰｶｽﾀﾏｲｽﾞ変更設定(ｿﾅｰ ON/OFF)
";
CM_ SG_ 1722 AVN6BA_3_5_CSTM_RAB "ｿﾅｰｶｽﾀﾏｲｽﾞ変更設定(RAB　ON/OFF)
";
CM_ SG_ 1722 AVN6BA_3_6_REQ_CHG_CSTM_RAB "RABｿﾅｰｶｽﾀﾏｲｽﾞ要求変更
";
CM_ SG_ 1722 AVN6BA_3_7_CLIMATE_R_DEF "Rear DEF SW
";
CM_ SG_ 1722 AVN6BA_2_0_CLIMATE_PTC "ｴｱｺﾝﾊﾟﾈﾙ PTC 強制ON SW
";
CM_ SG_ 1722 AVN6BA_2_1_CLIMATE_MODE "ｴｱｺﾝﾊﾟﾈﾙ MODE SW
";
CM_ SG_ 1722 AVN6BA_2_2_CLIMATE_SEAT_C_L "ｴｱｺﾝﾊﾟﾈﾙ ﾍﾞﾝﾁﾚｰｼｮﾝｼｰﾄ左 SW
";
CM_ SG_ 1722 AVN6BA_2_3_CLIMATE_SEAT_C_R "ｴｱｺﾝﾊﾟﾈﾙ ﾍﾞﾝﾁﾚｰｼｮﾝｼｰﾄ右 SW
";
CM_ SG_ 1722 AVN6BA_2_4_CLIMATE_SEAT_H_L "ｴｱｺﾝﾊﾟﾈﾙ SEAT HEATER左 SW
";
CM_ SG_ 1722 AVN6BA_2_5_CLIMATE_SEAT_H_R "ｴｱｺﾝﾊﾟﾈﾙ SEAT HEATER右 SW
";
CM_ SG_ 1722 AVN6BA_2_6_CLIMATE_INNER_AIR "ｴｱｺﾝﾊﾟﾈﾙ 内外気 SW
";
CM_ SG_ 1722 AVN6BA_2_7_CLIMATE_ON_OFF "ｴｱｺﾝﾊﾟﾈﾙ 空調ON/OFF SW
";
CM_ SG_ 1722 AVN6BA_1_0_MSG_COUNTER "ﾒｯｾｰｼﾞｶｳﾝﾀ
";
CM_ SG_ 1722 AVN6BA_1_4_CLIMAITE_STATUS "音声認識状態表示
";
CM_ SG_ 1722 AVN6BA_1_7_CLIMAITE_ON_OFF "音声認識 ON/OFF
";
CM_ SG_ 1722 AVN6BA_0_0_CHECK_SUM "ﾁｪｯｸｻﾑ
";
CM_ SG_ 1713 AVN6B1_7_1_PRESENT_YEAR "現在年月日(年)
";
CM_ SG_ 1713 AVN6B1_6_0_PRESENT_DAY "現在年月日（日）
";
CM_ SG_ 1713 AVN6B1_6_5_PRESENT_MONTH "現在年月日(月)
";
CM_ SG_ 1713 AVN6B1_5_0_FAIL_AVN "AVNﾌｪｰﾙ情報
";
CM_ SG_ 1713 AVN6B1_5_1_IN_OPERATION "操作中ﾌﾗｸﾞ
";
CM_ SG_ 1713 AVN6B1_5_2_TYPE_NAVI "ﾅﾋﾞ有無ﾌﾗｸﾞ
";
CM_ SG_ 1713 AVN6B1_5_4_XM_ENABLE "XM有無ﾌﾗｸﾞ
";
CM_ SG_ 1713 AVN6B1_5_6_FLG_ABLE_WELCOME_SCL "ｳｪﾙｶﾑ画面表示可能ﾌﾗｸﾞ
";
CM_ SG_ 1713 AVN6B1_5_7_STEER_ANGLE_INTERLOCK "Rカメラガイド線舵角連動設定(ON/OFF)（H/Unit）
";
CM_ SG_ 1713 AVN6B1_4_0_PRESENT_TIME_SEC "現在時刻(秒)
";
CM_ SG_ 1713 AVN6B1_4_7_BACK_CAMERA_DELAY "Rカメラ9秒Delay表示設定(ON/OFF)（H/Unit）
";
CM_ SG_ 1713 AVN6B1_3_0_PRESENT_TIME_MIN "現在時刻(分)
";
CM_ SG_ 1713 AVN6B1_3_7_MVS_FTSNR_INTERRUPT "ｸﾘｿﾅ自動前方視界支援設定
";
CM_ SG_ 1713 AVN6B1_2_0_GPS_CLOCK_FLG "時刻補正有効ﾌﾗｸﾞ
";
CM_ SG_ 1713 AVN6B1_2_1_PRESENT_TIME_HOUR "現在時刻(時)
";
CM_ SG_ 1713 AVN6B1_2_6_TIME_FORMAT "タイムフォーマット切替(12h/24h)
";
CM_ SG_ 1713 AVN6B1_1_0_MSG_COUNTER "ﾒｯｾｰｼﾞｶｳﾝﾀ
";
CM_ SG_ 1713 AVN6B1_1_4_WAKE_UP_FRAME "ｳｪｲｸｱｯﾌﾟﾌﾚｰﾑ識別ﾌﾗｸﾞ
";
CM_ SG_ 1713 AVN6B1_1_5_REQ_COMM_CONT "通信継続要求ﾌﾗｸﾞ
";
CM_ SG_ 1713 AVN6B1_1_6_ACTIVE_AVN_CSTM "車両ｶｽﾀﾏｲｽﾞ実施状態ﾌﾗｸﾞ（H/Unit）
";
CM_ SG_ 1713 AVN6B1_1_7_REQ_STOP_CAMERA_OUT "カメラ映像出力停止要求フラグ（H/Unit）
";
CM_ SG_ 1713 AVN6B1_0_0_CHECK_SUM "ﾁｪｯｸｻﾑ
";
BA_DEF_ SG_  "Fhi_SignalComment" STRING ;
BA_DEF_ SG_  "GenSigInactiveValue" INT 0 10000;
BA_DEF_ SG_  "GenSigStartValue" FLOAT 0 100000000000;
BA_DEF_ SG_  "GenSigSendType" ENUM  "Cyclic","OnWrite","OnWriteWithRepetition","OnChange","OnChangeWithRepetition","IfActive","IfActiveWithRepetition","NoSigSendType";
BA_DEF_ BO_  "MsgRoutingId" STRING ;
BA_DEF_ BO_  "DiagResponse" ENUM  "No","Yes";
BA_DEF_ BO_  "DiagRequest" ENUM  "No","Yes";
BA_DEF_ BO_  "DiagState" ENUM  "No","Yes";
BA_DEF_ BO_  "GenMsgILSupport" ENUM  "No","Yes";
BA_DEF_ BO_  "GenMsgNrOfRepetition" INT 0 999999;
BA_DEF_ BO_  "GenMsgDelayTime" INT 0 1000;
BA_DEF_ BO_  "GenMsgCycleTimeFast" INT 0 10000;
BA_DEF_ BO_  "GenMsgCycleTime" INT 0 10000;
BA_DEF_ BO_  "GenMsgSendType" ENUM  "Cyclic","NotUsed","NotUsed","NotUsed","NotUsed","Cyclic","NotUsed","IfActive","NoMsgSendType";
BA_DEF_ BO_  "CANFD_BRS" ENUM  "0","1";
BA_DEF_ BO_  "VFrameFormat" ENUM  "StandardCAN","ExtendedCAN","reserved","reserved","reserved","reserved","reserved","reserved","reserved","reserved","reserved","reserved","reserved","reserved","StandardCAN_FD","ExtendedCAN_FD";
BA_DEF_DEF_  "Fhi_SignalComment" "";
BA_DEF_DEF_  "GenSigInactiveValue" 0;
BA_DEF_DEF_  "GenSigStartValue" 0;
BA_DEF_DEF_  "GenSigSendType" "NoSigSendType";
BA_DEF_DEF_  "MsgRoutingId" "";
BA_DEF_DEF_  "DiagResponse" "No";
BA_DEF_DEF_  "DiagRequest" "No";
BA_DEF_DEF_  "DiagState" "No";
BA_DEF_DEF_  "GenMsgILSupport" "Yes";
BA_DEF_DEF_  "GenMsgNrOfRepetition" 0;
BA_DEF_DEF_  "GenMsgDelayTime" 0;
BA_DEF_DEF_  "GenMsgCycleTimeFast" 0;
BA_DEF_DEF_  "GenMsgCycleTime" 0;
BA_DEF_DEF_  "GenMsgSendType" "Cyclic";
BA_DEF_DEF_  "CANFD_BRS" "1";
BA_DEF_DEF_  "VFrameFormat" "StandardCAN";
BA_ "MsgRoutingId" BO_ 2564481196 "174 ";
BA_ "GenMsgILSupport" BO_ 2564481196 0;
BA_ "DiagResponse" BO_ 2564481196 1;
BA_ "GenMsgNrOfRepetition" BO_ 2564481196 1;
BA_ "GenMsgSendType" BO_ 2564481196 8;
BA_ "VFrameFormat" BO_ 2564481196 15;
BA_ "MsgRoutingId" BO_ 2564467936 "173 ";
BA_ "GenMsgILSupport" BO_ 2564467936 0;
BA_ "DiagRequest" BO_ 2564467936 1;
BA_ "GenMsgNrOfRepetition" BO_ 2564467936 1;
BA_ "GenMsgSendType" BO_ 2564467936 8;
BA_ "VFrameFormat" BO_ 2564467936 15;
BA_ "MsgRoutingId" BO_ 2564481213 "168 ";
BA_ "GenMsgILSupport" BO_ 2564481213 0;
BA_ "DiagResponse" BO_ 2564481213 1;
BA_ "GenMsgNrOfRepetition" BO_ 2564481213 1;
BA_ "GenMsgSendType" BO_ 2564481213 8;
BA_ "VFrameFormat" BO_ 2564481213 1;
BA_ "MsgRoutingId" BO_ 2564472288 "167 ";
BA_ "GenMsgILSupport" BO_ 2564472288 0;
BA_ "DiagRequest" BO_ 2564472288 1;
BA_ "GenMsgNrOfRepetition" BO_ 2564472288 1;
BA_ "GenMsgSendType" BO_ 2564472288 8;
BA_ "VFrameFormat" BO_ 2564472288 1;
BA_ "MsgRoutingId" BO_ 2564481212 "166 ";
BA_ "GenMsgILSupport" BO_ 2564481212 0;
BA_ "DiagResponse" BO_ 2564481212 1;
BA_ "GenMsgNrOfRepetition" BO_ 2564481212 1;
BA_ "GenMsgSendType" BO_ 2564481212 8;
BA_ "VFrameFormat" BO_ 2564481212 1;
BA_ "MsgRoutingId" BO_ 2564472032 "165 ";
BA_ "GenMsgILSupport" BO_ 2564472032 0;
BA_ "DiagRequest" BO_ 2564472032 1;
BA_ "GenMsgNrOfRepetition" BO_ 2564472032 1;
BA_ "GenMsgSendType" BO_ 2564472032 8;
BA_ "VFrameFormat" BO_ 2564472032 1;
BA_ "MsgRoutingId" BO_ 2564481195 "164 ";
BA_ "GenMsgILSupport" BO_ 2564481195 0;
BA_ "DiagResponse" BO_ 2564481195 1;
BA_ "GenMsgNrOfRepetition" BO_ 2564481195 1;
BA_ "GenMsgSendType" BO_ 2564481195 8;
BA_ "VFrameFormat" BO_ 2564481195 15;
BA_ "MsgRoutingId" BO_ 2564467680 "163 ";
BA_ "GenMsgILSupport" BO_ 2564467680 0;
BA_ "DiagRequest" BO_ 2564467680 1;
BA_ "GenMsgNrOfRepetition" BO_ 2564467680 1;
BA_ "GenMsgSendType" BO_ 2564467680 8;
BA_ "VFrameFormat" BO_ 2564467680 15;
BA_ "MsgRoutingId" BO_ 2564481047 "156 ";
BA_ "GenMsgILSupport" BO_ 2564481047 0;
BA_ "DiagResponse" BO_ 2564481047 1;
BA_ "GenMsgNrOfRepetition" BO_ 2564481047 1;
BA_ "GenMsgSendType" BO_ 2564481047 8;
BA_ "VFrameFormat" BO_ 2564481047 15;
BA_ "MsgRoutingId" BO_ 2564429792 "155 ";
BA_ "GenMsgILSupport" BO_ 2564429792 0;
BA_ "DiagRequest" BO_ 2564429792 1;
BA_ "GenMsgNrOfRepetition" BO_ 2564429792 1;
BA_ "GenMsgSendType" BO_ 2564429792 8;
BA_ "VFrameFormat" BO_ 2564429792 15;
BA_ "GenMsgILSupport" BO_ 2564550625 0;
BA_ "DiagState" BO_ 2564550625 1;
BA_ "GenMsgNrOfRepetition" BO_ 2564550625 1;
BA_ "GenMsgSendType" BO_ 2564550625 8;
BA_ "VFrameFormat" BO_ 2564550625 1;
BA_ "MsgRoutingId" BO_ 2564550624 "125 ";
BA_ "GenMsgILSupport" BO_ 2564550624 0;
BA_ "DiagState" BO_ 2564550624 1;
BA_ "GenMsgNrOfRepetition" BO_ 2564550624 1;
BA_ "GenMsgSendType" BO_ 2564550624 8;
BA_ "VFrameFormat" BO_ 2564550624 1;
BA_ "MsgRoutingId" BO_ 1832 "124 ";
BA_ "GenMsgILSupport" BO_ 1832 0;
BA_ "DiagState" BO_ 1832 1;
BA_ "GenMsgNrOfRepetition" BO_ 1832 1;
BA_ "GenMsgSendType" BO_ 1832 8;
BA_ "GenMsgILSupport" BO_ 2564481303 0;
BA_ "DiagResponse" BO_ 2564481303 1;
BA_ "GenMsgNrOfRepetition" BO_ 2564481303 1;
BA_ "GenMsgSendType" BO_ 2564481303 8;
BA_ "VFrameFormat" BO_ 2564481303 15;
BA_ "GenMsgILSupport" BO_ 2564429793 0;
BA_ "DiagRequest" BO_ 2564429793 1;
BA_ "GenMsgNrOfRepetition" BO_ 2564429793 1;
BA_ "GenMsgSendType" BO_ 2564429793 8;
BA_ "VFrameFormat" BO_ 2564429793 15;
BA_ "GenMsgILSupport" BO_ 2564481452 0;
BA_ "DiagResponse" BO_ 2564481452 1;
BA_ "GenMsgNrOfRepetition" BO_ 2564481452 1;
BA_ "GenMsgSendType" BO_ 2564481452 8;
BA_ "VFrameFormat" BO_ 2564481452 15;
BA_ "GenMsgILSupport" BO_ 2564467937 0;
BA_ "DiagRequest" BO_ 2564467937 1;
BA_ "GenMsgNrOfRepetition" BO_ 2564467937 1;
BA_ "GenMsgSendType" BO_ 2564467937 8;
BA_ "VFrameFormat" BO_ 2564467937 15;
BA_ "GenMsgILSupport" BO_ 2564481451 0;
BA_ "DiagResponse" BO_ 2564481451 1;
BA_ "GenMsgNrOfRepetition" BO_ 2564481451 1;
BA_ "GenMsgSendType" BO_ 2564481451 8;
BA_ "VFrameFormat" BO_ 2564481451 15;
BA_ "GenMsgILSupport" BO_ 2564467681 0;
BA_ "DiagRequest" BO_ 2564467681 1;
BA_ "GenMsgNrOfRepetition" BO_ 2564467681 1;
BA_ "GenMsgSendType" BO_ 2564467681 8;
BA_ "VFrameFormat" BO_ 2564467681 15;
BA_ "GenMsgILSupport" BO_ 2564481469 0;
BA_ "DiagResponse" BO_ 2564481469 1;
BA_ "GenMsgNrOfRepetition" BO_ 2564481469 1;
BA_ "GenMsgSendType" BO_ 2564481469 8;
BA_ "VFrameFormat" BO_ 2564481469 1;
BA_ "GenMsgILSupport" BO_ 2564472289 0;
BA_ "DiagRequest" BO_ 2564472289 1;
BA_ "GenMsgNrOfRepetition" BO_ 2564472289 1;
BA_ "GenMsgSendType" BO_ 2564472289 8;
BA_ "VFrameFormat" BO_ 2564472289 1;
BA_ "GenMsgILSupport" BO_ 2564481468 0;
BA_ "DiagResponse" BO_ 2564481468 1;
BA_ "GenMsgNrOfRepetition" BO_ 2564481468 1;
BA_ "GenMsgSendType" BO_ 2564481468 8;
BA_ "VFrameFormat" BO_ 2564481468 1;
BA_ "GenMsgILSupport" BO_ 2564472033 0;
BA_ "DiagRequest" BO_ 2564472033 1;
BA_ "GenMsgNrOfRepetition" BO_ 2564472033 1;
BA_ "GenMsgSendType" BO_ 2564472033 8;
BA_ "VFrameFormat" BO_ 2564472033 1;
BA_ "GenMsgCycleTime" BO_ 1774 1000;
BA_ "VFrameFormat" BO_ 1774 14;
BA_ "GenMsgCycleTime" BO_ 1773 1000;
BA_ "VFrameFormat" BO_ 1773 14;
BA_ "GenMsgCycleTime" BO_ 1772 1000;
BA_ "VFrameFormat" BO_ 1772 14;
BA_ "GenMsgNrOfRepetition" BO_ 996 5;
BA_ "GenMsgCycleTimeFast" BO_ 996 20;
BA_ "GenMsgDelayTime" BO_ 996 10;
BA_ "GenMsgCycleTime" BO_ 996 500;
BA_ "VFrameFormat" BO_ 996 14;
BA_ "GenMsgCycleTime" BO_ 1280 1000;
BA_ "VFrameFormat" BO_ 1280 14;
BA_ "GenMsgCycleTime" BO_ 1633 1000;
BA_ "VFrameFormat" BO_ 1633 14;
BA_ "GenMsgCycleTime" BO_ 1632 500;
BA_ "VFrameFormat" BO_ 1632 14;
BA_ "GenMsgILSupport" BO_ 1752 0;
BA_ "MsgRoutingId" BO_ 1752 "117 ";
BA_ "GenMsgNrOfRepetition" BO_ 1752 1;
BA_ "GenMsgCycleTimeFast" BO_ 1752 100;
BA_ "GenMsgCycleTime" BO_ 1752 1200;
BA_ "VFrameFormat" BO_ 1752 14;
BA_ "GenMsgNrOfRepetition" BO_ 1744 1;
BA_ "GenMsgCycleTimeFast" BO_ 1744 100;
BA_ "GenMsgCycleTime" BO_ 1744 1200;
BA_ "VFrameFormat" BO_ 1744 14;
BA_ "GenMsgNrOfRepetition" BO_ 1749 10;
BA_ "GenMsgCycleTimeFast" BO_ 1749 20;
BA_ "GenMsgDelayTime" BO_ 1749 10;
BA_ "GenMsgCycleTime" BO_ 1749 1000;
BA_ "VFrameFormat" BO_ 1749 14;
BA_ "GenMsgSendType" BO_ 1699 8;
BA_ "VFrameFormat" BO_ 1699 14;
BA_ "GenMsgILSupport" BO_ 1107 0;
BA_ "MsgRoutingId" BO_ 1107 "112 ";
BA_ "GenMsgCycleTime" BO_ 1107 100;
BA_ "VFrameFormat" BO_ 1107 14;
BA_ "MsgRoutingId" BO_ 1705 "111 ";
BA_ "GenMsgNrOfRepetition" BO_ 1705 5;
BA_ "GenMsgCycleTimeFast" BO_ 1705 200;
BA_ "GenMsgDelayTime" BO_ 1705 10;
BA_ "GenMsgCycleTime" BO_ 1705 1000;
BA_ "VFrameFormat" BO_ 1705 14;
BA_ "GenMsgCycleTime" BO_ 1364 1000;
BA_ "VFrameFormat" BO_ 1364 14;
BA_ "MsgRoutingId" BO_ 930 "110 ";
BA_ "GenMsgNrOfRepetition" BO_ 930 4;
BA_ "GenMsgCycleTimeFast" BO_ 930 50;
BA_ "GenMsgDelayTime" BO_ 930 10;
BA_ "GenMsgCycleTime" BO_ 930 100;
BA_ "VFrameFormat" BO_ 930 14;
BA_ "MsgRoutingId" BO_ 1677 "109 ";
BA_ "GenMsgNrOfRepetition" BO_ 1677 5;
BA_ "GenMsgCycleTimeFast" BO_ 1677 200;
BA_ "GenMsgDelayTime" BO_ 1677 10;
BA_ "GenMsgCycleTime" BO_ 1677 1200;
BA_ "VFrameFormat" BO_ 1677 14;
BA_ "MsgRoutingId" BO_ 1676 "108 ";
BA_ "GenMsgCycleTimeFast" BO_ 1676 20;
BA_ "GenMsgDelayTime" BO_ 1676 10;
BA_ "GenMsgCycleTime" BO_ 1676 1200;
BA_ "VFrameFormat" BO_ 1676 14;
BA_ "MsgRoutingId" BO_ 922 "107 ";
BA_ "GenMsgNrOfRepetition" BO_ 922 5;
BA_ "GenMsgCycleTimeFast" BO_ 922 20;
BA_ "GenMsgDelayTime" BO_ 922 10;
BA_ "GenMsgCycleTime" BO_ 922 200;
BA_ "VFrameFormat" BO_ 922 14;
BA_ "MsgRoutingId" BO_ 915 "106 ";
BA_ "GenMsgNrOfRepetition" BO_ 915 2;
BA_ "GenMsgCycleTimeFast" BO_ 915 20;
BA_ "GenMsgDelayTime" BO_ 915 10;
BA_ "GenMsgCycleTime" BO_ 915 100;
BA_ "VFrameFormat" BO_ 915 14;
BA_ "MsgRoutingId" BO_ 912 "105 ";
BA_ "GenMsgNrOfRepetition" BO_ 912 4;
BA_ "GenMsgCycleTimeFast" BO_ 912 50;
BA_ "GenMsgDelayTime" BO_ 912 10;
BA_ "GenMsgCycleTime" BO_ 912 100;
BA_ "VFrameFormat" BO_ 912 14;
BA_ "MsgRoutingId" BO_ 1291 "104 ";
BA_ "GenMsgCycleTime" BO_ 1291 1000;
BA_ "VFrameFormat" BO_ 1291 14;
BA_ "MsgRoutingId" BO_ 914 "103 ";
BA_ "GenMsgNrOfRepetition" BO_ 914 4;
BA_ "GenMsgCycleTimeFast" BO_ 914 50;
BA_ "GenMsgDelayTime" BO_ 914 10;
BA_ "GenMsgCycleTime" BO_ 914 100;
BA_ "VFrameFormat" BO_ 914 14;
BA_ "GenMsgNrOfRepetition" BO_ 938 4;
BA_ "GenMsgCycleTimeFast" BO_ 938 50;
BA_ "GenMsgDelayTime" BO_ 938 10;
BA_ "GenMsgCycleTime" BO_ 938 100;
BA_ "VFrameFormat" BO_ 938 14;
BA_ "MsgRoutingId" BO_ 937 "102 ";
BA_ "GenMsgNrOfRepetition" BO_ 937 4;
BA_ "GenMsgCycleTimeFast" BO_ 937 50;
BA_ "GenMsgDelayTime" BO_ 937 10;
BA_ "GenMsgCycleTime" BO_ 937 100;
BA_ "VFrameFormat" BO_ 937 14;
BA_ "MsgRoutingId" BO_ 933 "101 ";
BA_ "GenMsgNrOfRepetition" BO_ 933 2;
BA_ "GenMsgCycleTimeFast" BO_ 933 20;
BA_ "GenMsgDelayTime" BO_ 933 10;
BA_ "GenMsgCycleTime" BO_ 933 100;
BA_ "VFrameFormat" BO_ 933 14;
BA_ "MsgRoutingId" BO_ 1679 "100 ";
BA_ "GenMsgNrOfRepetition" BO_ 1679 4;
BA_ "GenMsgCycleTimeFast" BO_ 1679 50;
BA_ "GenMsgDelayTime" BO_ 1679 10;
BA_ "GenMsgCycleTime" BO_ 1679 1200;
BA_ "VFrameFormat" BO_ 1679 14;
BA_ "MsgRoutingId" BO_ 1678 "99 ";
BA_ "GenMsgNrOfRepetition" BO_ 1678 4;
BA_ "GenMsgCycleTimeFast" BO_ 1678 50;
BA_ "GenMsgDelayTime" BO_ 1678 10;
BA_ "GenMsgCycleTime" BO_ 1678 1200;
BA_ "VFrameFormat" BO_ 1678 14;
BA_ "MsgRoutingId" BO_ 1674 "98 ";
BA_ "GenMsgNrOfRepetition" BO_ 1674 4;
BA_ "GenMsgCycleTimeFast" BO_ 1674 50;
BA_ "GenMsgDelayTime" BO_ 1674 10;
BA_ "GenMsgCycleTime" BO_ 1674 1200;
BA_ "VFrameFormat" BO_ 1674 14;
BA_ "MsgRoutingId" BO_ 1673 "97 ";
BA_ "GenMsgNrOfRepetition" BO_ 1673 4;
BA_ "GenMsgCycleTimeFast" BO_ 1673 50;
BA_ "GenMsgDelayTime" BO_ 1673 10;
BA_ "GenMsgCycleTime" BO_ 1673 1200;
BA_ "VFrameFormat" BO_ 1673 14;
BA_ "GenMsgNrOfRepetition" BO_ 1672 4;
BA_ "GenMsgCycleTimeFast" BO_ 1672 50;
BA_ "GenMsgDelayTime" BO_ 1672 10;
BA_ "GenMsgCycleTime" BO_ 1672 1000;
BA_ "VFrameFormat" BO_ 1672 14;
BA_ "GenMsgILSupport" BO_ 1614 0;
BA_ "MsgRoutingId" BO_ 1614 "96 ";
BA_ "GenMsgCycleTimeFast" BO_ 1614 50;
BA_ "GenMsgDelayTime" BO_ 1614 10;
BA_ "GenMsgCycleTime" BO_ 1614 1200;
BA_ "VFrameFormat" BO_ 1614 14;
BA_ "GenMsgILSupport" BO_ 1658 0;
BA_ "MsgRoutingId" BO_ 1658 "95 ";
BA_ "GenMsgCycleTime" BO_ 1658 1000;
BA_ "VFrameFormat" BO_ 1658 14;
BA_ "GenMsgILSupport" BO_ 1657 0;
BA_ "MsgRoutingId" BO_ 1657 "94 ";
BA_ "GenMsgCycleTime" BO_ 1657 1000;
BA_ "VFrameFormat" BO_ 1657 14;
BA_ "GenMsgILSupport" BO_ 827 0;
BA_ "MsgRoutingId" BO_ 827 "93 ";
BA_ "GenMsgNrOfRepetition" BO_ 827 50;
BA_ "GenMsgCycleTimeFast" BO_ 827 120;
BA_ "GenMsgDelayTime" BO_ 827 10;
BA_ "GenMsgCycleTime" BO_ 827 120;
BA_ "VFrameFormat" BO_ 827 14;
BA_ "GenMsgILSupport" BO_ 826 0;
BA_ "MsgRoutingId" BO_ 826 "92 ";
BA_ "GenMsgNrOfRepetition" BO_ 826 50;
BA_ "GenMsgCycleTimeFast" BO_ 826 120;
BA_ "GenMsgDelayTime" BO_ 826 10;
BA_ "GenMsgCycleTime" BO_ 826 120;
BA_ "VFrameFormat" BO_ 826 14;
BA_ "GenMsgILSupport" BO_ 961 0;
BA_ "MsgRoutingId" BO_ 961 "91 ";
BA_ "GenMsgNrOfRepetition" BO_ 961 3;
BA_ "GenMsgCycleTimeFast" BO_ 961 50;
BA_ "GenMsgCycleTime" BO_ 961 120;
BA_ "VFrameFormat" BO_ 961 14;
BA_ "GenMsgILSupport" BO_ 1290 0;
BA_ "MsgRoutingId" BO_ 1290 "90 ";
BA_ "GenMsgCycleTime" BO_ 1290 1000;
BA_ "VFrameFormat" BO_ 1290 14;
BA_ "GenMsgILSupport" BO_ 1730 0;
BA_ "MsgRoutingId" BO_ 1730 "77 ";
BA_ "GenMsgNrOfRepetition" BO_ 1730 4;
BA_ "GenMsgCycleTimeFast" BO_ 1730 50;
BA_ "GenMsgDelayTime" BO_ 1730 10;
BA_ "GenMsgCycleTime" BO_ 1730 1200;
BA_ "VFrameFormat" BO_ 1730 14;
BA_ "GenMsgILSupport" BO_ 1729 0;
BA_ "MsgRoutingId" BO_ 1729 "75 ";
BA_ "GenMsgNrOfRepetition" BO_ 1729 4;
BA_ "GenMsgCycleTimeFast" BO_ 1729 50;
BA_ "GenMsgDelayTime" BO_ 1729 10;
BA_ "GenMsgCycleTime" BO_ 1729 1200;
BA_ "VFrameFormat" BO_ 1729 14;
BA_ "GenMsgILSupport" BO_ 1725 0;
BA_ "MsgRoutingId" BO_ 1725 "74 ";
BA_ "GenMsgNrOfRepetition" BO_ 1725 4;
BA_ "GenMsgCycleTimeFast" BO_ 1725 50;
BA_ "GenMsgDelayTime" BO_ 1725 10;
BA_ "GenMsgCycleTime" BO_ 1725 1200;
BA_ "VFrameFormat" BO_ 1725 14;
BA_ "GenMsgILSupport" BO_ 1724 0;
BA_ "MsgRoutingId" BO_ 1724 "73 ";
BA_ "GenMsgNrOfRepetition" BO_ 1724 1;
BA_ "GenMsgCycleTimeFast" BO_ 1724 1000;
BA_ "GenMsgDelayTime" BO_ 1724 200;
BA_ "GenMsgCycleTime" BO_ 1724 1200;
BA_ "VFrameFormat" BO_ 1724 14;
BA_ "GenMsgILSupport" BO_ 1723 0;
BA_ "MsgRoutingId" BO_ 1723 "72 ";
BA_ "GenMsgNrOfRepetition" BO_ 1723 4;
BA_ "GenMsgCycleTimeFast" BO_ 1723 50;
BA_ "GenMsgDelayTime" BO_ 1723 10;
BA_ "GenMsgCycleTime" BO_ 1723 1200;
BA_ "VFrameFormat" BO_ 1723 14;
BA_ "GenMsgILSupport" BO_ 1722 0;
BA_ "MsgRoutingId" BO_ 1722 "71 ";
BA_ "GenMsgNrOfRepetition" BO_ 1722 3;
BA_ "GenMsgCycleTimeFast" BO_ 1722 20;
BA_ "GenMsgSendType" BO_ 1722 8;
BA_ "GenMsgDelayTime" BO_ 1722 10;
BA_ "VFrameFormat" BO_ 1722 14;
BA_ "GenMsgILSupport" BO_ 1713 0;
BA_ "MsgRoutingId" BO_ 1713 "70 ";
BA_ "GenMsgNrOfRepetition" BO_ 1713 1;
BA_ "GenMsgCycleTimeFast" BO_ 1713 20;
BA_ "GenMsgDelayTime" BO_ 1713 10;
BA_ "GenMsgCycleTime" BO_ 1713 1200;
BA_ "VFrameFormat" BO_ 1713 14;
BA_ "GenSigSendType" SG_ 2564481196 MVS18DAE0AC_DIAG_DATA_EXT7 2;
BA_ "GenSigSendType" SG_ 2564481196 MVS18DAE0AC_DIAG_DATA_EXT6 2;
BA_ "GenSigSendType" SG_ 2564481196 MVS18DAE0AC_DIAG_DATA_EXT5 2;
BA_ "GenSigSendType" SG_ 2564481196 MVS18DAE0AC_DIAG_DATA_EXT4 2;
BA_ "GenSigSendType" SG_ 2564481196 MVS18DAE0AC_DIAG_DATA_EXT3 2;
BA_ "GenSigSendType" SG_ 2564481196 MVS18DAE0AC_DIAG_DATA_EXT2 2;
BA_ "GenSigSendType" SG_ 2564481196 MVS18DAE0AC_DIAG_DATA_EXT1 2;
BA_ "GenSigSendType" SG_ 2564481196 MVS18DAE0AC_DIAG_DATA 2;
BA_ "GenSigSendType" SG_ 2564467936 DNT18DAACE0_DIAG_DATA_EXT7 2;
BA_ "GenSigSendType" SG_ 2564467936 DNT18DAACE0_DIAG_DATA_EXT6 2;
BA_ "GenSigSendType" SG_ 2564467936 DNT18DAACE0_DIAG_DATA_EXT5 2;
BA_ "GenSigSendType" SG_ 2564467936 DNT18DAACE0_DIAG_DATA_EXT4 2;
BA_ "GenSigSendType" SG_ 2564467936 DNT18DAACE0_DIAG_DATA_EXT3 2;
BA_ "GenSigSendType" SG_ 2564467936 DNT18DAACE0_DIAG_DATA_EXT2 2;
BA_ "GenSigSendType" SG_ 2564467936 DNT18DAACE0_DIAG_DATA_EXT1 2;
BA_ "GenSigSendType" SG_ 2564467936 DNT18DAACE0_DIAG_DATA 2;
BA_ "GenSigSendType" SG_ 2564481213 RCR18DAE0BD_DIAG_DATA 2;
BA_ "GenSigSendType" SG_ 2564472288 DNT18DABDE0_DIAG_DATA 2;
BA_ "GenSigSendType" SG_ 2564481212 RCR18DAE0BC_DIAG_DATA 2;
BA_ "GenSigSendType" SG_ 2564472032 DNT18DABCE0_DIAG_DATA 2;
BA_ "GenSigSendType" SG_ 2564481195 SNR18DAE0AB_DIAG_DATA_EXT7 2;
BA_ "GenSigSendType" SG_ 2564481195 SNR18DAE0AB_DIAG_DATA_EXT6 2;
BA_ "GenSigSendType" SG_ 2564481195 SNR18DAE0AB_DIAG_DATA_EXT5 2;
BA_ "GenSigSendType" SG_ 2564481195 SNR18DAE0AB_DIAG_DATA_EXT4 2;
BA_ "GenSigSendType" SG_ 2564481195 SNR18DAE0AB_DIAG_DATA_EXT3 2;
BA_ "GenSigSendType" SG_ 2564481195 SNR18DAE0AB_DIAG_DATA_EXT2 2;
BA_ "GenSigSendType" SG_ 2564481195 SNR18DAE0AB_DIAG_DATA_EXT1 2;
BA_ "GenSigSendType" SG_ 2564481195 SNR18DAE0AB_DIAG_DATA 2;
BA_ "GenSigSendType" SG_ 2564467680 DNT18DAABE0_DIAG_DATA_EXT7 2;
BA_ "GenSigSendType" SG_ 2564467680 DNT18DAABE0_DIAG_DATA_EXT6 2;
BA_ "GenSigSendType" SG_ 2564467680 DNT18DAABE0_DIAG_DATA_EXT5 2;
BA_ "GenSigSendType" SG_ 2564467680 DNT18DAABE0_DIAG_DATA_EXT4 2;
BA_ "GenSigSendType" SG_ 2564467680 DNT18DAABE0_DIAG_DATA_EXT3 2;
BA_ "GenSigSendType" SG_ 2564467680 DNT18DAABE0_DIAG_DATA_EXT2 2;
BA_ "GenSigSendType" SG_ 2564467680 DNT18DAABE0_DIAG_DATA_EXT1 2;
BA_ "GenSigSendType" SG_ 2564467680 DNT18DAABE0_DIAG_DATA 2;
BA_ "GenSigSendType" SG_ 2564481047 MET18DAE017_DIAG_DATA_EXT7 2;
BA_ "GenSigSendType" SG_ 2564481047 MET18DAE017_DIAG_DATA_EXT6 2;
BA_ "GenSigSendType" SG_ 2564481047 MET18DAE017_DIAG_DATA_EXT5 2;
BA_ "GenSigSendType" SG_ 2564481047 MET18DAE017_DIAG_DATA_EXT4 2;
BA_ "GenSigSendType" SG_ 2564481047 MET18DAE017_DIAG_DATA_EXT3 2;
BA_ "GenSigSendType" SG_ 2564481047 MET18DAE017_DIAG_DATA_EXT2 2;
BA_ "GenSigSendType" SG_ 2564481047 MET18DAE017_DIAG_DATA_EXT1 2;
BA_ "GenSigSendType" SG_ 2564481047 MET18DAE017_DIAG_DATA 2;
BA_ "GenSigSendType" SG_ 2564429792 DNT18DA17E0_DIAG_DATA_EXT7 2;
BA_ "GenSigSendType" SG_ 2564429792 DNT18DA17E0_DIAG_DATA_EXT6 2;
BA_ "GenSigSendType" SG_ 2564429792 DNT18DA17E0_DIAG_DATA_EXT5 2;
BA_ "GenSigSendType" SG_ 2564429792 DNT18DA17E0_DIAG_DATA_EXT4 2;
BA_ "GenSigSendType" SG_ 2564429792 DNT18DA17E0_DIAG_DATA_EXT3 2;
BA_ "GenSigSendType" SG_ 2564429792 DNT18DA17E0_DIAG_DATA_EXT2 2;
BA_ "GenSigSendType" SG_ 2564429792 DNT18DA17E0_DIAG_DATA_EXT1 2;
BA_ "GenSigSendType" SG_ 2564429792 DNT18DA17E0_DIAG_DATA 2;
BA_ "GenSigSendType" SG_ 2564550625 CECU18DBEFE1_DIAG_DATA 2;
BA_ "GenSigSendType" SG_ 2564550624 DNT18DBEFE0_DIAG_DATA 2;
BA_ "GenSigSendType" SG_ 1832 DNT728_7_0_DIAG_DATA 2;
BA_ "GenSigSendType" SG_ 1832 DNT728_2_0_DIAG_N_PCI_OR_DATA 2;
BA_ "GenSigSendType" SG_ 1832 DNT728_1_0_DIAG_N_PCI_OR_DATA 2;
BA_ "GenSigSendType" SG_ 1832 DNT728_0_0_DIAG_N_PCI 2;
BA_ "GenSigSendType" SG_ 2564481303 MET18DAE117_DIAG_DATA_EXT7 2;
BA_ "GenSigSendType" SG_ 2564481303 MET18DAE117_DIAG_DATA_EXT6 2;
BA_ "GenSigSendType" SG_ 2564481303 MET18DAE117_DIAG_DATA_EXT5 2;
BA_ "GenSigSendType" SG_ 2564481303 MET18DAE117_DIAG_DATA_EXT4 2;
BA_ "GenSigSendType" SG_ 2564481303 MET18DAE117_DIAG_DATA_EXT3 2;
BA_ "GenSigSendType" SG_ 2564481303 MET18DAE117_DIAG_DATA_EXT2 2;
BA_ "GenSigSendType" SG_ 2564481303 MET18DAE117_DIAG_DATA_EXT1 2;
BA_ "GenSigSendType" SG_ 2564481303 MET18DAE117_DIAG_DATA 2;
BA_ "GenSigSendType" SG_ 2564429793 CECU18DA17E1_DIAG_DATA_EXT7 2;
BA_ "GenSigSendType" SG_ 2564429793 CECU18DA17E1_DIAG_DATA_EXT6 2;
BA_ "GenSigSendType" SG_ 2564429793 CECU18DA17E1_DIAG_DATA_EXT5 2;
BA_ "GenSigSendType" SG_ 2564429793 CECU18DA17E1_DIAG_DATA_EXT4 2;
BA_ "GenSigSendType" SG_ 2564429793 CECU18DA17E1_DIAG_DATA_EXT3 2;
BA_ "GenSigSendType" SG_ 2564429793 CECU18DA17E1_DIAG_DATA_EXT2 2;
BA_ "GenSigSendType" SG_ 2564429793 CECU18DA17E1_DIAG_DATA_EXT1 2;
BA_ "GenSigSendType" SG_ 2564429793 CECU18DA17E1_DIAG_DATA 2;
BA_ "GenSigSendType" SG_ 2564481452 MVS18DAE1AC_DIAG_DATA_EXT7 2;
BA_ "GenSigSendType" SG_ 2564481452 MVS18DAE1AC_DIAG_DATA_EXT6 2;
BA_ "GenSigSendType" SG_ 2564481452 MVS18DAE1AC_DIAG_DATA_EXT5 2;
BA_ "GenSigSendType" SG_ 2564481452 MVS18DAE1AC_DIAG_DATA_EXT4 2;
BA_ "GenSigSendType" SG_ 2564481452 MVS18DAE1AC_DIAG_DATA_EXT3 2;
BA_ "GenSigSendType" SG_ 2564481452 MVS18DAE1AC_DIAG_DATA_EXT2 2;
BA_ "GenSigSendType" SG_ 2564481452 MVS18DAE1AC_DIAG_DATA_EXT1 2;
BA_ "GenSigSendType" SG_ 2564481452 MVS18DAE1AC_DIAG_DATA 2;
BA_ "GenSigSendType" SG_ 2564467937 CECU18DAACE1_DIAG_DATA_EXT7 2;
BA_ "GenSigSendType" SG_ 2564467937 CECU18DAACE1_DIAG_DATA_EXT6 2;
BA_ "GenSigSendType" SG_ 2564467937 CECU18DAACE1_DIAG_DATA_EXT5 2;
BA_ "GenSigSendType" SG_ 2564467937 CECU18DAACE1_DIAG_DATA_EXT4 2;
BA_ "GenSigSendType" SG_ 2564467937 CECU18DAACE1_DIAG_DATA_EXT3 2;
BA_ "GenSigSendType" SG_ 2564467937 CECU18DAACE1_DIAG_DATA_EXT2 2;
BA_ "GenSigSendType" SG_ 2564467937 CECU18DAACE1_DIAG_DATA_EXT1 2;
BA_ "GenSigSendType" SG_ 2564467937 CECU18DAACE1_DIAG_DATA 2;
BA_ "GenSigSendType" SG_ 2564481451 SNR18DAE1AB_DIAG_DATA_EXT7 2;
BA_ "GenSigSendType" SG_ 2564481451 SNR18DAE1AB_DIAG_DATA_EXT6 2;
BA_ "GenSigSendType" SG_ 2564481451 SNR18DAE1AB_DIAG_DATA_EXT5 2;
BA_ "GenSigSendType" SG_ 2564481451 SNR18DAE1AB_DIAG_DATA_EXT4 2;
BA_ "GenSigSendType" SG_ 2564481451 SNR18DAE1AB_DIAG_DATA_EXT3 2;
BA_ "GenSigSendType" SG_ 2564481451 SNR18DAE1AB_DIAG_DATA_EXT2 2;
BA_ "GenSigSendType" SG_ 2564481451 SNR18DAE1AB_DIAG_DATA_EXT1 2;
BA_ "GenSigSendType" SG_ 2564481451 SNR18DAE1AB_DIAG_DATA 2;
BA_ "GenSigSendType" SG_ 2564467681 CECU18DAABE1_DIAG_DATA_EXT7 2;
BA_ "GenSigSendType" SG_ 2564467681 CECU18DAABE1_DIAG_DATA_EXT6 2;
BA_ "GenSigSendType" SG_ 2564467681 CECU18DAABE1_DIAG_DATA_EXT5 2;
BA_ "GenSigSendType" SG_ 2564467681 CECU18DAABE1_DIAG_DATA_EXT4 2;
BA_ "GenSigSendType" SG_ 2564467681 CECU18DAABE1_DIAG_DATA_EXT3 2;
BA_ "GenSigSendType" SG_ 2564467681 CECU18DAABE1_DIAG_DATA_EXT2 2;
BA_ "GenSigSendType" SG_ 2564467681 CECU18DAABE1_DIAG_DATA_EXT1 2;
BA_ "GenSigSendType" SG_ 2564467681 CECU18DAABE1_DIAG_DATA 2;
BA_ "GenSigSendType" SG_ 2564481469 RCR18DAE1BD_DIAG_DATA 2;
BA_ "GenSigSendType" SG_ 2564472289 CECU18DABDE1_DIAG_DATA 2;
BA_ "GenSigSendType" SG_ 2564481468 RCR18DAE1BC_DIAG_DATA 2;
BA_ "GenSigSendType" SG_ 2564472033 CECU18DABCE1_DIAG_DATA 2;
BA_ "GenSigStartValue" SG_ 996 CECU3E4_6_0_CHARGE_LEVEL_ENG_RUN 3;
BA_ "GenSigStartValue" SG_ 996 CECU3E4_6_4_CHARGE_LEVEL_IGN_ON 3;
BA_ "GenSigStartValue" SG_ 1632 CGW660_1_0_SUB_ID 65535;
BA_ "GenSigStartValue" SG_ 930 MET3A2_7_0_FUEL_AMOUNT 254;
BA_ "GenSigStartValue" SG_ 1677 MET68D_5_0_TEMP_FOR_PPA 8191;
BA_ "Fhi_SignalComment" SG_ 1677 MET68D_2_0_ODO "000000h～98967Fh：正常

989680h～FFFFFEh：未使用

FFFFFFh：異常

";
BA_ "GenSigStartValue" SG_ 1676 MET68C_2_0_CRUISING_RADIUS 254;
BA_ "GenSigStartValue" SG_ 922 MET39A_5_2_AVE_FUEL_ECONOMY 1022;
BA_ "GenSigStartValue" SG_ 922 MET39A_4_0_INSTANTANEOUS_FUEL 1022;
BA_ "Fhi_SignalComment" SG_ 922 MET39A_3_1_STATUS_FUEL_LAMP "IGN_OFF時：IGN_OFF直前の値

";
BA_ "Fhi_SignalComment" SG_ 915 MET393_6_0_R_DIFF_TEMP "IGN-ON初回送信時はFEhを送信する。

";
BA_ "GenSigStartValue" SG_ 915 MET393_6_0_R_DIFF_TEMP 253;
BA_ "GenSigStartValue" SG_ 915 MET393_4_0_FUEL_LEVEL_RESIST 1022;
BA_ "Fhi_SignalComment" SG_ 915 MET393_3_5_SI_DRIVE_SW "IGN　ON時の初期値は各SIドライブとXモードの組み合わせにより異なる。

";
BA_ "GenSigStartValue" SG_ 915 MET393_2_0_OUTTEMP_FOR_DIAG 8191;
BA_ "Fhi_SignalComment" SG_ 912 MET390_6_0_SEATBELT_DRVR "IGN-OFF中は0送信

";
BA_ "Fhi_SignalComment" SG_ 912 MET390_6_1_SEATBELT_PASS "IGN-OFF中は0送信

";
BA_ "Fhi_SignalComment" SG_ 912 MET390_4_0_OUTTEMP_FOR_IND "IGN-OFF中は初期値：FEh送信

";
BA_ "GenSigStartValue" SG_ 912 MET390_4_0_OUTTEMP_FOR_IND 254;
BA_ "Fhi_SignalComment" SG_ 912 MET390_2_0_VEHICLE_SERIES "GW:ID390-B2b2~b0→ID2BE-B5b2~b0

";
BA_ "Fhi_SignalComment" SG_ 912 MET390_2_3_DESTINATION "GW:ID390-B2b6~b3→ID2BE-B5b6~b3

";
BA_ "GenSigStartValue" SG_ 914 MET392_23_0_ADD_ACNON_DRVRANG 2046;
BA_ "GenSigStartValue" SG_ 914 MET392_21_0_ADD_ACNOFF_DRVRANG 2046;
BA_ "GenSigStartValue" SG_ 914 MET392_18_0_TRIP_LASTCHG_TOTM 1048574;
BA_ "GenSigStartValue" SG_ 914 MET392_15_0_TRIPB_TOTAL_TIME 1048574;
BA_ "GenSigStartValue" SG_ 914 MET392_12_0_TRIPA_TOTAL_TIME 1048574;
BA_ "GenSigStartValue" SG_ 933 MET3A5_7_0_INSTCNSP_VAL 1022;
BA_ "GenSigStartValue" SG_ 933 MET3A5_5_0_AVEN_TRIPB_VAL 1022;
BA_ "GenSigStartValue" SG_ 933 MET3A5_3_0_AVEN_TRIPA_VAL 1022;
BA_ "GenSigStartValue" SG_ 1678 MET68E_4_2_CSTM_SHIFT 1;
BA_ "GenSigStartValue" SG_ 1678 MET68E_4_3_CSTM_WOW 1;
BA_ "GenSigStartValue" SG_ 1678 MET68E_4_4_CSTM_GBYE 1;
BA_ "GenSigStartValue" SG_ 1678 MET68E_4_6_CSTM_WLCM 1;
BA_ "GenSigStartValue" SG_ 1674 MET68A_19_0_AVSP_TRIPB_VAL 510;
BA_ "GenSigStartValue" SG_ 1674 MET68A_17_0_AVSP_TRIPA_VAL 65534;
BA_ "GenSigStartValue" SG_ 1674 MET68A_12_0_TEMPBAR_PER 254;
BA_ "GenSigStartValue" SG_ 1674 MET68A_11_0_FUELBAR_PER 254;
BA_ "GenSigStartValue" SG_ 1674 MET68A_9_0_TACHOREV_VAL 65535;
BA_ "GenSigStartValue" SG_ 1674 MET68A_6_1_CID_TONE_DOWN 31;
BA_ "GenSigStartValue" SG_ 1674 MET68A_4_2_TEMP_ICON 7;
BA_ "GenSigStartValue" SG_ 1673 MET689_9_3_REAR_REMIND_SUP 1;
BA_ "GenSigStartValue" SG_ 1673 MET689_9_5_TPMSDISP_SUP 1;
BA_ "GenSigStartValue" SG_ 1673 MET689_9_6_GSI_SUP 1;
BA_ "GenSigSendType" SG_ 1658 TPM67A_6_1_TIRE_COLOR_RR 3;
BA_ "GenSigSendType" SG_ 1658 TPM67A_6_5_TIRE_COLOR_RL 3;
BA_ "GenSigSendType" SG_ 1658 TPM67A_6_7_TIRE_PRESSURE_RL 3;
BA_ "GenSigSendType" SG_ 1658 TPM67A_5_0_TIRE_PRESSURE_RR 3;
BA_ "GenSigSendType" SG_ 1658 TPM67A_3_1_TIRE_COLOR_FL 3;
BA_ "GenSigSendType" SG_ 1658 TPM67A_3_5_TIRE_COLOR_FR 3;
BA_ "GenSigSendType" SG_ 1658 TPM67A_3_7_TIRE_PRESSURE_FR 3;
BA_ "GenSigSendType" SG_ 1658 TPM67A_2_0_TIRE_PRESSURE_FL 3;
BA_ "GenSigSendType" SG_ 1658 TPM67A_1_5_UNIT_IND_PRESSURE 3;
BA_ "GenSigSendType" SG_ 1658 TPM67A_1_7_IND_PRESSURE 3;
BA_ "GenSigSendType" SG_ 1657 TPM679_3_0_STATE_TPMS 3;
BA_ "GenSigSendType" SG_ 1657 TPM679_3_2_DEFINED_STATE_TPMS 3;
BA_ "Fhi_SignalComment" SG_ 1657 TPM679_3_2_DEFINED_STATE_TPMS "※閾値設定スイッチがタッチパネルの車は、送信値を0固定とする。

";
BA_ "GenSigSendType" SG_ 1657 TPM679_2_0_WARN_TPMS 3;
BA_ "GenSigSendType" SG_ 1657 TPM679_2_3_INTERRUPT 3;
BA_ "GenSigStartValue" SG_ 827 ABG33B_4_0_PASSENGER_BELT_INFO 2;
BA_ "GenSigStartValue" SG_ 827 ABG33B_4_2_PASSENGER_DETECT_INFO 4;
BA_ "GenSigStartValue" SG_ 827 ABG33B_2_0_IND_WARN_PPA 3;
BA_ "GenSigStartValue" SG_ 826 ABG33A_3_0_BELT_WRNING_PASS 2;
BA_ "GenSigStartValue" SG_ 826 ABG33A_3_4_OCCUPATION_PASS 2;
BA_ "GenSigStartValue" SG_ 826 ABG33A_2_0_IND_WARN_ABG 3;
BA_ "GenSigStartValue" SG_ 961 DMS3C1_6_2_PERMIT_AVN_FLAG 1;
BA_ "GenSigStartValue" SG_ 961 DMS3C1_6_7_NOT_DETECTED_STATUS 1;
BA_ "GenSigStartValue" SG_ 961 DMS3C1_4_0_DMS_IND_REQ_FLAG 7;
BA_ "GenSigStartValue" SG_ 961 DMS3C1_4_3_DMS_RECOG_STATUS 1;
BA_ "GenSigStartValue" SG_ 1724 AVN6BC_1_4_GNSS_STATUS 1;
BA_ "GenSigStartValue" SG_ 1723 AVN6BB_7_0_ISA_IACC_OFFSET_CSTM 10;
BA_ "GenSigSendType" SG_ 1722 AVN6BA_7_0_GUIDE_LINE_REAR 4;
BA_ "GenSigSendType" SG_ 1722 AVN6BA_7_1_GUIDE_LINE_SIDE 4;
BA_ "GenSigSendType" SG_ 1722 AVN6BA_7_2_GUIDE_LINE_FRONT 4;
BA_ "GenSigSendType" SG_ 1722 AVN6BA_7_3_STEER_ANGLE_INTERLOCK 4;
BA_ "GenSigSendType" SG_ 1722 AVN6BA_7_4_BACK_CAMERA_DELAY 4;
BA_ "GenSigSendType" SG_ 1722 AVN6BA_7_5_REQ_STOP_CAMERA_OUT 4;
BA_ "GenSigSendType" SG_ 1722 AVN6BA_7_6_VIEW_CHANGE_SW 4;
BA_ "GenSigSendType" SG_ 1722 AVN6BA_6_0_CLIMAITE_PA_TEMP 4;
BA_ "Fhi_SignalComment" SG_ 1722 AVN6BA_6_0_CLIMAITE_PA_TEMP "分解能、ｵﾌｾｯﾄは摂氏時の値。華氏の場合はﾃﾞｰﾀｼｰﾄ参照。

";
BA_ "GenSigStartValue" SG_ 1722 AVN6BA_6_0_CLIMAITE_PA_TEMP 63;
BA_ "GenSigSendType" SG_ 1722 AVN6BA_6_6_CLIMATE_SYNC 4;
BA_ "GenSigSendType" SG_ 1722 AVN6BA_6_7_CLIMATE_F_DEF 4;
BA_ "GenSigSendType" SG_ 1722 AVN6BA_5_0_CLIMAITE_DR_TEMP 4;
BA_ "Fhi_SignalComment" SG_ 1722 AVN6BA_5_0_CLIMAITE_DR_TEMP "分解能、ｵﾌｾｯﾄは摂氏時の値。華氏の場合はﾃﾞｰﾀｼｰﾄ参照。

";
BA_ "GenSigSendType" SG_ 1722 AVN6BA_5_6_CLIMAITE_AUTO 4;
BA_ "GenSigSendType" SG_ 1722 AVN6BA_5_7_CLIMAITE_MAX_AC 4;
BA_ "GenSigSendType" SG_ 1722 AVN6BA_4_0_CLIMAITE_VR 4;
BA_ "GenSigSendType" SG_ 1722 AVN6BA_4_3_CLIMATE_AC 4;
BA_ "GenSigSendType" SG_ 1722 AVN6BA_4_4_CLIMAITE_FAN 4;
BA_ "GenSigSendType" SG_ 1722 AVN6BA_3_0_PERSONAL_IC_SH 4;
BA_ "GenSigSendType" SG_ 1722 AVN6BA_3_4_CSTM_SONNER 4;
BA_ "GenSigSendType" SG_ 1722 AVN6BA_3_5_CSTM_RAB 4;
BA_ "GenSigSendType" SG_ 1722 AVN6BA_3_6_REQ_CHG_CSTM_RAB 4;
BA_ "GenSigSendType" SG_ 1722 AVN6BA_3_7_CLIMATE_R_DEF 4;
BA_ "GenSigSendType" SG_ 1722 AVN6BA_2_0_CLIMATE_PTC 4;
BA_ "GenSigSendType" SG_ 1722 AVN6BA_2_1_CLIMATE_MODE 4;
BA_ "GenSigSendType" SG_ 1722 AVN6BA_2_2_CLIMATE_SEAT_C_L 4;
BA_ "GenSigSendType" SG_ 1722 AVN6BA_2_3_CLIMATE_SEAT_C_R 4;
BA_ "GenSigSendType" SG_ 1722 AVN6BA_2_4_CLIMATE_SEAT_H_L 4;
BA_ "GenSigSendType" SG_ 1722 AVN6BA_2_5_CLIMATE_SEAT_H_R 4;
BA_ "GenSigSendType" SG_ 1722 AVN6BA_2_6_CLIMATE_INNER_AIR 4;
BA_ "GenSigSendType" SG_ 1722 AVN6BA_2_7_CLIMATE_ON_OFF 4;
BA_ "GenSigSendType" SG_ 1722 AVN6BA_1_4_CLIMAITE_STATUS 4;
BA_ "GenSigSendType" SG_ 1722 AVN6BA_1_7_CLIMAITE_ON_OFF 4;
BA_ "GenSigStartValue" SG_ 1713 AVN6B1_7_1_PRESENT_YEAR 127;
BA_ "GenSigStartValue" SG_ 1713 AVN6B1_4_0_PRESENT_TIME_SEC 60;
BA_ "GenSigStartValue" SG_ 1713 AVN6B1_3_0_PRESENT_TIME_MIN 60;
BA_ "GenSigStartValue" SG_ 1713 AVN6B1_2_1_PRESENT_TIME_HOUR 30;
VAL_ 1774 CECU6EE_7_0_DESTINATION_INFO 3 "EUROPE_LH" 2 "EUROPE_RH" 1 "DOMESTIC" 0 "US_CANADA" ;
VAL_ 1774 CECU6EE_7_4_VEHICLE_SERIES 7 "NON" 6 "VEHICLE_W" 5 "VEHICLE_V" 4 "VEHICLE_Z" 3 "VEHICLE_S" 2 "VEHICLE_G" 1 "VEHICLE_B" 0 "DEFAULT" ;
VAL_ 1774 CECU6EE_6_0_DESTINATION_CODE 37 "NON" 36 "KR" 35 "KF" 34 "K2" 33 "C6" 32 "U7" 31 "E5" 30 "KG" 29 "E1" 28 "KE" 27 "KP" 26 "EH" 25 "E9" 24 "C4" 23 "KC" 22 "KV" 21 "KY" 20 "KA" 19 "EN" 18 "ER" 17 "EP" 16 "KS" 15 "K4" 14 "E3" 13 "EA" 12 "E7" 11 "ES" 10 "E2" 9 "EE" 8 "EK" 7 "C5" 6 "U5" 5 "EC" 4 "CO" 3 "U4" 2 "JPN" 1 "NON" 0 "DEFAULT" ;
VAL_ 1774 CECU6EE_5_0_EYE_VERSION_INFO 3 "VER4_HEIGHT_DRIVING_ASSIST" 2 "VER4" 1 "NO_EYE" 0 "DEFAULT" ;
VAL_ 1774 CECU6EE_5_4_VEHICLE_TYPE 1 "WGN" 0 "SDN" ;
VAL_ 1774 CECU6EE_5_6_PRODUCTION_BASE 1 "SIA" 0 "DOMESTIC" ;
VAL_ 1774 CECU6EE_4_2_WHEEL_DRIVE_TYPE 1 "4WD" 0 "FF" ;
VAL_ 1774 CECU6EE_4_3_3RD_SHEAT_EQUIPMENT 1 "EQUIPPED" 0 "NO_EQUIPPED" ;
VAL_ 1774 CECU6EE_4_4_FLG_XMODE 3 "X_MODE_2_MODE" 2 "X_MODE_1_MODE" 1 "NO_X_MODE" 0 "DEFAULT" ;
VAL_ 1774 CECU6EE_4_6_ISS_EQUIPMENT 1 "EQUIPPED" 0 "NO_EQUIPPED" ;
VAL_ 1773 CECU6ED_7_0_VEHICLE_TYPE_DETAIL 15 "NON" 14 "NON" 13 "NON" 12 "NON" 11 "NON" 10 "NON" 9 "NON" 8 "NON" 7 "COUPE" 6 "3RD_ROW_SUV" 5 "XUV" 4 "5D" 3 "OUTBACK" 2 "WGN" 1 "SD" 0 "DEFAULT" ;
VAL_ 1773 CECU6ED_5_0_TRANSMISSION_TYPE 1 "MT" 0 "CVT" ;
VAL_ 1773 CECU6ED_5_4_HANDLE 1 "RHD" 0 "LHD" ;
VAL_ 1773 CECU6ED_4_0_VEHICLE_HEIGHT 7 "NON" 6 "LIFT4" 5 "LIFT3" 4 "LIFT2" 3 "Wilderness" 2 "LIFT" 1 "STANDARD" 0 "DEFAULT" ;
VAL_ 1773 CECU6ED_4_4_SEATHEATER_EQUIPMENT 3 "SEAT_HEATER_D_P_REAR" 2 "SEAT_HEATER_D_P" 1 "NOT_SEAT_HEATER" 0 "DEFAULT" ;
VAL_ 1773 CECU6ED_3_0_YEAR_CHANGE 15 "NON" 14 "NON" 13 "NON" 12 "NON" 11 "NON" 10 "9" 9 "8" 8 "7" 7 "6" 6 "5" 5 "4" 4 "3" 3 "2" 2 "1" 1 "0" 0 "DEFAULT" ;
VAL_ 1773 CECU6ED_3_4_HEV_INFO 7 "NON" 6 "NON" 5 "BEV" 4 "SHEV" 3 "MHEV" 2 "PHEV" 1 "CONVE" 0 "DEFAULT" ;
VAL_ 1772 CECU6EC_6_0_SMT_EQUIPMENT 1 "EQUIPPED" 0 "NO_EQUIPPED" ;
VAL_ 1772 CECU6EC_6_1_DCCD_EQUIPMENT 1 "EQUIPPED" 0 "NO_EQUIPPED" ;
VAL_ 1772 CECU6EC_5_0_CCU_EQUIPMENT 1 "EQUIPPED" 0 "NO_EQUIPPED" ;
VAL_ 1772 CECU6EC_5_1_EAM_EQUIPMENT 1 "EQUIPPED" 0 "NO_EQUIPPED" ;
VAL_ 1772 CECU6EC_5_2_RCR_L_EQUIPMENT 1 "EQUIPPED" 0 "NO_EQUIPPED" ;
VAL_ 1772 CECU6EC_5_3_RCR_R_EQUIPMENT 1 "EQUIPPED" 0 "NO_EQUIPPED" ;
VAL_ 1772 CECU6EC_5_4_FCR_L_EQUIPMENT 1 "EQUIPPED" 0 "NO_EQUIPPED" ;
VAL_ 1772 CECU6EC_5_5_FCR_R_EQUIPMENT 1 "EQUIPPED" 0 "NO_EQUIPPED" ;
VAL_ 1772 CECU6EC_5_6_VSS_EQUIPMENT 1 "EQUIPPED" 0 "NO_EQUIPPED" ;
VAL_ 1772 CECU6EC_5_7_RES_EQUIPMENT 1 "EQUIPPED" 0 "NO_EQUIPPED" ;
VAL_ 1772 CECU6EC_4_0_LCT_EQUIPMENT 1 "EQUIPPED" 0 "NO_EQUIPPED" ;
VAL_ 1772 CECU6EC_4_1_DAM_EQUIPMENT 1 "EQUIPPED" 0 "NO_EQUIPPED" ;
VAL_ 1772 CECU6EC_4_2_MVS_EQUIPMENT 1 "EQUIPPED" 0 "NO_EQUIPPED" ;
VAL_ 1772 CECU6EC_4_3_TCU_EQUIPMENT 1 "EQUIPPED" 0 "NO_EQUIPPED" ;
VAL_ 1772 CECU6EC_4_4_TPM_EQUIPMENT 1 "EQUIPPED" 0 "NO_EQUIPPED" ;
VAL_ 1772 CECU6EC_4_5_DCM_EQUIPMENT 1 "EQUIPPED" 0 "NO_EQUIPPED" ;
VAL_ 1772 CECU6EC_4_6_MED_EQUIPMENT 1 "EQUIPPED" 0 "NO_EQUIPPED" ;
VAL_ 1772 CECU6EC_4_7_MEP_EQUIPMENT 1 "EQUIPPED" 0 "NO_EQUIPPED" ;
VAL_ 1772 CECU6EC_3_0_DATA_STATE 1 "ABNORMAL" 0 "NORMAL" ;
VAL_ 1772 CECU6EC_3_1_EYE_EQUIPMENT 1 "EQUIPPED" 0 "NO_EQUIPPED" ;
VAL_ 1772 CECU6EC_3_2_HEV_EQUIPMENT 1 "EQUIPPED" 0 "NO_EQUIPPED" ;
VAL_ 1772 CECU6EC_3_3_SNR_EQUIPMENT 1 "EQUIPPED" 0 "NO_EQUIPPED" ;
VAL_ 1772 CECU6EC_3_4_EPB_EQUIPMENT 1 "EQUIPPED" 0 "NO_EQUIPPED" ;
VAL_ 1772 CECU6EC_3_5_DMS_EQUIPMENT 1 "EQUIPPED" 0 "NO_EQUIPPED" ;
VAL_ 1772 CECU6EC_3_6_BST_EQUIPMENT 1 "EQUIPPED" 0 "NO_EQUIPPED" ;
VAL_ 1772 CECU6EC_3_7_MCA_EQUIPMENT 1 "EQUIPPED" 0 "NO_EQUIPPED" ;
VAL_ 996 CECU3E4_7_0_SSM_COMM_INFO 1 "COMM_ON" 0 "COMM_OFF" ;
VAL_ 996 CECU3E4_6_0_CHARGE_LEVEL_ENG_RUN 9 "level10" 8 "level9" 7 "level8" 6 "level7" 5 "level6" 4 "level5" 3 "level4" 2 "level3" 1 "level2" 0 "level1" ;
VAL_ 996 CECU3E4_6_4_CHARGE_LEVEL_IGN_ON 9 "level10" 8 "level9" 7 "level8" 6 "level7" 5 "level6" 4 "level5" 3 "level4" 2 "level3" 1 "level2" 0 "level1" ;
VAL_ 996 CECU3E4_5_0_GENERATOR_OVER_FLG 3 "EvLoadRestrain2" 2 "EvLoadRestrain1" 1 "Overloaded" 0 "NormalState" ;
VAL_ 996 CECU3E4_5_3_DIAG_COM_REQ 1 "Diag_Com_Request" 0 "No_Request" ;
VAL_ 996 CECU3E4_5_4_HEADS_UP_FLG 1 "ChargeRequest" 0 "Normal" ;
VAL_ 996 CECU3E4_2_7_OCCUPATION_CSTM 1 "D_SEAT" 0 "ALL_SEATS" ;
VAL_ 1280 CGW500_1_4_ActiveWakeUpBit 1 "active wakeup" 0 "passive wakeup" ;
VAL_ 1632 CGW660_1_0_SUB_ID 65535 "NORMAL" ;
VAL_ 1752 DCM6D8_1_4_PRESS_SOS_BUTTON 1 "ON" 0 "OFF" ;
VAL_ 1744 CECU6D0_4_0_OTA_ABORT 1 "OTA中止" 0 "OTA中止でない" ;
VAL_ 1744 CECU6D0_4_1_OTA_SUSPEND 1 "OTA中断" 0 "OTA中断でない" ;
VAL_ 1744 CECU6D0_4_2_OTA_SEQUENCE 33170 "予備" 16534 "予備" 8264 "Campaignなし" 4132 "OTA完了" 1298 "SWID照合中" 598 "電源ON待ち" 296 "電源OFF待ち" 100 "Activate中(Dual)" 50 "Install中(Single)" 22 "アップデート適用開始待ち" 8 "アップデート適用承諾待ち" 4 "Install中(Dual)" 2 "Download中" 1 "Campaign情報取得中" 0 "未実施" ;
VAL_ 1749 CECU6D5_6_0_CSTM_FMHD 7 "Undefined" 6 "Undefined" 5 "90sec" 4 "60sec" 3 "30sec" 2 "20sec" 1 "10sec" 0 "OFF" ;
VAL_ 1749 CECU6D5_5_0_CSTM_WRH 1 "ON" 0 "OFF" ;
VAL_ 1749 CECU6D5_5_1_CSTM_LMHD 3 "30sec" 2 "20sec" 1 "10sec" 0 "OFF" ;
VAL_ 1749 CECU6D5_5_5_CSTM_HBA 3 "Undefined" 2 "Undefined" 1 "ON" 0 "OFF" ;
VAL_ 1749 CECU6D5_5_7_ADB_ACTIVE 1 "ON" 0 "OFF" ;
VAL_ 1749 CECU6D5_4_0_JUDGE_ILL 1 "YES" 0 "NO" ;
VAL_ 1749 CECU6D5_4_1_HEADLAMP_AUTO_SW 1 "ON" 0 "OFF" ;
VAL_ 1749 CECU6D5_4_2_IND_ACTIVE_HBA 3 "Undefined" 2 "Blink" 1 "ON" 0 "OFF" ;
VAL_ 1749 CECU6D5_4_4_FGT_LGTOFF_WARNING 1 "ON" 0 "OFF" ;
VAL_ 1749 CECU6D5_3_0_CRN_R_REQ 3 "Undefined" 2 "ON" 1 "Faded OFF" 0 "OFF" ;
VAL_ 1749 CECU6D5_3_2_CRN_L_REQ 3 "Undefined" 2 "ON" 1 "Faded OFF" 0 "OFF" ;
VAL_ 1749 CECU6D5_3_4_FMH 1 "ON" 0 "OFF" ;
VAL_ 1749 CECU6D5_3_5_LMH 1 "ON" 0 "OFF" ;
VAL_ 1749 CECU6D5_2_0_LGT_1 1 "ON" 0 "OFF" ;
VAL_ 1749 CECU6D5_2_1_LGT_LO 1 "ON" 0 "OFF" ;
VAL_ 1749 CECU6D5_2_2_LGT_HI 1 "ON" 0 "OFF" ;
VAL_ 1749 CECU6D5_2_4_FFOG_RELAY_REQ 1 "ON" 0 "OFF" ;
VAL_ 1749 CECU6D5_2_5_RFOG_RELAY_REQ 1 "ON" 0 "OFF" ;
VAL_ 1749 CECU6D5_2_6_LGT_DRL 1 "ON" 0 "OFF" ;
VAL_ 1705 MVS6A9_6_0_CSTM_HITCHLINE_DSPREQ 3 "Reserved" 2 "Disp(Gray out)" 1 "Disp(Normal)" 0 "No Disp" ;
VAL_ 1705 MVS6A9_6_2_CSTM_HITCHLINE 1 "ON" 0 "OFF" ;
VAL_ 1705 MVS6A9_5_0_RR_WIDE_VIEW_SW_STATE 3 "Reserved" 2 "Selected" 1 "Not Selectable" 0 "Selectable" ;
VAL_ 1705 MVS6A9_5_2_RR_NRW_VIEW_SW_STATE 3 "Reserved" 2 "Selected" 1 "Not Selectable" 0 "Selectable" ;
VAL_ 1705 MVS6A9_5_4_HITCH_VIEW_SW_STATE 3 "Reserved" 2 "Selected" 1 "Not Selectable" 0 "Selectable" ;
VAL_ 1705 MVS6A9_4_0_FT_NRW_VIEW_SW_STATE 3 "Reserved" 2 "Selected" 1 "Not Selectable" 0 "Selectable" ;
VAL_ 1705 MVS6A9_4_2_FT_WIDE_VIEW_SW_STATE 3 "Reserved" 2 "Selected" 1 "Not Selectable" 0 "Selectable" ;
VAL_ 1705 MVS6A9_4_4_SIDE_VIEW_SW_STATE 3 "Reserved" 2 "Selected" 1 "Not Selectable" 0 "Selectable" ;
VAL_ 1705 MVS6A9_4_6_3D_VIEW_SW_STATE 3 "Reserved" 2 "Selected" 1 "Not Selectable" 0 "Selectable" ;
VAL_ 1705 MVS6A9_3_0_CSTM_AUTO_DISPLAY_SET 1 "Apply" 0 "No_Apply" ;
VAL_ 1705 MVS6A9_3_1_CSTM_AUTO_DISPLAY 1 "ON" 0 "OFF" ;
VAL_ 1705 MVS6A9_3_2_VIEW_MODE 3 "Other Mode" 2 "Parking Mode" 1 "Forward Mode" 0 "Backward Mode" ;
VAL_ 1705 MVS6A9_3_5_STOP_SWITCH 1 "Enable" 0 "Disable" ;
VAL_ 1705 MVS6A9_3_6_CSTM_HITCH_VIEW 1 "Available" 0 "Not Available" ;
VAL_ 1705 MVS6A9_2_0_CURRENT_VIEW 31 "Reserved" 30 "Reserved" 29 "Reserved" 28 "Reserved" 27 "Reserved" 26 "Reserved" 25 "Hitch Ball View" 24 "Top+3D View (FRONT)" 23 "Top View+Side and Side View" 22 "Top View+Front Narrow" 21 "Top View+Front Wide" 20 "Top View+Rear Narrow" 19 "Top View+Rear Wide" 18 "Left Side View Corresponded Regulation (reverse)" 17 "Left Side View Corresponded Regulation (Forward)" 16 "Top View (REAR)" 15 "3D Bird's View" 14 "Top and Rear View (RIGHT)" 13 "Top and Rear View (LEFT)" 12 "Top and Front View (RIGHT)" 11 "Top and Front View (LEFT)" 10 "Top View (FRONT)" 9 "Side and Side View" 8 "Front View and Side View (RIGHT)" 7 "Front View and Side View (LEFT)" 6 "Rear View and Side View (RIGHT)" 5 "Rear View and Side View (LEFT)" 4 "Side View (RIGHT)" 3 "Side View (LEFT)" 2 "Front View" 1 "Rear View" 0 "Black Display" ;
VAL_ 1705 MVS6A9_2_5_HOLD_TIME 1 "Short" 0 "Long" ;
VAL_ 1705 MVS6A9_1_4_FAIL_MVS 1 "FAIL" 0 "NORMAL" ;
VAL_ 1705 MVS6A9_1_5_FAIL_MVS_CAUSE 7 "No_Definition" 6 "No_Definition" 5 "No_Definition" 4 "EYE-MVS_CAN" 3 "Switch" 2 "Front_Camera" 1 "MVS" 0 "NORMAL" ;
VAL_ 930 MET3A2_6_0_SEATBELT_RR_RH 1 "ON_BeltOFF" 0 "OFF_BeltON" ;
VAL_ 930 MET3A2_6_1_SEATBELT_RR_CTR 1 "ON_BeltOFF" 0 "OFF_BeltON" ;
VAL_ 930 MET3A2_6_2_SEATBELT_RR_LH 1 "ON_BeltOFF" 0 "OFF_BeltON" ;
VAL_ 930 MET3A2_6_3_SEATBELT_THIRD_RH 1 "ON_BeltOFF" 0 "OFF_BeltON" ;
VAL_ 930 MET3A2_6_4_SEATBELT_THIRD_CTR 1 "ON_BeltOFF" 0 "OFF_BeltON" ;
VAL_ 930 MET3A2_6_5_SEATBELT_THIRD_LH 1 "ON_BeltOFF" 0 "OFF_BeltON" ;
VAL_ 930 MET3A2_5_0_FLG_RR_REMINDER 1 "REAR REMINDER ON" 0 "OFF" ;
VAL_ 930 MET3A2_1_4_FAIL_DISP 3 "Reserve" 2 "Reserve" 1 "MET_FAIL_DISP" 0 "NORMAL" ;
VAL_ 1677 MET68D_7_0_STATUS_WASHER_LAMP 1 "ON" 0 "OFF" ;
VAL_ 1677 MET68D_7_1_OILPRESSURE_SW 1 "SW_GND" 0 "SW_OPEN" ;
VAL_ 1677 MET68D_7_2_FLG_EAM 1 "EAM" 0 "NOT_EAM" ;
VAL_ 1677 MET68D_7_3_CSTM_IND_RED 1 "ON" 0 "OFF" ;
VAL_ 1677 MET68D_7_4_CSTM_IND_YELLOW 1 "ON" 0 "OFF" ;
VAL_ 1677 MET68D_7_5_CSTM_IND_GREEN 1 "ON" 0 "OFF" ;
VAL_ 1677 MET68D_7_6_REQ_CSTM_SRH 1 "required" 0 "NOT required" ;
VAL_ 1677 MET68D_7_7_CSTM_SRH 1 "ON" 0 "OFF" ;
VAL_ 1677 MET68D_6_5_REQ_CHG_CSTM_RAB 1 "required" 0 "NOT required" ;
VAL_ 1677 MET68D_6_6_CSTM_RAB 1 "ON" 0 "OFF" ;
VAL_ 1677 MET68D_6_7_CSTM_SONNER 1 "ON" 0 "OFF" ;
VAL_ 1677 MET68D_1_4_RESET_CSTM_TPMS_RAEB 1 "REQUIRED" 0 "NOT REQUIRED" ;
VAL_ 1677 MET68D_1_5_REQ_CHG_CSTM_TPMS 1 "required" 0 "NOT required" ;
VAL_ 1677 MET68D_1_6_CSTM_TIRE_UNIT 3 "未定義" 2 "bar" 1 "kPa" 0 "psi" ;
VAL_ 1676 MET68C_7_0_CSTM_OUTTEMP 15 "NONE" 14 "NONE" 13 "-5" 12 "-4" 11 "-3" 10 "-2" 9 "-1" 8 "-0" 7 "NONE" 6 "NONE" 5 "+5" 4 "+4" 3 "+3" 2 "+2" 1 "+1" 0 "+0" ;
VAL_ 1676 MET68C_4_6_UNIT_DEGREE 3 "reserved" 2 "deg F" 1 "deg C" 0 "Invalid" ;
VAL_ 1676 MET68C_3_0_MET_SW_STATE 3 "▼SW ON" 2 "i/SET SW ON" 1 "▲ SW ON" 0 "no SW input" ;
VAL_ 1676 MET68C_3_3_PERMIT_MFD_CSTM 1 "OK" 0 "NG" ;
VAL_ 1676 MET68C_3_5_FLG_RR_AC_PANEL 1 "REAR_AC_PANEL" 0 "NOT_REAR_AC_PANEL" ;
VAL_ 1676 MET68C_3_6_FLG_SEAT_VENT 1 "SEAT_VENT" 0 "NOT_SEAT_VENT" ;
VAL_ 1676 MET68C_3_7_FLG_SEAT_HEAT 1 "SEAT_HEATER" 0 "NOT_SEAT_HEATER" ;
VAL_ 1676 MET68C_1_4_CSTM_HU 1 "with HU" 0 "without HU" ;
VAL_ 1676 MET68C_1_5_CSTM_BRAND_NAME 1 "SBR" 0 "TMC" ;
VAL_ 922 MET39A_7_0_SET_LANGUAGE 21 "Norsk" 20 "Svenska" 19 "Dansk" 18 "Suomi" 17 "Ελληνικ?" 16 "Polski" 15 "Укра?нська" 14 "Turkce" 13 "Magyar" 12 "Ceske" 11 "Slovensky" 10 "Romana" 9 "China" 8 "Русский" 7 "Francais" 6 "Deutsh" 5 "Nederlands" 4 "Espanol" 3 "Portuges" 2 "Italiano" 1 "English" 0 "Japanese" ;
VAL_ 922 MET39A_7_5_ACTIVE_MET_CSTM 1 "ACTIVE" 0 "PASSIVE" ;
VAL_ 922 MET39A_7_6_MFD_SPEC 1 "color MFD" 0 "segment MFD" ;
VAL_ 922 MET39A_7_7_ICY_ROAD_SURFACE 2 "ON" 1 "OFF" ;
VAL_ 922 MET39A_6_4_STATUS_TRIP_A_B 1 "TRIP_B" 0 "TRIP_A" ;
VAL_ 922 MET39A_3_1_STATUS_FUEL_LAMP 3 "BLINK_SHORT/OPEN" 2 "TURN_ON_LFW" 1 "INITIAL_CHECK" 0 "TURN_OFF" ;
VAL_ 922 MET39A_3_3_TRANSIT_TIME 1 "1H" 0 "OFF" ;
VAL_ 922 MET39A_1_4_SET_UNIT_OF_FUEL 3 "MPG(英国ｶﾞﾛﾝ)" 2 "MPG(米国ｶﾞﾛﾝ)" 1 "l/100km" 0 "km/ｌ" ;
VAL_ 922 MET39A_1_6_WELCOME_TRIG 2 "ON" 1 "OFF" ;
VAL_ 922 MET39A_1_7_METER_DISPLAY_TYPE 2 "color TFT" 1 "segment LCD" ;
VAL_ 915 MET393_7_0_REQ_CHG_CSTM_EYE 1 "required" 0 "NOT required" ;
VAL_ 915 MET393_7_1_REQ_RESET_CSTM_EYE 1 "REQUIRED" 0 "NOT REQUIRED" ;
VAL_ 915 MET393_7_2_CSTM_ALK 1 "ON" 0 "OFF" ;
VAL_ 915 MET393_7_3_CSTM_HBA 1 "SAE_Mode" 0 "Normal" ;
VAL_ 915 MET393_7_4_CSTM_MIS_AT_BACK 3 "ON_FAST" 2 "ON_MIDDLE" 1 "ON_SLOW" 0 "OFF" ;
VAL_ 915 MET393_7_6_CSTM_ACC_CONT 3 "LEV4" 2 "LEV3" 1 "LEV2" 0 "LEV1" ;
VAL_ 915 MET393_5_2_WARN_R_DIFF_TEMP 3 "Turn_ON_Initial_Check" 2 "BLINK" 1 "Turn_ON" 0 "Turn_OFF" ;
VAL_ 915 MET393_5_4_ADAPTIVECC_NOALIVE 1 "NO_ALIVE" 0 "ALIVE" ;
VAL_ 915 MET393_5_5_DUAL_RANGE_LO 1 "SW GND" 0 "SW OPEN" ;
VAL_ 915 MET393_5_6_CSTM_SPD_LIMITER 1 "Control_ON" 0 "Control_OFF" ;
VAL_ 915 MET393_5_7_CSTM_LANE_CONT 1 "LEFT" 0 "RIGHT" ;
VAL_ 915 MET393_3_5_SI_DRIVE_SW 7 "BLANK_NoInput" 6 "I_Input" 5 "ECO-C_Input" 4 "I_Input" 3 "X_MUD_SAND_or_GRAVEL_Input" 2 "S#_Input" 1 "X_SNOW_DIRT_Input" 0 "BLANK_NoInput" ;
VAL_ 915 MET393_1_4_CSTM_IND_BLUE 1 "ON" 0 "OFF" ;
VAL_ 915 MET393_1_5_CSTM_AES_CONT 1 "ON" 0 "OFF" ;
VAL_ 915 MET393_1_6_FLG_PEDESTRIAN_AIRBAG 1 "OEDESTRIAN AIRBAG" 0 "OTHER" ;
VAL_ 912 MET390_7_0_VDC_ON_OFF 3 "BLANK_NoInput" 2 "VDC ON_Input" 1 "VDC OFF_Input" 0 "Neutral" ;
VAL_ 912 MET390_7_2_RR_DOOR_RECORD_L 1 "OPEN" 0 "CLOSE" ;
VAL_ 912 MET390_7_3_RR_DOOR_RECORD_R 1 "OPEN" 0 "CLOSE" ;
VAL_ 912 MET390_7_4_REQ_CHG_CSTM_PSM 1 "required" 0 "NOT required" ;
VAL_ 912 MET390_7_5_REQ_RESET_CSTM_PSM 1 "REQUIRED" 0 "NOT　REQUIRED" ;
VAL_ 912 MET390_7_6_CSTM_MIR_AFOLD_CONT 1 "ON" 0 "OFF" ;
VAL_ 912 MET390_7_7_CSTM_MIR_RTILT_CONT 1 "ON" 0 "OFF" ;
VAL_ 912 MET390_6_0_SEATBELT_DRVR 1 "ON" 0 "OFF" ;
VAL_ 912 MET390_6_1_SEATBELT_PASS 1 "ON" 0 "OFF" ;
VAL_ 912 MET390_6_2_TURN_SIG_LEFT 1 "Turn_L_OutPut" 0 "OFF" ;
VAL_ 912 MET390_6_3_TURN_SIG_RIGHT 1 "Turn_R_OutPut" 0 "OFF" ;
VAL_ 912 MET390_6_4_BRIGHT_SW 1 "ON" 0 "OFF" ;
VAL_ 912 MET390_6_5_FAIL_UART_WA_BOX 1 "FAIL" 0 "NORMAL" ;
VAL_ 912 MET390_6_6_ISS_OFF_SW 1 "While SW is being pushed down." 0 "While SW is not being pushed down." ;
VAL_ 912 MET390_6_7_FLG_DMS 1 "DMS" 0 "NOT_DMS" ;
VAL_ 912 MET390_3_0_UNIT_SPEED_TRIP 1 "MPH、miles" 0 "km/h、km" ;
VAL_ 912 MET390_3_1_FLG_EYESIGHT 1 "EYESIGHT" 0 "OTHER" ;
VAL_ 912 MET390_3_2_FLG_ISS 1 "ISS" 0 "OTHER" ;
VAL_ 912 MET390_3_3_FLG_HEV 1 "HEV" 0 "OTHER" ;
VAL_ 912 MET390_3_4_FLG_IMB 1 "IMB_ACTIVE" 0 "NON_IMB" ;
VAL_ 912 MET390_3_5_TIRE_SIZE 1 "SPECIAL_SIZE" 0 "STANDARD_SIZE" ;
VAL_ 912 MET390_3_6_FLG_XMODE 3 "X_2MODE(GRAVEL)" 2 "X_2MODE" 1 "X_1MODE" 0 "NOT_X" ;
VAL_ 912 MET390_2_0_VEHICLE_SERIES 7 "VEHICLE_Z" 6 "VEHICLE_W" 5 "VEHICLE_V" 4 "VEHICLE_B" 3 "VEHICLE_Y" 2 "VEHICLE_S" 1 "VEHICLE_G" 0 "NON" ;
VAL_ 912 MET390_2_3_DESTINATION 12 "KC" 11 "Korea_C6" 10 "China_EHETES" 9 "Australia_KA" 8 "Singapore_ERENKYKEKVKP" 7 "England_EK" 6 "SaudiArabia_KSKG" 5 "STANDARD_LH_K4E3E5C4" 4 "Europe_LH_ECEAE2EEEPE9E7E1" 3 "CANADA_C5C0" 2 "US_U4U5U6" 1 "DOM" 0 "NON" ;
VAL_ 912 MET390_2_7_PASS_DOOR_RECORD 1 "OPEN" 0 "CLOSE" ;
VAL_ 912 MET390_1_4_WAKE_UP_FRAME 1 "WakeUP_FRAME" 0 "Normal_FRAME" ;
VAL_ 912 MET390_1_5_REQ_COMM_CONT 1 "REQ" 0 "NON_REQ" ;
VAL_ 912 MET390_1_6_DMS_ID_SET 1 "REQUIRED" 0 "NOT REQUIRED" ;
VAL_ 912 MET390_1_7_FAIL_EEPROM 1 "FAIL" 0 "NORMAL" ;
VAL_ 1291 MET50B_1_4_ActiveWakeUpBit 1 "active wakeup" 0 "passive wakeup" ;
VAL_ 914 MET392_8_2_TRIPB_RESET 1 "RESET" 0 "NOT_RESET" ;
VAL_ 914 MET392_5_2_TRIPA_RESET 1 "RESET" 0 "NOT_RESET" ;
VAL_ 937 MET3A9_3_5_DAY_NIGHT_STATE 1 "Night" 0 "Day" ;
VAL_ 937 MET3A9_3_0_ILL_LEVEL 21 "STEP_21" 20 "STEP_20" 19 "STEP_19" 18 "STEP_18" 17 "STEP_17" 16 "STEP_16" 15 "STEP_15" 14 "STEP_14" 13 "STEP_13" 12 "STEP_12" 11 "STEP_11" 10 "STEP_10" 9 "STEP_9" 8 "STEP_8" 7 "STEP_7" 6 "STEP_6" 5 "STEP_5" 4 "STEP_4" 3 "STEP_3" 2 "STEP_2" 1 "STEP_1" 0 "Not_required" ;
VAL_ 937 MET3A9_1_7_BRIGHT_STATE 1 "ON" 0 "OFF" ;
VAL_ 937 MET3A9_1_6_UI_THEME_STATE 1 "Night" 0 "Day" ;
VAL_ 1679 MET68F_3_0_DOWNSW_STS 1 "DOWNSW_ON" 0 "DOWNSW_OFF" ;
VAL_ 1679 MET68F_3_1_UPSW_STS 1 "UPSW_ON" 0 "UPSW_OFF" ;
VAL_ 1679 MET68F_3_2_ISETSW_STS 1 "ISETSW_ON" 0 "ISETSW_OFF" ;
VAL_ 1679 MET68F_3_3_MUD_SAND_SW_STS 1 "MUD_SAND_SW_ON" 0 "MUD_SAND_SW_OFF" ;
VAL_ 1679 MET68F_3_4_SNOW_DIRT_SW_STS 1 "SNOW_DIRT_SW_ON" 0 "SNOW_DIRT_SW_OFF" ;
VAL_ 1679 MET68F_3_5_WIDGET_SW_STS 1 "WIDGET_SW_ON" 0 "WIDGET_SW_OFF" ;
VAL_ 1679 MET68F_3_6_OK_SW_STS 1 "OK_SW_ON" 0 "OK_SW_OFF" ;
VAL_ 1679 MET68F_2_0_SIDRVSW_STS 3 "SIDRVSW_STS_SWB3_ON" 2 "SIDRVSW_STS_SWB2_ON" 1 "SIDRVSW_STS_SWB1_ON" 0 "SIDRVSW_STS_SW_OFF" ;
VAL_ 1678 MET68E_7_0_EGO_CAR_DISP_COLOR 9 "EGO_CAR_DISP_COLOR_P10" 8 "EGO_CAR_DISP_COLOR_P9" 7 "EGO_CAR_DISP_COLOR_P8" 6 "EGO_CAR_DISP_COLOR_P7" 5 "EGO_CAR_DISP_COLOR_P6" 4 "EGO_CAR_DISP_COLOR_P5" 3 "EGO_CAR_DISP_COLOR_P4" 2 "EGO_CAR_DISP_COLOR_P3" 1 "EGO_CAR_DISP_COLOR_P2" 0 "EGO_CAR_DISP_COLOR_P1" ;
VAL_ 1678 MET68E_4_0_CSTM_ALERT_VOL_VAL 3 "RESERVED" 2 "LARGE" 1 "MIDDLE" 0 "SMALL" ;
VAL_ 1678 MET68E_4_2_CSTM_SHIFT 1 "CSTM_SHIFT_ON" 0 "CSTM_SHIFT_OFF" ;
VAL_ 1678 MET68E_4_3_CSTM_WOW 1 "CSTM_WOW_ON" 0 "CSTM_WOW_OFF" ;
VAL_ 1678 MET68E_4_4_CSTM_GBYE 3 "Undefined" 2 "Undefined" 1 "CSTM_WLCM_ON" 0 "CSTM_WLCM_OFF" ;
VAL_ 1678 MET68E_4_6_CSTM_WLCM 3 "Undefined" 2 "Undefined" 1 "CSTM_WLCM_ON" 0 "CSTM_WLCM_OFF" ;
VAL_ 1678 MET68E_3_1_CSTM_REAR_REMIND 1 "CSTM_REAR_REMIND_ON" 0 "CSTM_REAR_REMIND_OFF" ;
VAL_ 1678 MET68E_3_2_SET_UNIT_OF_ELEC 7 "RESERVED" 6 "RESERVED" 5 "miles_MPH_kWh/100mile" 4 "miles_MPH_Wh/mile" 3 "miles_MPH_mile/kWh" 2 "km_km/h_kWh/100km" 1 "km_km/h_Wh/km" 0 "km_km/h_km/kWh" ;
VAL_ 1678 MET68E_3_5_CSTM_ES_STARTBZ 2 "CSTM_ES_STARTBZ_VOICE_ON" 1 "CSTM_ES_STARTBZ_BUZZER_ON" 0 "CSTM_ES_STARTBZ_OFF" ;
VAL_ 1678 MET68E_3_7_CSTM_ES_CATCHBZ 1 "CSTM_ES_CATCHBZ_ON" 0 "CSTM_ES_CATCHBZ_OFF" ;
VAL_ 1678 MET68E_2_0_CSTM_METUNIT 4 "RESERVED" 3 "miles_MPH_gal(UK)" 2 "miles_MPH_gal(US)" 1 "km_km/h_l/100km" 0 "km_km/h_km/l" ;
VAL_ 1674 MET68A_16_0_TRIP_DISP_TYPE 3 "RESERVED" 2 "TRIP_DISP_TYPE_TRIPB" 1 "TRIP_DISP_TYPE_TRIPA" 0 "TRIP_DISP_TYPE_ODO" ;
VAL_ 1674 MET68A_6_6_SI_FAIL_FLAG 1 "FAIL" 0 "NORMAL" ;
VAL_ 1674 MET68A_4_1_ILM_AIDM 1 "ILM_AIDM_NIGHT" 0 "ILM_AIDM_DAYTIME" ;
VAL_ 1674 MET68A_4_2_TEMP_ICON 7 "TEMP_ICON_NONE" 6 "TEMP_ICON_BLUEWHITE" 5 "TEMP_ICON_REDWHITE" 4 "TEMP_ICON_RED" 3 "TEMP_ICON_BLUE_BLINK" 2 "TEMP_ICON_REDBLUE" 1 "TEMP_ICON_BLUE" 0 "TEMP_ICON_WHITE" ;
VAL_ 1674 MET68A_4_5_SIDRIVE_MET_DISP 7 " RESERVED" 6 "S" 5 "ECO-C" 4 "I" 3 "DEEP_SNOW_MUD" 2 "S#" 1 "X_SNOW_DIRT" 0 "NO_INPUT" ;
VAL_ 1673 MET689_20_0_VOICE_GUIDE_SUP 1 "ACTIVE" 0 "NON_ACTIVE" ;
VAL_ 1673 MET689_16_0_GSR_ELKS_SUP 1 "GSR_ELKS_SUP_ACTIVE" 0 "GSR_ELKS_SUP_NONE" ;
VAL_ 1673 MET689_16_1_GSR_AEBS_SUP 1 "GSR_AEBS_SUP_ACTIVE" 0 "GSR_AEBS_SUP_NONE" ;
VAL_ 1673 MET689_16_2_GSR_DDAW_SUP 1 "GSR_DDAW_SUP_ACTIVE" 0 "GSR_DDAW_SUP_NONE" ;
VAL_ 1673 MET689_16_3_GSR_ISA_SUP 1 "GSR_ISA_SUP_ACTIVE" 0 "GSR_ISA_SUP_NONE" ;
VAL_ 1673 MET689_16_4_IACC_SUP 1 "IACC_SUP_ACTIVE" 0 "IACC_SUP_NONE" ;
VAL_ 1673 MET689_16_7_SEAT_VENT_SUP 1 "SEAT_VENT_SUP_ACTIVE" 0 "SEAT_VENT_SUP_NONE" ;
VAL_ 1673 MET689_15_0_CAMERA 8 "CAMERA_SIDE(LVDS)" 7 "CAMERA_REAR_FRONT_SIDE2(LVDS)" 6 "CAMERA_REAR_FRONT_SIDE(LVDS)" 5 "CAMERA_REAR_FRONT(LVDS)" 4 "CAMERA_REAR(LVDS)" 3 "CAMERA_REAR_FRONT_SIDE(NTSC)" 2 "CAMERA_REAR_FRONT(NTSC)" 1 "CAMERA_REAR" 0 "CAMERA_NONE" ;
VAL_ 1673 MET689_12_0_SPK_AMP 17 "SPK_AMP_EXTERNALAMP_LEATHER_8SP" 16 "SPK_AMP_EXTERNALAMP_LEATHER_12SP" 9 "SPK_AMP_EXTERNALAMP_CLOTH_8SP" 8 "SPK_AMP_EXTERNALAMP_CLOTH_12SP" 7 "SPK_AMP_INTERNALAMP_BOOOSTER_10SP" 6 "SPK_AMP_INTERNALAMP_BOOOSTER_11SP" 5 "SPK_AMP_EXTERNALAMP_8SP" 4 "SPK_AMP_EXTERNALAMP_LEATHER" 3 "SPK_AMP_EXTERNALAMP_CLOTH" 2 "SPK_AMP_INTERNALAMP_6SP" 1 "SPK_AMP_INTERNALAMP_4SP" 0 "SPK_AMP_NON_CONNECT" ;
VAL_ 1673 MET689_10_1_SIDRIVE_SW_TYPE 3 "RESERVE" 2 "SOFT_SW" 1 "HARD_SW" 0 "NONE" ;
VAL_ 1673 MET689_10_3_XMODE_SW_TYPE 3 "RESERVE" 2 "SOFT_SW" 1 "HARD_SW" 0 "NONE" ;
VAL_ 1673 MET689_9_0_GPF_SUP 1 "GPF_SUP_ACTIVE" 0 "GPF_SUP_NONE" ;
VAL_ 1673 MET689_9_3_REAR_REMIND_SUP 1 "REAR_REMIND_SUP_ACTIVE" 0 "REAR_REMIND_SUP_NONE" ;
VAL_ 1673 MET689_9_5_TPMSDISP_SUP 1 "TPMSDISP_SUP_ACTIVE" 0 "TPMSDISP_SUP_NONE" ;
VAL_ 1673 MET689_9_6_GSI_SUP 1 "GSI_SUP_ACTIVE" 0 "GSI_SUP_NONE" ;
VAL_ 1673 MET689_9_7_SRVD_SUP 1 "SRVD_SUP_ACTIVE" 0 "SRVD_SUP_NONE" ;
VAL_ 1673 MET689_8_0_XMODE_SUP 3 "XMODE_SUP_ACTIVE(2MODE_GRAVEL)" 2 "XMODE_SUP_ACTIVE(2MODE)" 1 "XMODE_SUP_ACTIVE(1MODE)" 0 "XMODE_SUP_NONE" ;
VAL_ 1673 MET689_7_0_SIDRIVE_SUP 19 "3MODE_1SW" 18 "SI-DS(I,S,S#,TRACK+Individual)_3SW" 17 "SI-DS(I,S,S#,ECO(VTD)+Individual)_2SW" 16 "SI-DS(I,S,S#,ECO(VTD)+Individual)_1SW" 9 "SI-DS(I,S,S#,ECO(ACT4)+Individual)_2SW" 8 "SI-DS(I,S,S#,ECO(ACT4)+Individual)_1SW" 7 "1MODE(ECO-C)" 6 "3MODE(I,S,ECO-C)" 5 "2MODE_1SW(I,S)" 4 "2MODE(I,S#)" 3 "3MODE_3SW" 2 "3MODE_2SW" 1 "2MODE(I,S)" 0 "NONE" ;
VAL_ 1673 MET689_6_0_GRADE_INFO 1 "GRADE_INFO_WILDERNESS" 0 "GRADE_INFO_NONE" ;
VAL_ 1672 MET688_13_5_STATUS_PWRLMT_WARN 7 "RESERVED" 6 "RESERVED" 5 "RESERVED" 4 "RESERVED" 3 "TURN_ON(TEXT_C)" 2 "TURN_ON(TEXT_B)" 1 "TURN_ON(TEXT_A)" 0 "TURN_OFF(NON_REQ)" ;
VAL_ 1672 MET688_13_3_STATUS_HVB_WARN 3 "RESERVED" 2 "LOW_TEMP_WARN" 1 "HIGH_TEMP_WARN" 0 "NON_REQ" ;
VAL_ 1672 MET688_13_0_STATUS_EV_FAIL 7 "RESERVED" 6 "RESERVED" 5 "RESERVED" 4 "BULB_CHECK" 3 "BLINK(3Hz)" 2 "BLINK(1Hz)" 1 "TURN_ON" 0 "TURN_OFF(NON_REQ)" ;
VAL_ 1672 MET688_12_6_STATUS_ICY_ROAD 1 "ON" 0 "OFF" ;
VAL_ 1672 MET688_12_5_STATUS_DOOR_DRVR 1 "TURN_ON" 0 "TURN_OFF" ;
VAL_ 1672 MET688_12_4_STATUS_DOOR_PASS 1 "TURN_ON" 0 "TURN_OFF" ;
VAL_ 1672 MET688_12_3_STATUS_DOOR_RRRH 1 "TURN_ON" 0 "TURN_OFF" ;
VAL_ 1672 MET688_12_2_STATUS_DOOR_RRLH 1 "TURN_ON" 0 "TURN_OFF" ;
VAL_ 1672 MET688_12_1_STATUS_DOOR_RG 1 "TURN_ON" 0 "TURN_OFF" ;
VAL_ 1672 MET688_12_0_STATUS_DOOR_TR 1 "TURN_ON" 0 "TURN_OFF" ;
VAL_ 1672 MET688_11_5_STATUS_IPMS_IND 7 "RESERVED" 6 "RESERVED" 5 "RESERVED" 4 "RESERVED" 3 "RESERVED" 2 "RESERVED" 1 "TURN_ON" 0 "TURN_OFF" ;
VAL_ 1672 MET688_11_2_STATUS_SIDRIVE_MODE 7 "RESERVED" 6 "S" 5 "ECO-C" 4 "I" 3 "DEEP_SNOW_MAD" 2 "S#" 1 "X_OR_SNOW_DIRT" 0 "TURN_OFF" ;
VAL_ 1672 MET688_11_0_STATUS_HEADLAMP_FAIL 3 "RESERVED" 2 "RESERVED" 1 "TURN_ON" 0 "TURN_OFF" ;
VAL_ 1672 MET688_10_7_STATUS_HBA_FAIL 1 "TURN_ON" 0 "TURN_OFF" ;
VAL_ 1672 MET688_10_5_STATUS_HBA_ACT 3 "RESERVED" 2 "BLINK" 1 "TURN_ON" 0 "TURN_OFF" ;
VAL_ 1672 MET688_10_4_STATUS_RAB_OFF 1 "TURN_ON" 0 "TURN_OFF" ;
VAL_ 1672 MET688_10_2_STATUS_EPB_ACT 3 "RESERVED" 2 "BLINK" 1 "TURN_ON" 0 "TURN_OFF" ;
VAL_ 1672 MET688_10_1_STATUS_PCR_OFF 1 "TURN_ON" 0 "TURN_OFF" ;
VAL_ 1672 MET688_10_0_STATUS_LANEOFF_WARN 1 "TURN_ON" 0 "TURN_OFF" ;
VAL_ 1672 MET688_9_5_STATUS_CODE_HALT 7 "RESERVED" 6 "HALT_E5" 5 "HALT_E4" 4 "HALT_E3" 3 "HALT_E2" 2 "HALT_E1-2" 1 "HALT_E1-1" 0 "NO_HALT" ;
VAL_ 1672 MET688_9_4_STATUS_HOOD_OPEN 1 "TURN_ON" 0 "TURN_OFF" ;
VAL_ 1672 MET688_9_3_STATUS_BSD_OFF 1 "TURN_ON" 0 "TURN_OFF" ;
VAL_ 1672 MET688_9_2_STATUS_BSD_FAIL 1 "TURN_ON" 0 "TURN_OFF" ;
VAL_ 1672 MET688_9_0_STATUS_SONAR_SYS_FAIL 3 "RESERVED" 2 "FAIL(RAB)" 1 "FAIL(SONAR)" 0 "NORMAL" ;
VAL_ 1672 MET688_8_5_STATUS_ABG_PASS_IND 3 "OFF/OFF(ON_INDI/OFF_INDI)" 2 "ON/OFF(ON_INDI/OFF_INDI)" 1 "OFF/ON(ON_INDI/OFF_INDI)" 0 "ON/ON(ON_INDI/OFF_INDI)" ;
VAL_ 1672 MET688_8_4_STATUS_HEADLAMP_SMALL 1 "TURN_ON" 0 "TURN_OFF" ;
VAL_ 1672 MET688_8_2_STATUS_HDC 3 "RESERVED" 2 "BLINK" 1 "TURN_ON" 0 "TURN_OFF" ;
VAL_ 1672 MET688_8_1_STATUS_CC_SET_IND 1 "TURN_ON" 0 "TURN_OFF" ;
VAL_ 1672 MET688_8_0_STATUS_CC_MAIN_IND 1 "TURN_ON" 0 "TURN_OFF" ;
VAL_ 1672 MET688_7_7_STATUS_FT_FOG 1 "TURN_ON" 0 "TURN_OFF" ;
VAL_ 1672 MET688_7_4_STATUS_SRH 7 "RESERVED" 6 "RESERVED" 5 "RESERVED" 4 "RESERVED" 3 "TURN_ON_(FAIL_Lamp)" 2 "RESERVED" 1 "TURN_ON_(OFF_Lamp)" 0 "TURN_OFF" ;
VAL_ 1672 MET688_7_1_STATUS_AHL 7 "RESERVED" 6 "RESERVED" 5 "RESERVED" 4 "RESERVED" 3 "BLINK" 2 "BLINK(3_TIMES)" 1 "TURN_ON" 0 "TURN_OFF" ;
VAL_ 1672 MET688_7_0_STATUS_HEADLAMP_HI 1 "TURN_ON" 0 "TURN_OFF" ;
VAL_ 1672 MET688_6_7_STATUS_AVH_ACT 1 "BLINK" 0 "NOT_BLINK" ;
VAL_ 1672 MET688_6_6_STATUS_AVH_ON 1 "TURN_ON_OR_BLINK" 0 "TURN_OFF" ;
VAL_ 1672 MET688_6_4_STATUS_BREAK_IND 3 "RESERVED" 2 "BREAK_IND_ON(AVH_FAIL)" 1 "BREAK_IND_ON(OTHER_FAIL)" 0 "BREAK_IND_OFF" ;
VAL_ 1672 MET688_6_0_STATUS_WARN_SSP_SIG1 21 "RESERVED" 20 "RESERVED" 19 "RESERVED" 18 "SMART13(READY_TO_RUN)" 17 "RESERVED" 16 "SMART4(KEY_Battery_LOW_WARN)" 9 "RESERVED" 8 "RESERVED" 7 "SMART9(NO_KEY_WARN)" 6 "RESERVED" 5 "SMART5-2(Emergency_OPERATE_INDI)" 4 "SMART5-1(Emergency_OPERATE_INDI)" 3 "RESERVED" 2 "SMART3(Steering_Lock_NON_Release_WARN)" 1 "SMART2(SMART_FAIL_WARN)" 0 "NON_REQ" ;
VAL_ 1672 MET688_5_4_STATUS_VDC_OFF 1 "TURN_ON" 0 "TURN_OFF" ;
VAL_ 1672 MET688_5_3_STATUS_CHG_WARN 1 "TURN_ON" 0 "TURN_OFF" ;
VAL_ 1672 MET688_5_2_STATUS_SEATBELT_PASS 1 "ON_BeltOFF" 0 "OFF_BeltON" ;
VAL_ 1672 MET688_5_1_STATUS_SEATBELT_DRVR 1 "ON_BeltOFF" 0 "OFF_BeltON" ;
VAL_ 1672 MET688_5_0_STATUS_EYESIGHT_FAIL 1 "TURN_ON" 0 "TURN_OFF" ;
VAL_ 1672 MET688_4_5_STATUS_EPS_WARN 7 "TURN_OFF" 6 "TURN_ON(FAIL)" 5 "TURN_ON(FAIL)" 4 "TURN_ON(INITIAL_CHECK)" 3 "TURN_ON(FAIL)" 2 "TURN_OFF" 1 "TURN_OFF" 0 "TURN_OFF" ;
VAL_ 1672 MET688_4_3_STATUS_ABG_WARN 3 "TURN_ON(OTHER_FAIL)" 2 "TURN_OFF" 1 "TURN_ON(FAIL)" 0 "TURN_OFF" ;
VAL_ 1672 MET688_4_0_STATUS_TPMS_WARN 7 "PATTERN1_OR_PATTERN3" 6 "PATTERN3" 5 "PATTERN3" 4 "PATTERN2" 3 "PATTERN1_OR_PATTERN3" 2 "PATTERN1(BREAKING_OF_WIRE)_OR_PATTERN3" 1 "TURN_ON" 0 "TURN_OFF" ;
VAL_ 1672 MET688_3_5_STATUS_EBD_WARN 1 "TURN_ON_OR_BLINK" 0 "TURN_OFF" ;
VAL_ 1672 MET688_3_4_STATUS_VDC_WARN 1 "TURN_ON" 0 "TURN_OFF_OR_BLINK" ;
VAL_ 1672 MET688_3_3_STATUS_ABS_WARN 1 "TURN_ON" 0 "TURN_OFF" ;
VAL_ 1672 MET688_3_1_STATUS_AWD_WARN 3 "TURN_ON" 2 "BLINK#2" 1 "BLINK#1" 0 "TURN_OFF" ;
VAL_ 1672 MET688_3_0_STATUS_WASHER_WARN 1 "TURN_ON" 0 "TURN_OFF" ;
VAL_ 1614 RKE64E_6_0_BUZ_1SHOT_IN 1 "REQ" 0 "NON_REQ" ;
VAL_ 1614 RKE64E_6_1_BUZ_2SHOT_IN 1 "REQ" 0 "NON_REQ" ;
VAL_ 1614 RKE64E_6_2_REQ_WARNG_BAT_POWER 1 "Battery_Power_Low" 0 "Battery_Power_Normal" ;
VAL_ 1614 RKE64E_4_0_TRANS_ID 4 "Trans ID 4" 3 "Trans ID 3" 2 "Trans ID 2" 1 "Trans ID 1" 0 "NON_REG" ;
VAL_ 1614 RKE64E_4_3_COUNTER 3 "counter value 3" 2 "counter value 2" 1 "counter value 1" 0 "counter value 0" ;
VAL_ 1614 RKE64E_4_5_TIME_ON_SW_KEY_LESS 3 "more than 2.4s" 2 "1.6s-2.4s" 1 "0.8s-1.6s" 0 "under 0.8s" ;
VAL_ 1614 RKE64E_3_0_REQ_NOMAL_KEY_LESS 8 "TRUNK_REQ" 4 "UNLOCK_REQ" 2 "LOCK_REQ" 1 "PANIC_REQ" 0 "NON_REQ" ;
VAL_ 1614 RKE64E_1_4_WAKE_UP_FRAME 1 "WakeUP_FRAME" 0 "Normal_FRAME" ;
VAL_ 1614 RKE64E_1_5_REQ_COMM_CONT 1 "REQ" 0 "NON_REQ" ;
VAL_ 1658 TPM67A_6_1_TIRE_COLOR_RR 3 "NON" 2 "NON" 1 "LOW_PRESSURE(YELLOW)" 0 "NOMAL(WHITE)" ;
VAL_ 1658 TPM67A_6_5_TIRE_COLOR_RL 3 "NON" 2 "NON" 1 "LOW_PRESSURE(YELLOW)" 0 "NOMAL(WHITE)" ;
VAL_ 1658 TPM67A_3_1_TIRE_COLOR_FL 3 "NON" 2 "NON" 1 "LOW_PRESSURE(YELLOW)" 0 "NOMAL(WHITE)" ;
VAL_ 1658 TPM67A_3_5_TIRE_COLOR_FR 3 "NON" 2 "NON" 1 "LOW_PRESSURE(YELLOW)" 0 "NOMAL(WHITE)" ;
VAL_ 1658 TPM67A_1_5_UNIT_IND_PRESSURE 3 "NON" 2 "NON" 1 "kPa" 0 "psi" ;
VAL_ 1658 TPM67A_1_7_IND_PRESSURE 1 "IND_PRESSURE" 0 "NO_IND_PRESSURE" ;
VAL_ 1657 TPM679_3_0_STATE_TPMS 3 "MODE_ERROR" 2 "TPMS3" 1 "TPMS2" 0 "TPMS1" ;
VAL_ 1657 TPM679_3_2_DEFINED_STATE_TPMS 3 "UNDER_CONFIRMATION" 2 "THRESHOLD_DECISION" 1 "UNDER_THRESHOLDING" 0 "NOMAL" ;
VAL_ 1657 TPM679_3_4_MODE_SELECT_TPMS 3 "Undefined" 2 "2Mode" 1 "3Mode" 0 "NOMAL" ;
VAL_ 1657 TPM679_2_0_WARN_TPMS 7 "FLASH_ON_1" 6 "FLASH_ON_3" 5 "FLASH_ON_3" 4 "FLASH_ON_2" 3 "FLASH_ON_1" 2 "FLASH_ON_1" 1 "LAMP_ON" 0 "LAMP_OFF" ;
VAL_ 1657 TPM679_2_3_INTERRUPT 2 "SYSTEM_FAIL" 1 "LOW_PRESSURE" 0 "NON_IND" ;
VAL_ 1657 TPM679_2_5_CHECKLUMP_TPMS 1 "LAMP_ON" 0 "LAMP_OFF" ;
VAL_ 827 ABG33B_4_0_PASSENGER_BELT_INFO 3 "MALFUNCTION" 2 "UNSTTLED" 1 "BELTED" 0 "UNBELTED" ;
VAL_ 827 ABG33B_4_2_PASSENGER_DETECT_INFO 7 "RESERVED" 6 "RESERVED" 5 "MALFUNCTION" 4 "UNSETTLED UNSTTLED" 3 "AM50 INCLUDING AM95" 2 "AF05" 1 "CHILD OR CRS (CHILD RESTRAINT SYSTEM)" 0 "NOT OCCUPANT" ;
VAL_ 827 ABG33B_3_0_PPS_STATUS_FAIL_IGN 1 "FAIL" 0 "NORMAL" ;
VAL_ 827 ABG33B_3_1_PPS_STATUS_FAIL_DEV 1 "FAIL" 0 "NORMAL" ;
VAL_ 827 ABG33B_3_2_PPS_STATUS_FAIL_SSR 1 "FAIL" 0 "NORMAL" ;
VAL_ 827 ABG33B_3_3_PPS_STATUS_FAIL_ECU 1 "FAIL" 0 "NORMAL" ;
VAL_ 827 ABG33B_2_0_IND_WARN_PPA 3 "OTHER_FAIL" 2 "RESERVE" 1 "FAIL_Turn_ON" 0 "Turn_OFF" ;
VAL_ 827 ABG33B_2_2_DETECT_CRUSH 7 "RESERVE" 6 "RESERVE" 5 "CRASH DETECTION" 4 "RESERVE" 3 "RESERVE" 2 "RESERVE" 1 "RESERVE" 0 "NORMAL" ;
VAL_ 827 ABG33B_1_4_FLG_PEDESTRIAN_AIRBAG 1 "w PPS" 0 "w/o PPS" ;
VAL_ 826 ABG33A_5_0_P_SIDE_ABG_DEPLOY 1 "ON" 0 "OFF" ;
VAL_ 826 ABG33A_5_1_D_SIDE_ABG_DEPLOY 1 "ON" 0 "OFF" ;
VAL_ 826 ABG33A_5_2_FRONT_FAR_ABG_DEPLOY 1 "ON" 0 "OFF" ;
VAL_ 826 ABG33A_5_3_REAR_FAR_ABG_DEPLOY 1 "ON" 0 "OFF" ;
VAL_ 826 ABG33A_5_4_REAR_RH_ABG_DEPLOY 1 "ON" 0 "OFF" ;
VAL_ 826 ABG33A_5_5_REAR_LH_ABG_DEPLOY 1 "ON" 0 "OFF" ;
VAL_ 826 ABG33A_5_6_P_CURTAIN_ABG_DEPLOY 1 "ON" 0 "OFF" ;
VAL_ 826 ABG33A_5_7_D_CURTAIN_ABG_DEPLOY 1 "ON" 0 "OFF" ;
VAL_ 826 ABG33A_4_0_D_FRONT_ABG_DEPLOY 1 "ON" 0 "OFF" ;
VAL_ 826 ABG33A_4_1_P_FRONT_ABG_DEPLOY 1 "ON" 0 "OFF" ;
VAL_ 826 ABG33A_4_2_P_ABG_DEPLOY 1 "ON" 0 "OFF" ;
VAL_ 826 ABG33A_4_3_D_ABG_DEPLOY 1 "ON" 0 "OFF" ;
VAL_ 826 ABG33A_4_4_P_BELT_PRETENTION 1 "ON" 0 "OFF" ;
VAL_ 826 ABG33A_4_5_D_BELT_PRETENTION 1 "ON" 0 "OFF" ;
VAL_ 826 ABG33A_4_6_D_KNEE_ABG_DEPLOY 1 "ON" 0 "OFF" ;
VAL_ 826 ABG33A_4_7_P_KNEE_ABG_DEPLOY 1 "ON" 0 "OFF" ;
VAL_ 826 ABG33A_3_0_BELT_WRNING_PASS 3 "SW_FAIL" 2 "UNDECIDED" 1 "UNBUCKLED(PASSENGER OCCUPANT)" 0 "BUCKLE OR UNBUCKLED(PASSENGER EMPTY)" ;
VAL_ 826 ABG33A_3_2_BUCKLESW_DRVR 3 "NOT RECEIVED" 2 "INVALID" 1 "BUCKLE SW OFF" 0 "BUCKLE SW ON" ;
VAL_ 826 ABG33A_3_4_OCCUPATION_PASS 3 "SYS_FAIL" 2 "NON" 1 "ACTIVE" 0 "Non_PASSENGER" ;
VAL_ 826 ABG33A_3_6_IND_ACT_ABG_PASS 3 "NON" 2 "ON_IND" 1 "OFF_IND" 0 "ON_IND and OFF_IND" ;
VAL_ 826 ABG33A_2_0_IND_WARN_ABG 3 "OTHER_FAIL" 2 "RESERVE" 1 "FAIL_Turn_ON" 0 "Turn_OFF" ;
VAL_ 826 ABG33A_2_2_DETECT_CRUSH 7 "RESERVE" 6 "RESERVE" 5 "CRUSH_DETECT" 4 "RESERVE" 3 "RESERVE" 2 "RESERVE" 1 "RESERVE" 0 "NORMAL" ;
VAL_ 826 ABG33A_2_5_STATUS_CRUSH_ECALL 7 "RESERVE" 6 "RESERVE" 5 "REAR COLLISION" 4 "ROLLOVER" 3 "RIGHT SIDE COLLISION" 2 "LEFT SIDE COLLISION" 1 "FRONTAL COLLISION" 0 "NORMAL" ;
VAL_ 826 ABG33A_1_4_FLG_ABGIND_CTRL 1 "ACTIVE_PassengerSeat IND contorol" 0 "NON_PassengerSeat IND contorol" ;
VAL_ 826 ABG33A_1_5_REQ_COMM_CONT 1 "REQ" 0 "NON_REQ" ;
VAL_ 826 ABG33A_1_6_COLLISION_COUNTER 3 "RESERVD" 2 "MORE THAN ONCE" 1 "ONECE" 0 "NORMAL" ;
VAL_ 961 DMS3C1_7_4_SHORT_DIST_DETECT 1 "SHORT_DIST_DETECT" 0 "NO_SHORT_DIST_DETECT" ;
VAL_ 961 DMS3C1_7_5_PRESENCE_DETECT 1 "PRESENCE" 0 "NO_PRESENCE" ;
VAL_ 961 DMS3C1_7_6_RADER_EQUIP 1 "RADAR_EQUIP" 0 "NO_RADAR_EQUIP" ;
VAL_ 961 DMS3C1_7_7_LOSING_POSTURE_DETECT 1 "LOSING_POSTURE" 0 "NO_LOSING_POSTURE" ;
VAL_ 961 DMS3C1_6_0_ID_RECOG_CANCEL 1 "ID_RECOG_CANCEL" 0 "DEFAULT" ;
VAL_ 961 DMS3C1_6_1_ID_ENABLE_FLAG 1 "ID_VALID" 0 "ID_INVALID" ;
VAL_ 961 DMS3C1_6_2_PERMIT_AVN_FLAG 1 "PERMIT" 0 "PROHIBIT" ;
VAL_ 961 DMS3C1_6_4_DISTRACTION_STATUS 1 "DISTRACTION" 0 "DEFAULT" ;
VAL_ 961 DMS3C1_6_5_DROWSINESS_STATUS 1 "DROWSINESS" 0 "DEFAULT" ;
VAL_ 961 DMS3C1_6_6_DROWSINESS_LV2_STATUS 1 "DROWSINESS_LEVEL2" 0 "DEFAULT" ;
VAL_ 961 DMS3C1_6_7_NOT_DETECTED_STATUS 1 "NOT_DETECTED" 0 "DETECTED" ;
VAL_ 961 DMS3C1_5_0_ID_LIST 31 "ID_1_2_3_4_5" 1 "ID_1" 0 "DEFAULT" ;
VAL_ 961 DMS3C1_5_5_ID_EDIT_FLAG 6 "REQ_ID_DEL_ALL" 5 "REQ_CUST_DEL_DELECT" 4 "REQ_ID_DEL_DELECT" 3 "REQ_ID_CUST_EDIT" 2 "REQ_ID_REGIST" 0 "DEFAULT" ;
VAL_ 961 DMS3C1_4_0_DMS_IND_REQ_FLAG 7 "UNDEFINED" 5 "FAULT_IND" 4 "HALT_IND" 3 "OFF_IND" 2 "ID_DEF_IND" 1 "ID_UNDEF_IND" 0 "DEFAULT" ;
VAL_ 961 DMS3C1_4_3_DMS_RECOG_STATUS 1 "IDENTIFING_ON" 0 "IDENTIFING_OFF" ;
VAL_ 961 DMS3C1_4_4_DRIVER_STATUS 3 "DRV_GLASSES" 2 "DRV_MASK" 1 "DRV_NORMAL" 0 "DEFAULT" ;
VAL_ 961 DMS3C1_3_0_DRIVER_REGIST_ID 15 "IDENTIFING" 14 "ALL_ID" 5 "ID_5" 4 "ID_4" 3 "ID_3" 2 "ID_2" 1 "ID_1" 0 "DEFAULT" ;
VAL_ 961 DMS3C1_3_4_CUST_EDIT_FLAG 3 "REQ_CUST_FAIL" 2 "REQ_CUST_COMP" 1 "REQ_CUST_PRESENT" 0 "DEFAULT" ;
VAL_ 961 DMS3C1_3_6_ID_RECOG_FLAG 1 "ID_DEFINED" 0 "ID_UNDIFINED" ;
VAL_ 961 DMS3C1_2_0_LEVEL_DROWS 2 "DROWS_LEVEL2" 1 "DROWS_LEVEL1" 0 "NO_DROWSINESS" ;
VAL_ 961 DMS3C1_2_3_DROWS_DETECT_FLAG 1 "DROWS_DETECT" 0 "NO_DROWS_DETECT" ;
VAL_ 961 DMS3C1_2_7_DIST_DETECT_FLAG 1 "DIST_DETECT" 0 "NO_DIST_DETECT" ;
VAL_ 961 DMS3C1_1_4_WAKE_UP_FRAME 1 "WakeUP_FRAME" 0 "Normal_FRAME" ;
VAL_ 961 DMS3C1_1_5_REQ_COMM_CONT 1 "REQUEST" 0 "NO_REQUEST" ;
VAL_ 961 DMS3C1_1_7_EYE_DIST_FLAG 1 "EYE_DIST_DETECT" 0 "NO_DETECT" ;
VAL_ 1290 DMS50A_1_4_ActiveWakeUpBit 1 "active wakeup" 0 "passive wakeup" ;
VAL_ 1730 AVN6C2_7_0_LANGUAGE_SET 33 "Vietnamese" 32 "Thai" 31 "Bahasa Indonesia" 30 "Malay" 29 "Ukrainian" 28 "Turkish" 27 "Swedish" 26 "Slovak" 25 "Traditional Chinese" 24 "Simplified Chinese" 23 "Russian" 22 "Romanian" 21 "European Portuguese" 20 "Polish" 19 "Norwegian" 18 "Japanese" 17 "Italian" 16 "Hungarian" 15 "Hebrew" 14 "Greek" 13 "German" 12 "Finnish" 11 "European Spanish" 10 "European French" 9 "Dutch" 8 "Danish" 7 "Czech" 6 "British English" 5 "Australian English" 4 "Arabic" 3 "Mexican Spanish" 2 "Canadian French" 1 "American English" 0 "Invalid" ;
VAL_ 1730 AVN6C2_7_6_VALETMODE_ON_OFF 3 "Reserve" 2 "Valet ON" 1 "Valet OFF" 0 "Invalid" ;
VAL_ 1729 AVN6C1_7_0_MVS_VIEW_SELECT_SW 6 "Top+3D View (REAR)" 5 "Top View+Side and Side View" 4 "Top View+Front Narrow" 3 "Top View+Front Wide" 2 "Top View+Rear Narrow" 1 "Top View+Rear Wide" 0 "No request" ;
VAL_ 1729 AVN6C1_7_4_MVS_AUTO_DISPLAY_SW 3 "Reserved" 2 "ON" 1 "OFF" 0 "No request" ;
VAL_ 1729 AVN6C1_7_6_MVS_HITCH_GUIDE_REQ 3 "Reserved" 2 "ON" 1 "OFF" 0 "No request" ;
VAL_ 1725 AVN6BD_7_1_EYE_SAFETY_MODE_CSTM 1 "ON" 0 "OFF" ;
VAL_ 1725 AVN6BD_7_2_EYE_BRAKE_HAPTIC_CSTM 3 "BUZZER OFF/BREAK OFF" 2 "BUZZER OFF/BREAK ON" 1 "BUZZER ON/BREAK OFF" 0 "BUZZER ON/BREAK ON" ;
VAL_ 1725 AVN6BD_7_4_LDW_SW_PUSH_STATE 1 "SW_Push" 0 "SW_Release" ;
VAL_ 1725 AVN6BD_7_5_LDW_SW_FAIL_STATE 1 "Fail" 0 "No_Fail" ;
VAL_ 1725 AVN6BD_7_6_FCW_SW_PUSH_STATE 1 "SW_Push" 0 "SW_Release" ;
VAL_ 1725 AVN6BD_7_7_FCW_SW_FAIL_STATE 1 "Fail" 0 "No_Fail" ;
VAL_ 1725 AVN6BD_6_0_REQ_CHG_CSTM_EYE 1 "required" 0 "NOT required" ;
VAL_ 1725 AVN6BD_6_1_REQ_RESET_CSTM_EYE 1 "required" 0 "NOT required" ;
VAL_ 1725 AVN6BD_6_3_CSTM_LANE_CONT 1 "LEFT" 0 "RIGHT" ;
VAL_ 1725 AVN6BD_6_4_CSTM_MIS_AT_BACK 3 "ON_FAST" 2 "ON_MIDDLE" 1 "ON_SLOW" 0 "OFF" ;
VAL_ 1725 AVN6BD_6_6_CSTM_ACC_CONT 3 "Dynamic" 2 "Standard" 1 "Comfort" 0 "Eco" ;
VAL_ 1724 AVN6BC_5_0_LAT_N_S 1 "South" 0 "North" ;
VAL_ 1724 AVN6BC_1_4_GNSS_STATUS 7 "GNSS fail" 6 "Estimation error level 5" 5 "Estimation error level 4" 4 "Estimation error level 3" 3 "Estimation error level 2" 2 "Estimation error level 1" 1 "No fix" 0 "Invalid" ;
VAL_ 1724 AVN6BC_1_7_LON_E_W 1 "East" 0 "West" ;
VAL_ 1723 AVN6BB_7_0_ISA_IACC_OFFSET_CSTM 20 "10" 19 "9" 18 "8" 17 "7" 16 "6" 15 "5" 14 "4" 13 "3" 12 "2" 11 "1" 10 "0" 9 "-1" 8 "-2" 7 "-3" 6 "-4" 5 "-5" 4 "-6" 3 "-7" 2 "-8" 1 "-9" 0 "-10" ;
VAL_ 1723 AVN6BB_7_5_EYE_TOLLBOOTH_DECEL 1 "ON" 0 "OFF" ;
VAL_ 1723 AVN6BB_7_6_EYE_CURVE_DECEL_CSTM 1 "ON" 0 "OFF" ;
VAL_ 1723 AVN6BB_7_7_EYE_GREEN_LIGHT_CSTM 1 "ON" 0 "OFF" ;
VAL_ 1723 AVN6BB_6_0_CCU_FAIL 1 "FAIL" 0 "NORMAL" ;
VAL_ 1723 AVN6BB_6_1_EYE_P_CR_CSTM 1 "ON" 0 "OFF" ;
VAL_ 1723 AVN6BB_6_2_EYE_ALK_B_LDW_CSTM 3 "ALK-B ON+LDW ON" 2 "ALK-B ON+LDW OFF" 1 "ALK-B OFF+LDW ON" 0 "ALK-B OFF+LDW OFF" ;
VAL_ 1723 AVN6BB_6_4_EYE_CSTM_REQ 1 "required" 0 "NOT required" ;
VAL_ 1723 AVN6BB_6_5_EYE_ELK_CSTM 1 "ON" 0 "OFF" ;
VAL_ 1723 AVN6BB_6_6_EYE_ALKB_EDGE_CSTM 1 "ON" 0 "OFF" ;
VAL_ 1723 AVN6BB_6_7_FCW_ON_OFF 1 "ON" 0 "OFF" ;
VAL_ 1723 AVN6BB_5_0_DMS_SELECT_ID 5 "ID5" 4 "ID4" 3 "ID3" 2 "ID2" 1 "ID1" 0 "DEFAULT" ;
VAL_ 1723 AVN6BB_5_4_TPMS_TH_MODE_CSTM 3 "TPMS3 SW (Towing)" 2 "TPMS2 SW (Loading)" 1 "TPMS1 SW (Normal)" 0 "No Operation" ;
VAL_ 1723 AVN6BB_5_6_DMS_SET_REQ 1 "required" 0 "NOT required" ;
VAL_ 1723 AVN6BB_5_7_DMS_RECOG_SET 1 "RECOG_ON" 0 "RECOG_OFF" ;
VAL_ 1723 AVN6BB_4_0_DMS_EDIT_REQ 15 "Operation Failure" 6 "MANUAL_SCAN" 5 "ID_CUST_DEL" 4 "ID_CUST_SET" 3 "ALL_ID_DEL" 2 "ID_DEL_SELECT" 1 "ID_REGIST" 0 "DEFAULT" ;
VAL_ 1723 AVN6BB_4_4_VEHICLE_DEMO 1 "ON" 0 "OFF (Default)" ;
VAL_ 1723 AVN6BB_4_5_SRVD_CSTM_REQ 1 "required" 0 "NOT required" ;
VAL_ 1723 AVN6BB_4_6_SEAT_RESET_REQ 1 "required" 0 "NOT required" ;
VAL_ 1723 AVN6BB_4_7_SEATAWAY_SET_CSTM 1 "required" 0 "NOT required" ;
VAL_ 1723 AVN6BB_3_0_SRVD_ON_OFF 1 "ON" 0 "OFF" ;
VAL_ 1723 AVN6BB_3_1_PRG_RESET_REQ 1 "required" 0 "NOT required" ;
VAL_ 1723 AVN6BB_3_2_PRG_MEM_CSTM 1 "required" 0 "NOT required" ;
VAL_ 1723 AVN6BB_3_3_DMS_ON_OFF 1 "ON/OFF Change" 0 "invalid" ;
VAL_ 1723 AVN6BB_3_4_MIR_RESET_REQ 1 "required" 0 "NOT required" ;
VAL_ 1723 AVN6BB_3_5_MIR_AFOLD_CSTM 1 "required" 0 "NOT required" ;
VAL_ 1723 AVN6BB_3_6_MIR_RTILT_CSTM 1 "required" 0 "NOT required" ;
VAL_ 1723 AVN6BB_3_7_EYE_TSA_CSTM 1 "TSA Enable(ISA)" 0 "TSA Disable(MSA)" ;
VAL_ 1723 AVN6BB_2_0_AVH_ON_OFF 3 "BLANK_NoInput" 2 "AVH ON_Input" 1 "AVH OFF_Input" 0 "Neutral" ;
VAL_ 1723 AVN6BB_2_2_VDC_ON_OFF 3 "BLANK_NoInput" 2 "VDC ON_Input" 1 "VDC OFF_Input" 0 "Neutral" ;
VAL_ 1723 AVN6BB_2_4_CCU_HALT_RESET 1 "Reset/Halt" 0 "Normal" ;
VAL_ 1723 AVN6BB_2_5_EYE_LDW_TIMING_CSTM 1 "LATE" 0 "EARLY" ;
VAL_ 1723 AVN6BB_2_6_FCW_CSTM 3 "OFF" 2 "FAR" 1 "NEAR" 0 "ON/NORM" ;
VAL_ 1723 AVN6BB_1_4_EYE_WARN_CSTM 1 "Steering Wheel Vibration" 0 "Buzzer" ;
VAL_ 1723 AVN6BB_1_5_EYE_FCTI_CSTM 3 "Reserve" 2 "Display + Sound" 1 "Display" 0 "OFF" ;
VAL_ 1723 AVN6BB_1_7_LDW_WARNING_ON_OFF 1 "ON" 0 "OFF" ;
VAL_ 1722 AVN6BA_7_0_GUIDE_LINE_REAR 1 "ON" 0 "OFF" ;
VAL_ 1722 AVN6BA_7_1_GUIDE_LINE_SIDE 1 "ON" 0 "OFF" ;
VAL_ 1722 AVN6BA_7_2_GUIDE_LINE_FRONT 1 "ON" 0 "OFF" ;
VAL_ 1722 AVN6BA_7_3_STEER_ANGLE_INTERLOCK 1 "ON" 0 "OFF" ;
VAL_ 1722 AVN6BA_7_4_BACK_CAMERA_DELAY 1 "ON" 0 "OFF" ;
VAL_ 1722 AVN6BA_7_5_REQ_STOP_CAMERA_OUT 1 "REQ" 0 "NON_REQ" ;
VAL_ 1722 AVN6BA_7_6_VIEW_CHANGE_SW 3 "NO_DEFINITION" 2 "LONG_PUSH" 1 "SHORT_PUSH" 0 "INVALID" ;
VAL_ 1722 AVN6BA_6_6_CLIMATE_SYNC 1 "ON/OFF Change" 0 "invalid" ;
VAL_ 1722 AVN6BA_6_7_CLIMATE_F_DEF 1 "ON/OFF Change" 0 "invalid" ;
VAL_ 1722 AVN6BA_5_6_CLIMAITE_AUTO 1 "FULL AUTO ON" 0 "invalid" ;
VAL_ 1722 AVN6BA_5_7_CLIMAITE_MAX_AC 1 "ON/OFF Change" 0 "invalid" ;
VAL_ 1722 AVN6BA_4_0_CLIMAITE_VR 4 "Voice recognition" 0 "No voice recognition" ;
VAL_ 1722 AVN6BA_4_3_CLIMATE_AC 1 "ON/OFF Change" 0 "invalid" ;
VAL_ 1722 AVN6BA_4_4_CLIMAITE_FAN 15 "No change" 14 "Reserve" 13 "Reserve" 12 "Reserve" 11 "Reserve" 10 "Reserve" 9 "Reserve" 8 "Reserve" 7 "HI" 6 "M5" 5 "M4" 4 "M3" 3 "M2" 2 "M1" 1 "LO" 0 "invalid" ;
VAL_ 1722 AVN6BA_3_0_PERSONAL_IC_SH 7 "Reserve" 6 "Reserve" 5 "Reserve" 4 "Reserve" 3 "type C" 2 "type B" 1 "type A" 0 "No information" ;
VAL_ 1722 AVN6BA_3_4_CSTM_SONNER 1 "ON" 0 "OFF" ;
VAL_ 1722 AVN6BA_3_5_CSTM_RAB 1 "ON" 0 "OFF" ;
VAL_ 1722 AVN6BA_3_6_REQ_CHG_CSTM_RAB 1 "request" 0 "no request" ;
VAL_ 1722 AVN6BA_3_7_CLIMATE_R_DEF 1 "ON/OFF Change" 0 "invalid" ;
VAL_ 1722 AVN6BA_2_0_CLIMATE_PTC 1 "ON/OFF Change" 0 "invalid" ;
VAL_ 1722 AVN6BA_2_1_CLIMATE_MODE 1 "ON/OFF Change" 0 "invalid" ;
VAL_ 1722 AVN6BA_2_2_CLIMATE_SEAT_C_L 1 "ON/OFF Change" 0 "invalid" ;
VAL_ 1722 AVN6BA_2_3_CLIMATE_SEAT_C_R 1 "ON/OFF Change" 0 "invalid" ;
VAL_ 1722 AVN6BA_2_4_CLIMATE_SEAT_H_L 1 "ON/OFF Change" 0 "invalid" ;
VAL_ 1722 AVN6BA_2_5_CLIMATE_SEAT_H_R 1 "ON/OFF Change" 0 "invalid" ;
VAL_ 1722 AVN6BA_2_6_CLIMATE_INNER_AIR 1 "ON/OFF Change" 0 "invalid" ;
VAL_ 1722 AVN6BA_2_7_CLIMATE_ON_OFF 1 "ON/OFF Change" 0 "invalid" ;
VAL_ 1722 AVN6BA_1_4_CLIMAITE_STATUS 7 "Not Found" 6 "Detected" 5 "Replay" 4 "Loading" 3 "Accepting" 2 "Ready" 1 "Standby" 0 "Start up" ;
VAL_ 1722 AVN6BA_1_7_CLIMAITE_ON_OFF 1 "ON" 0 "OFF" ;
VAL_ 1713 AVN6B1_5_0_FAIL_AVN 1 "improperly" 0 "properly" ;
VAL_ 1713 AVN6B1_5_1_IN_OPERATION 1 "operating" 0 "non operating" ;
VAL_ 1713 AVN6B1_5_2_TYPE_NAVI 3 "High" 2 "Mid" 1 "Base" 0 "Non" ;
VAL_ 1713 AVN6B1_5_4_XM_ENABLE 3 "Reservation" 2 "Reservation" 1 "Receivable" 0 "Non" ;
VAL_ 1713 AVN6B1_5_6_FLG_ABLE_WELCOME_SCL 1 "表示可" 0 "表示不可" ;
VAL_ 1713 AVN6B1_5_7_STEER_ANGLE_INTERLOCK 1 "ON" 0 "OFF" ;
VAL_ 1713 AVN6B1_4_7_BACK_CAMERA_DELAY 1 "ON" 0 "OFF" ;
VAL_ 1713 AVN6B1_3_7_MVS_FTSNR_INTERRUPT 1 "ON" 0 "OFF" ;
VAL_ 1713 AVN6B1_2_0_GPS_CLOCK_FLG 1 "validity" 0 "invalidity" ;
VAL_ 1713 AVN6B1_2_6_TIME_FORMAT 3 "Reserved" 2 "24h" 1 "12h" 0 "Invalid" ;
VAL_ 1713 AVN6B1_1_4_WAKE_UP_FRAME 1 "WakeUP_FRAME" 0 "Normal_FRAME" ;
VAL_ 1713 AVN6B1_1_5_REQ_COMM_CONT 1 "REQ" 0 "NON_REQ" ;
VAL_ 1713 AVN6B1_1_6_ACTIVE_AVN_CSTM 1 "Customize" 0 "Non Customize" ;
VAL_ 1713 AVN6B1_1_7_REQ_STOP_CAMERA_OUT 1 "Request" 0 "No request" ;
